VERSION "dbc-export 1 2026.26.6.5"

NS_ :

BS_:

BU_: ADSP APB APP APS APSB BB BMS CC CMP CMPD CP DAS DI DIF DIR DPB EPAS3P EPAS3S EPASTP EPASTS EPBL EPBR ESP EVSE FC GTW HCML HCMR HVP IBST ICR IDB LS OCS1P ODIN PARK PCS PCS2 PLG PM PMF PMR PNCD PTC RADC RCM RCM2 RCM3 RCU SCCM SCM SCS SDCR TAS TCU TCU2 TPMS TRCM UDS UI UIS UMC USM V2G VC VCBATT VCBATT0 VCBATT1 VCBATT2 VCCC VCFRONT VCFRONT1 VCFRONT2 VCLEFT VCRIGHT VCSEAT2L VCSEAT2R VCSEC VEH

BO_ 1113 APS_warningMatrix2: 8 APS
 SG_ APS_w129_ECU_Power_Issue : 0|1@1+ (1,0) [0|1] "" Vector__XXX
 SG_ APS_w130_ECU_Thermal_Issue : 1|1@1+ (1,0) [0|1] "" Vector__XXX
 SG_ APS_w131_trap_exception : 2|1@1+ (1,0) [0|1] "" Vector__XXX
 SG_ APS_w132_appVersionMismatch : 3|1@1+ (1,0) [0|1] "" Vector__XXX
 SG_ APS_w133_ETHSwitchError : 4|1@1+ (1,0) [0|1] "" Vector__XXX
 SG_ APS_w134_appMia : 5|1@1+ (1,0) [0|1] "" Vector__XXX
 SG_ APS_w135_appCritical : 6|1@1+ (1,0) [0|1] "" Vector__XXX
 SG_ APS_w136_gpsDisabled : 7|1@1+ (1,0) [0|1] "" Vector__XXX
 SG_ APS_w137_gpsFaultReset : 8|1@1+ (1,0) [0|1] "" Vector__XXX
 SG_ APS_w138_gpsComIssue : 9|1@1+ (1,0) [0|1] "" Vector__XXX
 SG_ APS_w139_udpBufferOverflow : 10|1@1+ (1,0) [0|1] "" Vector__XXX
 SG_ APS_w140_vcfrontMiaVehicleBus : 11|1@1+ (1,0) [0|1] "" Vector__XXX
 SG_ APS_w141_rcmMiaPartyBus : 12|1@1+ (1,0) [0|1] "" Vector__XXX
 SG_ APS_w142_diMiaPartyBus : 13|1@1+ (1,0) [0|1] "" Vector__XXX
 SG_ APS_w143_espMiaPartyBus : 14|1@1+ (1,0) [0|1] "" Vector__XXX
 SG_ APS_w144_vcleftMiaPartyBus : 15|1@1+ (1,0) [0|1] "" Vector__XXX
 SG_ APS_w145_vcrightMiaPartyBus : 16|1@1+ (1,0) [0|1] "" Vector__XXX
 SG_ APS_w146_epas3pMiaPartyBus : 17|1@1+ (1,0) [0|1] "" Vector__XXX
 SG_ APS_w147_vcleftMiaVehBus : 18|1@1+ (1,0) [0|1] "" Vector__XXX
 SG_ APS_w148_vcrightMiaVehBus : 19|1@1+ (1,0) [0|1] "" Vector__XXX
 SG_ APS_w149_epblMiaVehBus : 20|1@1+ (1,0) [0|1] "" Vector__XXX
 SG_ APS_w150_sccmMiaVehBus : 21|1@1+ (1,0) [0|1] "" Vector__XXX
 SG_ APS_w151_apRecovered : 22|1@1+ (1,0) [0|1] "" Vector__XXX
 SG_ APS_w152_gpsFusionStatus : 23|1@1+ (1,0) [0|1] "" Vector__XXX
 SG_ APS_w153_eacInhibit : 24|1@1+ (1,0) [0|1] "" Vector__XXX
 SG_ APS_w155_ethLwipError : 26|1@1+ (1,0) [0|1] "" Vector__XXX
 SG_ APS_w156_lwipAssert : 27|1@1+ (1,0) [0|1] "" Vector__XXX
 SG_ APS_w157_autopilotReboot : 28|1@1+ (1,0) [0|1] "" Vector__XXX
 SG_ APS_w158_apbMia : 29|1@1+ (1,0) [0|1] "" Vector__XXX
 SG_ APS_w159_apbCritical : 30|1@1+ (1,0) [0|1] "" Vector__XXX
 SG_ APS_w160_apbVersionMismatch : 31|1@1+ (1,0) [0|1] "" Vector__XXX
 SG_ APS_w161_gpsAntennaDisconnected : 32|1@1+ (1,0) [0|1] "" Vector__XXX
 SG_ APS_w162_TurboA_DisRegPgoodErr : 33|1@1+ (1,0) [0|1] "" Vector__XXX
 SG_ APS_w163_TurboA_DisRegNFault : 34|1@1+ (1,0) [0|1] "" Vector__XXX
 SG_ APS_w164_TurboA_12VFuseFault : 35|1@1+ (1,0) [0|1] "" Vector__XXX
 SG_ APS_w165_TurboA_Temp_NOS : 36|1@1+ (1,0) [0|1] "" Vector__XXX
 SG_ APS_w166_TurboA_SMSLockStepErr : 37|1@1+ (1,0) [0|1] "" Vector__XXX
 SG_ APS_w167_TurboA_TMU_Throttle : 38|1@1+ (1,0) [0|1] "" Vector__XXX
 SG_ APS_w168_TurboA_SMS_WDOG : 39|1@1+ (1,0) [0|1] "" Vector__XXX
 SG_ APS_w169_TurboA_SCS_LKUP : 40|1@1+ (1,0) [0|1] "" Vector__XXX
 SG_ APS_w170_TurboA_A72_watchdog : 41|1@1+ (1,0) [0|1] "" Vector__XXX
 SG_ APS_w171_TurboA_SMS_taskUtilErr : 42|1@1+ (1,0) [0|1] "" Vector__XXX
 SG_ APS_w172_apFeaturesUnavailable : 43|1@1+ (1,0) [0|1] "" Vector__XXX
 SG_ APS_w178_TurboB_DisRegPgoodErr : 49|1@1+ (1,0) [0|1] "" Vector__XXX
 SG_ APS_w179_TurboB_DisRegNFault : 50|1@1+ (1,0) [0|1] "" Vector__XXX
 SG_ APS_w180_TurboB_12VFuseFault : 51|1@1+ (1,0) [0|1] "" Vector__XXX
 SG_ APS_w181_TurboB_Temp_NOS : 52|1@1+ (1,0) [0|1] "" Vector__XXX
 SG_ APS_w182_TurboB_SMSLockStepErr : 53|1@1+ (1,0) [0|1] "" Vector__XXX
 SG_ APS_w183_TurboB_TMU_Throttle : 54|1@1+ (1,0) [0|1] "" Vector__XXX
 SG_ APS_w184_TurboB_SMS_WDOG : 55|1@1+ (1,0) [0|1] "" Vector__XXX
 SG_ APS_w185_TurboB_SCS_LKUP : 56|1@1+ (1,0) [0|1] "" Vector__XXX
 SG_ APS_w186_TurboB_A72_watchdog : 57|1@1+ (1,0) [0|1] "" Vector__XXX
 SG_ APS_w187_TurboB_SMS_taskUtilErr : 58|1@1+ (1,0) [0|1] "" Vector__XXX
 SG_ APS_w188_otherTurboUartMIA : 59|1@1+ (1,0) [0|1] "" Vector__XXX
 SG_ APS_w189_vcfrontMiaPartyBus : 60|1@1+ (1,0) [0|1] "" Vector__XXX
 SG_ APS_w190_iboosterMia : 61|1@1+ (1,0) [0|1] "" Vector__XXX
 SG_ APS_w191_timesyncError : 62|1@1+ (1,0) [0|1] "" Vector__XXX
 SG_ APS_w192_CANFault : 63|1@1+ (1,0) [0|1] "" Vector__XXX

BO_ 848 APS_warningMatrix3: 8 APS
 SG_ APS_w193_camWindshieldUnclean : 0|1@1+ (1,0) [0|1] "" Vector__XXX
 SG_ APS_w194_accDriverResumeRqrd : 1|1@1+ (1,0) [0|1] "" Vector__XXX
 SG_ APS_w195_scwUnavailable : 2|1@1+ (1,0) [0|1] "" Vector__XXX
 SG_ APS_w196_stopSignWarning : 3|1@1+ (1,0) [0|1] "" Vector__XXX
 SG_ APS_w197_redLightWarning : 4|1@1+ (1,0) [0|1] "" Vector__XXX
 SG_ APS_w198_tsrUnavailable : 5|1@1+ (1,0) [0|1] "" Vector__XXX
 SG_ APS_w199_apcAbort : 6|1@1+ (1,0) [0|1] "" Vector__XXX
 SG_ APS_w200_lcSlowdown : 7|1@1+ (1,0) [0|1] "" Vector__XXX
 SG_ APS_w201_lcAborting : 8|1@1+ (1,0) [0|1] "" Vector__XXX
 SG_ APS_w202_scwNoisyEnvironment : 9|1@1+ (1,0) [0|1] "" Vector__XXX
 SG_ APS_w203_apcActivation : 10|1@1+ (1,0) [0|1] "" Vector__XXX
 SG_ APS_w204_apcFinalFront : 11|1@1+ (1,0) [0|1] "" Vector__XXX
 SG_ APS_w205_apcFinalRear : 12|1@1+ (1,0) [0|1] "" Vector__XXX
 SG_ APS_w206_autosteerNotEnabled : 13|1@1+ (1,0) [0|1] "" Vector__XXX
 SG_ APS_w207_autosteerUnavailable : 14|1@1+ (1,0) [0|1] "" Vector__XXX
 SG_ APS_w208_rackDetected : 15|1@1+ (1,0) [0|1] "" Vector__XXX
 SG_ APS_w209_autoSummonRequest : 16|1@1+ (1,0) [0|1] "" Vector__XXX
 SG_ APS_w210_camObstrcted : 17|1@1+ (1,0) [0|1] "" Vector__XXX
 SG_ APS_w211_accNoSeatBelt : 18|1@1+ (1,0) [0|1] "" Vector__XXX
 SG_ APS_w212_lcUnavailableStrikeOut : 19|1@1+ (1,0) [0|1] "" Vector__XXX
 SG_ APS_w213_autosteerStruckOut : 20|1@1+ (1,0) [0|1] "" Vector__XXX
 SG_ APS_w214_driverNotIntracting : 21|1@1+ (1,0) [0|1] "" Vector__XXX
 SG_ APS_w215_contDriverNotIntracting : 22|1@1+ (1,0) [0|1] "" Vector__XXX
 SG_ APS_w216_driverOverriding : 23|1@1+ (1,0) [0|1] "" Vector__XXX
 SG_ APS_w217_lcUnavailableSpeeding : 24|1@1+ (1,0) [0|1] "" Vector__XXX
 SG_ APS_w218_lcSpeedExceededLimit : 25|1@1+ (1,0) [0|1] "" Vector__XXX
 SG_ APS_w219_lcTempUnavailableSpeed : 26|1@1+ (1,0) [0|1] "" Vector__XXX
 SG_ APS_w220_lcTempUnavailableRoad : 27|1@1+ (1,0) [0|1] "" Vector__XXX
 SG_ APS_w221_accRadarBlind : 28|1@1+ (1,0) [0|1] "" Vector__XXX
 SG_ APS_w222_accCameraBlind : 29|1@1+ (1,0) [0|1] "" Vector__XXX
 SG_ APS_w223_accObjectInPath : 30|1@1+ (1,0) [0|1] "" Vector__XXX
 SG_ APS_w224_accCameraCalibration : 31|1@1+ (1,0) [0|1] "" Vector__XXX
 SG_ APS_w225_lcDegradedVisSpeedLmt : 32|1@1+ (1,0) [0|1] "" Vector__XXX
 SG_ APS_w226_lcCamCalNeededSpeedLmt : 33|1@1+ (1,0) [0|1] "" Vector__XXX
 SG_ APS_w227_virtualWallBlocked : 34|1@1+ (1,0) [0|1] "" Vector__XXX
 SG_ APS_w228_DEPRECATED : 35|1@1+ (1,0) [0|1] "" Vector__XXX
 SG_ APS_w229_alcUltrasoundDamaged : 36|1@1+ (1,0) [0|1] "" Vector__XXX
 SG_ APS_w230_alcUltrasoundBlocked : 37|1@1+ (1,0) [0|1] "" Vector__XXX
 SG_ APS_w231_idfEvent : 38|1@1+ (1,0) [0|1] "" Vector__XXX
 SG_ APS_w232_laneChangeRequested : 39|1@1+ (1,0) [0|1] "" Vector__XXX
 SG_ APS_w235_a72LoopDetected : 42|1@1+ (1,0) [0|1] "" Vector__XXX
 SG_ APS_w236_canSharedMemError : 43|1@1+ (1,0) [0|1] "" Vector__XXX
 SG_ APS_w237_faultMgrEventDetected : 44|1@1+ (1,0) [0|1] "" Vector__XXX
 SG_ APS_w238_resetReason : 45|1@1+ (1,0) [0|1] "" Vector__XXX
 SG_ APS_w241_ddrInitFailures : 48|1@1+ (1,0) [0|1] "" Vector__XXX
 SG_ APS_w242_tripMBISTFailure : 49|1@1+ (1,0) [0|1] "" Vector__XXX
 SG_ APS_w243_tripHWErrorStatus : 50|1@1+ (1,0) [0|1] "" Vector__XXX
 SG_ APS_w244_gpuHWFaultStatus : 51|1@1+ (1,0) [0|1] "" Vector__XXX
 SG_ APS_w245_eloopRxFromUnexpectedSo : 52|1@1+ (1,0) [0|1] "" Vector__XXX
 SG_ APS_w246_ethloopSwitchPortLinkDo : 53|1@1+ (1,0) [0|1] "" Vector__XXX
 SG_ APS_w247_ethernetFrameError : 54|1@1+ (1,0) [0|1] "" Vector__XXX
 SG_ APS_w248_ethloopSwitchPoorSqi : 55|1@1+ (1,0) [0|1] "" Vector__XXX
 SG_ APS_w249_ufsFailures : 56|1@1+ (1,0) [0|1] "" Vector__XXX
 SG_ APS_w250_ethloopSwitchMemUsageTo : 57|1@1+ (1,0) [0|1] "" Vector__XXX
 SG_ APS_w251_ethloopSwitchMemUsageTo : 58|1@1+ (1,0) [0|1] "" Vector__XXX
 SG_ APS_w252_ethSwitchPortLinkDown : 59|1@1+ (1,0) [0|1] "" Vector__XXX
 SG_ APS_w253_powerStateTimeout : 60|1@1+ (1,0) [0|1] "" Vector__XXX
 SG_ APS_w254_sleepStateTimeout : 61|1@1+ (1,0) [0|1] "" Vector__XXX
 SG_ APS_w255_bootHealth : 62|1@1+ (1,0) [0|1] "" Vector__XXX

BO_ 784 APS_warningMatrix4: 8 APS
 SG_ APS_w257_assertFailure : 0|1@1+ (1,0) [0|1] "" Vector__XXX
 SG_ APS_w258_qspiFlashSectorChecksum : 1|1@1+ (1,0) [0|1] "" Vector__XXX
 SG_ APS_w259_qspiFailure : 2|1@1+ (1,0) [0|1] "" Vector__XXX
 SG_ APS_w260_pgoodFailure : 3|1@1+ (1,0) [0|1] "" Vector__XXX
 SG_ APS_w261_vrmFaultGrpA : 4|1@1+ (1,0) [0|1] "" Vector__XXX
 SG_ APS_w262_vrmFaultGrpB : 5|1@1+ (1,0) [0|1] "" Vector__XXX
 SG_ APS_w263_vrmFaultGrpC : 6|1@1+ (1,0) [0|1] "" Vector__XXX
 SG_ APS_w264_ddrPhy0Failures : 7|1@1+ (1,0) [0|1] "" Vector__XXX
 SG_ APS_w265_ddrPhy1Failures : 8|1@1+ (1,0) [0|1] "" Vector__XXX
 SG_ APS_w266_ddrPhy2Failures : 9|1@1+ (1,0) [0|1] "" Vector__XXX
 SG_ APS_w267_ddrPhy3Failures : 10|1@1+ (1,0) [0|1] "" Vector__XXX
 SG_ APS_w268_ddrControllerFailures : 11|1@1+ (1,0) [0|1] "" Vector__XXX
 SG_ APS_w269_ethSwitchRxPageCountToo : 12|1@1+ (1,0) [0|1] "" Vector__XXX
 SG_ APS_w270_ethSwitchRxPageCountToo : 13|1@1+ (1,0) [0|1] "" Vector__XXX
 SG_ APS_w271_ddrScheduler0EccErrors : 14|1@1+ (1,0) [0|1] "" Vector__XXX
 SG_ APS_w272_ddrScheduler1EccErrors : 15|1@1+ (1,0) [0|1] "" Vector__XXX
 SG_ APS_w273_ddrScheduler2EccErrors : 16|1@1+ (1,0) [0|1] "" Vector__XXX
 SG_ APS_w274_ddrScheduler3EccErrors : 17|1@1+ (1,0) [0|1] "" Vector__XXX
 SG_ APS_w275_ddrScheduler4EccErrors : 18|1@1+ (1,0) [0|1] "" Vector__XXX
 SG_ APS_w276_ddrScheduler5EccErrors : 19|1@1+ (1,0) [0|1] "" Vector__XXX
 SG_ APS_w277_ddrScheduler6EccErrors : 20|1@1+ (1,0) [0|1] "" Vector__XXX
 SG_ APS_w278_ddrScheduler7EccErrors : 21|1@1+ (1,0) [0|1] "" Vector__XXX
 SG_ APS_w279_ufsPartitionError : 22|1@1+ (1,0) [0|1] "" Vector__XXX
 SG_ APS_w280_pepsMia : 23|1@1+ (1,0) [0|1] "" Vector__XXX
 SG_ APS_w281_rsaMia : 24|1@1+ (1,0) [0|1] "" Vector__XXX
 SG_ APS_w282_smmuError : 25|1@1+ (1,0) [0|1] "" Vector__XXX
 SG_ APS_w283_psfaMia : 26|1@1+ (1,0) [0|1] "" Vector__XXX
 SG_ APS_w284_cam12VBuckBoostAPwrIssu : 27|1@1+ (1,0) [0|1] "" Vector__XXX
 SG_ APS_w285_cam12VBuckBoostBPwrIssu : 28|1@1+ (1,0) [0|1] "" Vector__XXX
 SG_ APS_w286_cam12VEFuseAPrimaryIssu : 29|1@1+ (1,0) [0|1] "" Vector__XXX
 SG_ APS_w287_cam12VEFuseASecondaryIs : 30|1@1+ (1,0) [0|1] "" Vector__XXX
 SG_ APS_w288_brakeboosterMia : 31|1@1+ (1,0) [0|1] "" Vector__XXX
 SG_ APS_w289_turboTemperatureWarning : 32|1@1+ (1,0) [0|1] "" Vector__XXX
 SG_ APS_w290_cam12VBuckBoostBPwrRing : 33|1@1+ (1,0) [0|1] "" Vector__XXX
 SG_ APS_w291_eplannerError : 34|1@1+ (1,0) [0|1] "" Vector__XXX
 SG_ APS_w292_CH_busOff : 35|1@1+ (1,0) [0|1] "" Vector__XXX
 SG_ APS_w293_PARTY_busOff : 36|1@1+ (1,0) [0|1] "" Vector__XXX
 SG_ APS_w294_VEH_busOff : 37|1@1+ (1,0) [0|1] "" Vector__XXX
 SG_ APS_w295_PT_busOff : 38|1@1+ (1,0) [0|1] "" Vector__XXX
 SG_ APS_w296_wdogMonTaskDeadlineMiss : 39|1@1+ (1,0) [0|1] "" Vector__XXX
 SG_ APS_w297_earlyWDogAlert : 40|1@1+ (1,0) [0|1] "" Vector__XXX
 SG_ APS_w298_cpuToApCanSharedMemErro : 41|1@1+ (1,0) [0|1] "" Vector__XXX
 SG_ APS_w299_apToCpuCanSharedMemErro : 42|1@1+ (1,0) [0|1] "" Vector__XXX
 SG_ APS_w300_sharedMemoryAccessError : 43|1@1+ (1,0) [0|1] "" Vector__XXX
 SG_ APS_w301_nocTimeoutDetected : 44|1@1+ (1,0) [0|1] "" Vector__XXX
 SG_ APS_w302_canAPShmFifoFull : 45|1@1+ (1,0) [0|1] "" Vector__XXX
 SG_ APS_w303_canAPShmFifoEmpty : 46|1@1+ (1,0) [0|1] "" Vector__XXX
 SG_ APS_w304_dataAbort : 47|1@1+ (1,0) [0|1] "" Vector__XXX
 SG_ APS_w305_gpsPgoodFailure : 48|1@1+ (1,0) [0|1] "" Vector__XXX
 SG_ APS_w306_ethPgoodFailure : 49|1@1+ (1,0) [0|1] "" Vector__XXX
 SG_ APS_w307_eccEventDetected : 50|1@1+ (1,0) [0|1] "" Vector__XXX
 SG_ APS_w308_pmicErrorDetected : 51|1@1+ (1,0) [0|1] "" Vector__XXX
 SG_ APS_w309_ethBridgeDown : 52|1@1+ (1,0) [0|1] "" Vector__XXX
 SG_ APS_w310_wakeBootMetrics : 53|1@1+ (1,0) [0|1] "" Vector__XXX
 SG_ APS_w311_apbdgDasMia : 54|1@1+ (1,0) [0|1] "" Vector__XXX
 SG_ APS_w312_apbdgApMia : 55|1@1+ (1,0) [0|1] "" Vector__XXX
 SG_ APS_w313_BDY_busOff : 56|1@1+ (1,0) [0|1] "" Vector__XXX
 SG_ APS_w315_epas3pMiaBdyBus : 58|1@1+ (1,0) [0|1] "" Vector__XXX
 SG_ APS_w316_apBootHealth : 59|1@1+ (1,0) [0|1] "" Vector__XXX
 SG_ APS_w317_uiMia : 60|1@1+ (1,0) [0|1] "" Vector__XXX
 SG_ APS_w318_ethernetNetworkBufferHi : 61|1@1+ (1,0) [0|1] "" Vector__XXX
 SG_ APS_w319_vehDasImposterDetected : 62|1@1+ (1,0) [0|1] "" Vector__XXX
 SG_ APS_w320_eplannerPreconditionsMe : 63|1@1+ (1,0) [0|1] "" Vector__XXX

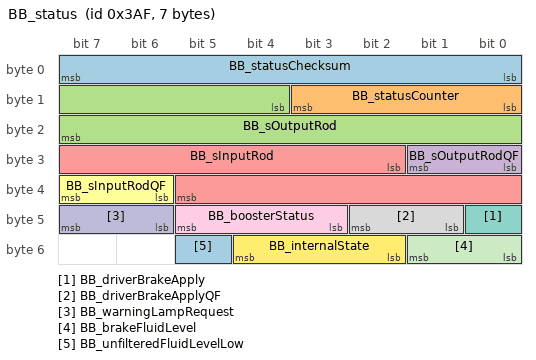
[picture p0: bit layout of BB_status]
BO_ 943 BB_status: 7 BB
 SG_ BB_statusChecksum : 0|8@1+ (1,0) [0|255] "" Vector__XXX
 SG_ BB_statusCounter : 8|4@1+ (1,0) [0|15] "" Vector__XXX
 SG_ BB_sOutputRod : 12|12@1+ (0.015625,-5) [-5|47] "mm" Vector__XXX
 SG_ BB_sOutputRodQF : 24|2@1+ (1,0) [0|3] "" Vector__XXX
 SG_ BB_sInputRod : 26|12@1+ (0.015625,-5) [-5|47] "mm" Vector__XXX
 SG_ BB_sInputRodQF : 38|2@1+ (1,0) [0|3] "" Vector__XXX
 SG_ BB_driverBrakeApply : 40|1@1+ (1,0) [0|1] "" Vector__XXX
 SG_ BB_driverBrakeApplyQF : 41|2@1+ (1,0) [0|3] "" Vector__XXX
 SG_ BB_boosterStatus : 43|3@1+ (1,0) [0|7] "" Vector__XXX
 SG_ BB_warningLampRequest : 46|2@1+ (1,0) [0|3] "" Vector__XXX
 SG_ BB_brakeFluidLevel : 48|2@1+ (1,0) [0|3] "" Vector__XXX
 SG_ BB_internalState : 50|3@1+ (1,0) [0|7] "" Vector__XXX
 SG_ BB_unfilteredFluidLevelLow : 53|1@1+ (1,0) [0|1] "" Vector__XXX

BO_ 1343 BMS_alertLog: 8 BMS
 SG_ BMS_alertID M : 0|9@1+ (1,0) [0|511] "" Vector__XXX
 SG_ BMS_alertSet : 15|1@1+ (1,0) [0|1] "" Vector__XXX
 SG_ BMS_a001_gatewayPackEnergy m1 : 16|2@1+ (1,0) [0|3] "" Vector__XXX
 SG_ BMS_a001_expectedPackEnergy m1 : 18|2@1+ (1,0) [0|3] "" Vector__XXX
 SG_ BMS_a002_gatewayPackPerformanceD m2 : 16|3@1+ (1,0) [0|7] "" Vector__XXX
 SG_ BMS_a002_expectedPackPerformance m2 : 19|3@1+ (1,0) [0|7] "" Vector__XXX
 SG_ BMS_a002_bmsPackMass m2 : 24|8@1+ (1,300) [300|555] "kg" Vector__XXX
 SG_ BMS_a003_calBlockData_0 m3 : 16|32@1+ (1,0) [0|4294967295] "" Vector__XXX
 SG_ BMS_a017_packCurrent m17 : 16|8@1+ (8,-1500) [-1500|540] "A" Vector__XXX
 SG_ BMS_a017_ovBrickVID m17 : 24|7@1+ (1,1) [1|128] "" Vector__XXX
 SG_ BMS_a017_ovBrickV m17 : 32|16@1+ (7.62939453125e-05,0) [0|4.99992370605] "V" Vector__XXX
 SG_ BMS_a018_packCurrent m18 : 16|8@1+ (8,-1496) [-1496|544] "A" Vector__XXX
 SG_ BMS_a018_uvBrickVID m18 : 24|7@1+ (1,1) [1|128] "" Vector__XXX
 SG_ BMS_a018_uvBrickV m18 : 32|16@1+ (7.62939453125e-05,0) [0|4.99992370605] "V" Vector__XXX
 SG_ BMS_a019_coolantInletT m19 : 16|8@1+ (0.4,-20) [-20|82] "C" Vector__XXX
 SG_ BMS_a019_activeCoolingTarget m19 : 24|8@1+ (0.4,-20) [-20|82] "C" Vector__XXX
 SG_ BMS_a019_maxBrickT m19 : 32|8@1+ (0.4,-20) [-20|82] "C" Vector__XXX
 SG_ BMS_a019_maxBrickTID m19 : 40|5@1+ (1,1) [1|32] "" Vector__XXX
 SG_ BMS_a021_chargeViolation m21 : 16|1@1+ (1,0) [0|1] "" Vector__XXX
 SG_ BMS_a021_currentLimit m21 : 24|8@1+ (8,-1496) [-1496|544] "A" Vector__XXX
 SG_ BMS_a021_packCurrent m21 : 32|8@1+ (8,-1496) [-1496|544] "A" Vector__XXX
 SG_ BMS_a022_chargeAccumulatorViolat m22 : 16|1@1+ (1,0) [0|1] "" Vector__XXX
 SG_ BMS_a022_chargeAccumulatorValue m22 : 17|23@1+ (10,0) [0|83886070] "A^2s" Vector__XXX
 SG_ BMS_a022_chargeAccumulatorLimit m22 : 40|23@1+ (10,0) [0|83886070] "A^2s" Vector__XXX
 SG_ BMS_a023_ovStackDeviceID m23 : 16|5@1+ (1,1) [1|32] "-" Vector__XXX
 SG_ BMS_a023_ovStackV m23 : 24|16@1+ (0.00128,0) [0|83.8848] "V" Vector__XXX
 SG_ BMS_a024_brickID m24 : 16|8@1+ (1,1) [1|256] "-" Vector__XXX
 SG_ BMS_a024_deltaV m24 : 24|16@1- (0.0001,0) [-3.2768|3.2767] "V" Vector__XXX
 SG_ BMS_a024_avgDvPrev m24 : 40|16@1- (0.0001,0) [-3.2768|3.2767] "V" Vector__XXX
 SG_ BMS_a024_packCurrent m24 : 56|8@1+ (8,-1500) [-1500|540] "A" Vector__XXX
 SG_ BMS_a027_swIsolationCount m27 : 16|8@1+ (1,0) [0|255] "" Vector__XXX
 SG_ BMS_a030_worstBrickID m30 : 16|8@1+ (1,1) [1|256] "" Vector__XXX
 SG_ BMS_a030_maxBrickImpedance m30 : 24|10@1+ (0.1,0) [0|102.3] "mOhm" Vector__XXX
 SG_ BMS_a030_maxNormalizedImpedanceD m30 : 34|7@1+ (0.04,0) [0|5.08] "Ratio" Vector__XXX
 SG_ BMS_a030_faultThreshold m30 : 41|7@1+ (0.04,0) [0|5.08] "Ratio" Vector__XXX
 SG_ BMS_a030_numBricks m30 : 48|8@1+ (1,0) [0|255] "" Vector__XXX
 SG_ BMS_a030_worstBrickSoc m30 : 56|8@1+ (0.5,0) [0|127.5] "PCT" Vector__XXX
 SG_ BMS_a035_isoR m35 : 16|9@1+ (10,0) [0|5110] "kOhm" Vector__XXX
 SG_ BMS_a035_mode m35 : 25|3@1+ (1,0) [0|7] "" Vector__XXX
 SG_ BMS_a035_activeSideVNoR m35 : 28|9@1+ (1,0) [0|511] "V" Vector__XXX
 SG_ BMS_a035_activeSideVWithR m35 : 37|9@1+ (1,0) [0|511] "V" Vector__XXX
 SG_ BMS_a035_passiveSideVNoR m35 : 46|9@1+ (1,0) [0|511] "V" Vector__XXX
 SG_ BMS_a035_passiveSideVWithR m35 : 55|9@1+ (1,0) [0|511] "V" Vector__XXX
 SG_ BMS_a039_dcLinkVoltage m39 : 16|10@1+ (1,0) [0|1023] "V" Vector__XXX
 SG_ BMS_a039_packVoltage m39 : 26|10@1+ (1,0) [0|1023] "V" Vector__XXX
 SG_ BMS_a039_packContactorState m39 : 36|4@1+ (1,0) [1|15] "" Vector__XXX
 SG_ BMS_a039_packCurrent m39 : 40|8@1+ (8,-1496) [-1496|544] "A" Vector__XXX
 SG_ BMS_a039_maxBrickV m39 : 48|8@1+ (0.01,2) [2|4.55] "V" Vector__XXX
 SG_ BMS_a039_state m39 : 56|4@1+ (1,0) [0|15] "" Vector__XXX
 SG_ BMS_a041_resetType m41 : 16|4@1+ (1,0) [0|15] "" Vector__XXX
 SG_ BMS_a050_MIA_numBadReadings m50 : 16|8@1+ (1,0) [0|255] "" Vector__XXX
 SG_ BMS_a050_MIA_numSnaReadings m50 : 24|8@1+ (1,0) [0|255] "" Vector__XXX
 SG_ BMS_a050_MIA_brickId m50 : 32|8@1+ (1,1) [1|256] "" Vector__XXX
 SG_ BMS_a051_hvp1V5Ref m51 : 16|12@1+ (0.001,0) [0|4.095] "V" Vector__XXX
 SG_ BMS_a051_hvp3V0Ref m51 : 28|12@1+ (0.001,0) [0|4.095] "V" Vector__XXX
 SG_ BMS_a051_bms3V0Ref m51 : 40|12@1+ (0.001,0) [0|4.095] "V" Vector__XXX
 SG_ BMS_a059_sumBrickVoltages m59 : 16|16@1+ (0.01,0) [0|655.35] "V" Vector__XXX
 SG_ BMS_a059_packVoltage m59 : 32|16@1+ (0.01,0) [0|655.35] "V" Vector__XXX
 SG_ BMS_a062_state m62 : 16|4@1+ (1,0) [0|15] "" Vector__XXX
 SG_ BMS_a062_minBrickVId m62 : 24|7@1+ (1,1) [1|128] "" Vector__XXX
 SG_ BMS_a062_minBrickVoltage m62 : 32|12@1+ (0.002,0) [0|8.19] "V" Vector__XXX
 SG_ BMS_a062_maxBrickVId m62 : 44|7@1+ (1,1) [1|128] "" Vector__XXX
 SG_ BMS_a062_maxBrickVoltage m62 : 51|12@1+ (0.002,0) [0|8.19] "V" Vector__XXX
 SG_ BMS_a063_cpFaultInV m63 : 16|12@1+ (0.001,0) [0|4.095] "V" Vector__XXX
 SG_ BMS_a064_minBrickSOCID m64 : 16|7@1+ (1,1) [1|128] "" Vector__XXX
 SG_ BMS_a064_minBrickSOC m64 : 24|8@1+ (0.5,0) [0|127.5] "PCT" Vector__XXX
 SG_ BMS_a064_maxBrickSOCID m64 : 32|7@1+ (1,1) [1|128] "" Vector__XXX
 SG_ BMS_a064_maxBrickSOC m64 : 40|8@1+ (0.5,0) [0|127.5] "PCT" Vector__XXX
 SG_ BMS_a064_avgBrickSOC m64 : 48|8@1+ (0.5,0) [0|127.5] "PCT" Vector__XXX
 SG_ BMS_a065_minBrickCacId m65 : 16|7@1+ (1,1) [1|128] "" Vector__XXX
 SG_ BMS_a065_minBrickCac m65 : 24|13@1+ (0.1,0) [0|819.1] "Ah" Vector__XXX
 SG_ BMS_a065_avgBrickCac m65 : 40|13@1+ (0.1,0) [0|819.1] "Ah" Vector__XXX
 SG_ BMS_a065_modCacImbalancePct m65 : 53|10@1+ (0.1,0) [0|102.3] "%" Vector__XXX
 SG_ BMS_a066_minBrickSocId m66 : 16|7@1+ (1,1) [1|128] "" Vector__XXX
 SG_ BMS_a066_minBrickSocByOcvMax m66 : 24|8@1+ (0.5,0) [0|127.5] "PCT" Vector__XXX
 SG_ BMS_a066_maxBrickSocId m66 : 32|7@1+ (1,1) [1|128] "" Vector__XXX
 SG_ BMS_a066_maxBrickSocByOcvMin m66 : 40|8@1+ (0.5,0) [0|127.5] "PCT" Vector__XXX
 SG_ BMS_a066_maxBrickSoc m66 : 48|8@1+ (0.5,0) [0|127.5] "PCT" Vector__XXX
 SG_ BMS_a066_avgBrickSoc m66 : 56|8@1+ (0.5,0) [0|127.5] "PCT" Vector__XXX
 SG_ BMS_a067_minBrickCacId m67 : 16|7@1+ (1,1) [1|128] "" Vector__XXX
 SG_ BMS_a067_minBrickCac m67 : 24|13@1+ (0.1,0) [0|819.1] "Ah" Vector__XXX
 SG_ BMS_a067_avgBrickCac m67 : 40|13@1+ (0.1,0) [0|819.1] "Ah" Vector__XXX
 SG_ BMS_a067_modCacImbalancePct m67 : 53|10@1+ (0.1,0) [0|102.3] "%" Vector__XXX
 SG_ BMS_a068_minBrickCacId m68 : 16|7@1+ (1,1) [1|128] "" Vector__XXX
 SG_ BMS_a068_minBrickCac m68 : 24|13@1+ (0.1,0) [0|819.1] "Ah" Vector__XXX
 SG_ BMS_a068_avgBrickCac m68 : 40|13@1+ (0.1,0) [0|819.1] "Ah" Vector__XXX
 SG_ BMS_a068_modCacImbalancePct m68 : 53|10@1+ (0.1,0) [0|102.3] "%" Vector__XXX
 SG_ BMS_a069_dischargePowerPackVolta m69 : 16|8@1- (0.025,-3.15) [-6.35|0.025] "kW" Vector__XXX
 SG_ BMS_a069_dischargePowerBrickVolt m69 : 24|8@1- (0.005,-0.63) [-1.27|0.005] "kW" Vector__XXX
 SG_ BMS_a069_SOC m69 : 32|8@1+ (0.05,0) [0|12.75] "PCT" Vector__XXX
 SG_ BMS_a069_minBrickT m69 : 40|8@1- (0.5,24) [-40|87.5] "DegC" Vector__XXX
 SG_ BMS_a069_minBrickVLimit m69 : 48|8@1+ (0.01,2) [2|4.55] "V" Vector__XXX
 SG_ BMS_a069_minBrickV m69 : 56|8@1+ (0.01,2) [2|4.55] "V" Vector__XXX
 SG_ BMS_a070_state m70 : 16|4@1+ (1,0) [0|15] "" Vector__XXX
 SG_ BMS_a070_minBrickVId m70 : 24|7@1+ (1,1) [1|128] "" Vector__XXX
 SG_ BMS_a070_minBrickVoltage m70 : 32|12@1+ (0.002,0) [0|8.19] "V" Vector__XXX
 SG_ BMS_a070_maxBrickVId m70 : 44|7@1+ (1,1) [1|128] "" Vector__XXX
 SG_ BMS_a070_maxBrickVoltage m70 : 51|12@1+ (0.002,0) [0|8.19] "V" Vector__XXX
 SG_ BMS_a071_stateRequest m71 : 16|4@1+ (1,0) [0|15] "" Vector__XXX
 SG_ BMS_a071_state m71 : 20|4@1+ (1,0) [0|15] "" Vector__XXX
 SG_ BMS_a071_transitionAlertId m71 : 24|10@1+ (1,0) [0|1023] "" Vector__XXX
 SG_ BMS_a074_maxBrickVTarget m74 : 16|8@1+ (0.01,2) [2|4.55] "V" Vector__XXX
 SG_ BMS_a074_maxBrickV m74 : 24|8@1+ (0.01,2) [2|4.55] "V" Vector__XXX
 SG_ BMS_a075_chargeType m75 : 16|1@1+ (1,0) [0|1] "" Vector__XXX
 SG_ BMS_a076_netAh m76 : 16|21@1- (0.01,0) [-10485.76|10485.75] "Ah" Vector__XXX
 SG_ BMS_a076_tetheringActive m76 : 37|1@1+ (1,0) [0|1] "" Vector__XXX
 SG_ BMS_a077_chargeErrType m77 : 16|1@1+ (1,0) [0|1] "" Vector__XXX
 SG_ BMS_a077_maxBrickVTarget m77 : 24|8@1+ (0.01,2) [2|4.55] "V" Vector__XXX
 SG_ BMS_a077_maxBrickV m77 : 32|8@1+ (0.01,2) [2|4.55] "V" Vector__XXX
 SG_ BMS_a077_packTargetCurrent m77 : 40|8@1+ (8,-1496) [-1496|544] "A" Vector__XXX
 SG_ BMS_a077_packCurrent m77 : 48|8@1+ (8,-1496) [-1496|544] "A" Vector__XXX
 SG_ BMS_a078_peakDchInChg m78 : 16|16@1- (0.1,0) [-3276.8|3276.7] "A" Vector__XXX
 SG_ BMS_a079_maxBrickVTarget m79 : 16|8@1+ (0.01,2) [2|4.55] "V" Vector__XXX
 SG_ BMS_a079_maxBrickV m79 : 24|8@1+ (0.01,2) [2|4.55] "V" Vector__XXX
 SG_ BMS_a081_stateRequest m81 : 16|4@1+ (1,0) [0|15] "" Vector__XXX
 SG_ BMS_a081_firstBlockingAlertId m81 : 20|9@1+ (1,0) [0|511] "" Vector__XXX
 SG_ BMS_a081_secondBlockingAlertId m81 : 29|9@1+ (1,0) [0|511] "" Vector__XXX
 SG_ BMS_a081_thirdBlockingAlertId m81 : 38|9@1+ (1,0) [0|511] "" Vector__XXX
 SG_ BMS_a081_fourthBlockingAlertId m81 : 47|9@1+ (1,0) [0|511] "" Vector__XXX
 SG_ BMS_a081_totalAlertCount m81 : 56|8@1+ (1,0) [0|255] "" Vector__XXX
 SG_ BMS_a082_stateRequest m82 : 16|4@1+ (1,0) [0|15] "" Vector__XXX
 SG_ BMS_a082_firstAlertId m82 : 20|9@1+ (1,0) [0|511] "" Vector__XXX
 SG_ BMS_a082_secondAlertId m82 : 29|9@1+ (1,0) [0|511] "" Vector__XXX
 SG_ BMS_a082_thirdAlertId m82 : 38|9@1+ (1,0) [0|511] "" Vector__XXX
 SG_ BMS_a082_fourthAlertId m82 : 47|9@1+ (1,0) [0|511] "" Vector__XXX
 SG_ BMS_a082_totalAlertCount m82 : 56|8@1+ (1,0) [0|255] "" Vector__XXX
 SG_ BMS_a083_packContactorRequest m83 : 16|3@1+ (1,0) [1|7] "" Vector__XXX
 SG_ BMS_a085_packContactorSetStatePr m85 : 16|4@1+ (1,0) [1|15] "" Vector__XXX
 SG_ BMS_a085_packContactorSetState m85 : 20|4@1+ (1,0) [1|15] "" Vector__XXX
 SG_ BMS_a085_packContactorSetRe_0001 m85 : 24|3@1+ (1,0) [1|7] "" Vector__XXX
 SG_ BMS_a085_packContactorSetRequest m85 : 27|3@1+ (1,0) [1|7] "" Vector__XXX
 SG_ BMS_a086_fcContactorSetStatePrev m86 : 16|4@1+ (1,0) [1|15] "" Vector__XXX
 SG_ BMS_a086_fcContactorSetState m86 : 20|4@1+ (1,0) [1|15] "" Vector__XXX
 SG_ BMS_a086_fcContactorSetRequestPr m86 : 24|3@1+ (1,0) [1|7] "" Vector__XXX
 SG_ BMS_a086_fcContactorSetRequest m86 : 27|3@1+ (1,0) [1|7] "" Vector__XXX
 SG_ BMS_a087_blockingAlert m87 : 16|9@1+ (1,0) [0|511] "" Vector__XXX
 SG_ BMS_a090_GTWmessageTout m90 : 16|4@1+ (1,0) [0|15] "" Vector__XXX
 SG_ BMS_a098_breakLocationA m98 : 16|5@1+ (1,0) [0|31] "" Vector__XXX
 SG_ BMS_a098_bmbCommStatusTypeA m98 : 21|2@1+ (1,0) [0|3] "" Vector__XXX
 SG_ BMS_a098_breakLocationB m98 : 24|5@1+ (1,0) [0|31] "" Vector__XXX
 SG_ BMS_a098_bmbCommStatusTypeB m98 : 29|2@1+ (1,0) [0|3] "" Vector__XXX
 SG_ BMS_a098_alertFromHvp m98 : 31|1@1+ (1,0) [0|1] "" Vector__XXX
 SG_ BMS_a099_breakLocationA m99 : 16|5@1+ (1,0) [0|31] "" Vector__XXX
 SG_ BMS_a099_bmbCommStatusTypeA m99 : 21|2@1+ (1,0) [0|3] "" Vector__XXX
 SG_ BMS_a099_breakLocationB m99 : 24|5@1+ (1,0) [0|31] "" Vector__XXX
 SG_ BMS_a099_bmbCommStatusTypeB m99 : 29|2@1+ (1,0) [0|3] "" Vector__XXX
 SG_ BMS_a099_bmbChainBreakType m99 : 32|3@1+ (1,0) [0|7] "" Vector__XXX
 SG_ BMS_a099_alertFromHvp m99 : 35|1@1+ (1,0) [0|1] "" Vector__XXX
 SG_ BMS_a100_testTrigger m100 : 16|1@1+ (1,0) [0|1] "" Vector__XXX
 SG_ BMS_a100_setFromNvm m100 : 17|1@1+ (1,0) [0|1] "" Vector__XXX
 SG_ BMS_a100_voltageDeviation m100 : 18|1@1+ (1,0) [0|1] "" Vector__XXX
 SG_ BMS_a100_voltageLoss m100 : 19|1@1+ (1,0) [0|1] "" Vector__XXX
 SG_ BMS_a105_tSenseFailedModule1 m105 : 16|1@1+ (1,0) [0|1] "" Vector__XXX
 SG_ BMS_a105_avgBrickTModule1 m105 : 17|8@1+ (0.5,0) [0|127.5] "C" Vector__XXX
 SG_ BMS_a105_tSenseFailedModule2 m105 : 25|1@1+ (1,0) [0|1] "" Vector__XXX
 SG_ BMS_a105_avgBrickTModule2 m105 : 26|8@1+ (0.5,0) [0|127.5] "C" Vector__XXX
 SG_ BMS_a105_tSenseFailedModule3 m105 : 34|1@1+ (1,0) [0|1] "" Vector__XXX
 SG_ BMS_a105_avgBrickTModule3 m105 : 35|8@1+ (0.5,0) [0|127.5] "C" Vector__XXX
 SG_ BMS_a105_tSenseFailedModule4 m105 : 43|1@1+ (1,0) [0|1] "" Vector__XXX
 SG_ BMS_a105_avgBrickTModule4 m105 : 44|8@1+ (0.5,0) [0|127.5] "C" Vector__XXX
 SG_ BMS_a105_inletTemp m105 : 52|8@1+ (0.5,0) [0|127.5] "C" Vector__XXX
 SG_ BMS_a106_minBrickT m106 : 16|8@1+ (0.5,0) [0|127.5] "C" Vector__XXX
 SG_ BMS_a106_maxBrickT m106 : 24|8@1+ (0.5,0) [0|127.5] "C" Vector__XXX
 SG_ BMS_a106_avgBrickT m106 : 32|8@1+ (0.5,0) [0|127.5] "C" Vector__XXX
 SG_ BMS_a106_inletTemp m106 : 40|8@1+ (0.5,0) [0|127.5] "C" Vector__XXX
 SG_ BMS_a107_MIA_numBadReadings m107 : 16|8@1+ (1,0) [0|255] "" Vector__XXX
 SG_ BMS_a107_MIA_numSnaReadings m107 : 24|8@1+ (1,0) [0|255] "" Vector__XXX
 SG_ BMS_a107_MIA_stackId m107 : 32|8@1+ (1,1) [1|256] "" Vector__XXX
 SG_ BMS_a109_muteMask m109 : 16|16@1+ (1,0) [0|65535] "" Vector__XXX
 SG_ BMS_a109_packInBleed m109 : 32|1@1+ (1,0) [0|1] "" Vector__XXX
 SG_ BMS_a117_brickID m117 : 16|7@1+ (1,1) [1|128] "" Vector__XXX
 SG_ BMS_a117_brickSoc2 m117 : 23|10@1+ (0.1,0) [0|102.2] "%" Vector__XXX
 SG_ BMS_a117_dSocAlertThreshold m117 : 33|5@1+ (0.125,-4) [-4|-0.125] "%" Vector__XXX
 SG_ BMS_a117_dSocAlpha m117 : 48|12@1+ (0.0030517578125,-12.4969482422) [-12.4969482422|-0.003051757825] "%" Vector__XXX
 SG_ BMS_a118_brickID m118 : 16|7@1+ (1,1) [1|128] "" Vector__XXX
 SG_ BMS_a118_brickSoc2 m118 : 23|10@1+ (0.1,0) [0|102.2] "%" Vector__XXX
 SG_ BMS_a118_dSocAlertThreshold m118 : 33|5@1+ (0.125,-4) [-4|-0.125] "%" Vector__XXX
 SG_ BMS_a118_dSocAlpha m118 : 48|12@1+ (0.0030517578125,-12.4969482422) [-12.4969482422|-0.003051757825] "%" Vector__XXX
 SG_ BMS_a122_thermistorID m122 : 16|5@1+ (1,1) [1|32] "" Vector__XXX
 SG_ BMS_a122_irrationalThermistorTem m122 : 24|8@1+ (0.5,-40) [-40|87.5] "DegC" Vector__XXX
 SG_ BMS_a122_averageRawThermistorTem m122 : 32|8@1+ (0.5,-40) [-40|87.5] "DegC" Vector__XXX
 SG_ BMS_a122_minRawThermistorTemp m122 : 40|8@1+ (0.5,-40) [-40|87.5] "DegC" Vector__XXX
 SG_ BMS_a122_maxRawThermistorTemp m122 : 48|8@1+ (0.5,-40) [-40|87.5] "DegC" Vector__XXX
 SG_ BMS_a122_numValidThermistors m122 : 56|5@1+ (1,0) [0|31] "" Vector__XXX
 SG_ BMS_a123_packPlus m123 : 32|8@1+ (4,0) [0|1020] "V" Vector__XXX
 SG_ BMS_a123_isoR m123 : 40|10@1+ (10,0) [0|10230] "kOhm" Vector__XXX
 SG_ BMS_a123_packMinus m123 : 56|8@1- (4,0) [-512|508] "V" Vector__XXX
 SG_ BMS_a129_brickID m129 : 16|8@1+ (1,1) [1|256] "-" Vector__XXX
 SG_ BMS_a129_deltaV m129 : 24|16@1- (0.0002,0) [-6.5536|6.5534] "V" Vector__XXX
 SG_ BMS_a129_retryCount m129 : 40|4@1+ (1,0) [0|15] "-" Vector__XXX
 SG_ BMS_a131_brickID m131 : 16|8@1+ (1,1) [1|256] "-" Vector__XXX
 SG_ BMS_a131_deltaV m131 : 24|16@1- (0.0002,0) [-6.5536|6.5534] "V" Vector__XXX
 SG_ BMS_a131_retryCount m131 : 40|4@1+ (1,0) [0|15] "-" Vector__XXX
 SG_ BMS_a132_multiVendorErrorMask m132 : 16|16@1+ (1,0) [0|65535] "" Vector__XXX
 SG_ BMS_a135_bmbDiagnosticsType m135 : 16|2@1+ (1,0) [0|3] "" Vector__XXX
 SG_ BMS_a135_bmbDeviceId m135 : 18|4@1+ (1,1) [1|16] "" Vector__XXX
 SG_ BMS_a135_readCVA m135 : 22|1@1+ (1,0) [0|1] "" Vector__XXX
 SG_ BMS_a135_readCVB m135 : 23|1@1+ (1,0) [0|1] "" Vector__XXX
 SG_ BMS_a135_readCVC m135 : 24|1@1+ (1,0) [0|1] "" Vector__XXX
 SG_ BMS_a135_readCVD m135 : 25|1@1+ (1,0) [0|1] "" Vector__XXX
 SG_ BMS_a135_readCVE m135 : 26|1@1+ (1,0) [0|1] "" Vector__XXX
 SG_ BMS_a135_readCVF m135 : 27|1@1+ (1,0) [0|1] "" Vector__XXX
 SG_ BMS_a135_readSNA m135 : 28|1@1+ (1,0) [0|1] "" Vector__XXX
 SG_ BMS_a135_readSNB m135 : 29|1@1+ (1,0) [0|1] "" Vector__XXX
 SG_ BMS_a135_readSNC m135 : 30|1@1+ (1,0) [0|1] "" Vector__XXX
 SG_ BMS_a135_readSND m135 : 31|1@1+ (1,0) [0|1] "" Vector__XXX
 SG_ BMS_a135_readSNE m135 : 32|1@1+ (1,0) [0|1] "" Vector__XXX
 SG_ BMS_a135_readSNF m135 : 33|1@1+ (1,0) [0|1] "" Vector__XXX
 SG_ BMS_a135_readAUXA m135 : 34|1@1+ (1,0) [0|1] "" Vector__XXX
 SG_ BMS_a135_readAUXB m135 : 35|1@1+ (1,0) [0|1] "" Vector__XXX
 SG_ BMS_a135_readSTAT m135 : 36|1@1+ (1,0) [0|1] "" Vector__XXX
 SG_ BMS_a136_maxBrickTID m136 : 16|5@1+ (1,1) [1|32] "" Vector__XXX
 SG_ BMS_a136_coolantInletT m136 : 24|8@1+ (0.4,-20) [-20|82] "C" Vector__XXX
 SG_ BMS_a136_activeCoolingTarget m136 : 32|8@1+ (0.4,-20) [-20|82] "C" Vector__XXX
 SG_ BMS_a136_maxBrickT m136 : 40|8@1+ (0.4,-20) [-20|82] "C" Vector__XXX
 SG_ BMS_a139_packVoltage m139 : 16|16@1- (0.01,0) [-327.68|327.67] "V" Vector__XXX
 SG_ BMS_a139_dcLinkVoltage m139 : 32|16@1+ (0.01,0) [0|655.35] "V" Vector__XXX
 SG_ BMS_a140_bmbDeviceMask m140 : 16|16@1+ (1,0) [0|65535] "" Vector__XXX
 SG_ BMS_a140_faultType m140 : 32|8@1+ (1,0) [0|255] "" Vector__XXX
 SG_ BMS_a142_isolationResistance m142 : 16|10@1+ (10,0) [0|10230] "kOhm" Vector__XXX
 SG_ BMS_a142_mode m142 : 32|3@1+ (1,0) [0|7] "" Vector__XXX
 SG_ BMS_a143_initialSoc m143 : 16|9@1+ (0.2,0) [0|102.2] "%" Vector__XXX
 SG_ BMS_a143_endingSoc m143 : 25|9@1+ (0.2,0) [0|102.2] "%" Vector__XXX
 SG_ BMS_a143_deltaAh m143 : 34|9@1+ (0.5,0) [0|255.5] "Ah" Vector__XXX
 SG_ BMS_a143_cacChangeBrickID m143 : 48|7@1+ (1,1) [1|128] "" Vector__XXX
 SG_ BMS_a143_cacUpdateError m143 : 56|8@1+ (0.1,0) [0|25.5] "Ah" Vector__XXX
 SG_ BMS_a144_HVP_major_version m144 : 16|16@1+ (1,0) [0|65535] "" Vector__XXX
 SG_ BMS_a144_HVP_minor_version m144 : 32|16@1+ (1,0) [0|65535] "" Vector__XXX
 SG_ BMS_a144_BMS_minor_version m144 : 48|16@1+ (1,0) [0|65535] "" Vector__XXX
 SG_ BMS_a145_maxSocChange m145 : 16|11@1- (0.1,0) [-102.4|102.3] "%" Vector__XXX
 SG_ BMS_a145_maxSocChangeBrickID m145 : 32|7@1+ (1,1) [1|128] "" Vector__XXX
 SG_ BMS_a145_numBricksChanged m145 : 40|7@1+ (1,0) [0|127] "" Vector__XXX
 SG_ BMS_a145_brickChangeHystRatio m145 : 48|10@1+ (0.001,0) [0|1.022] "Ratio" Vector__XXX
 SG_ BMS_a146_maxBrickV m146 : 16|8@1+ (0.01,2) [2|4.55] "V" Vector__XXX
 SG_ BMS_a146_state m146 : 24|4@1+ (1,0) [0|15] "" Vector__XXX
 SG_ BMS_a146_packCurrent m146 : 32|8@1+ (8,-1496) [-1496|544] "A" Vector__XXX
 SG_ BMS_a146_uvBrickVID m146 : 40|7@1+ (1,1) [1|128] "" Vector__XXX
 SG_ BMS_a146_uvBrickV m146 : 48|16@1+ (7.62939453125e-05,0) [0|4.99992370605] "V" Vector__XXX
 SG_ BMS_a151_isoPositiveR m151 : 32|10@1+ (10,0) [0|10230] "kOhm" Vector__XXX
 SG_ BMS_a151_isoNegativeR m151 : 42|10@1+ (10,0) [0|10230] "kOhm" Vector__XXX
 SG_ BMS_a152_isoR m152 : 16|9@1+ (10,0) [0|5110] "kOhm" Vector__XXX
 SG_ BMS_a152_mode m152 : 25|3@1+ (1,0) [0|7] "" Vector__XXX
 SG_ BMS_a152_activeSideVNoR m152 : 28|9@1+ (1,0) [0|511] "V" Vector__XXX
 SG_ BMS_a152_activeSideVWithR m152 : 37|9@1+ (1,0) [0|511] "V" Vector__XXX
 SG_ BMS_a152_passiveSideVNoR m152 : 46|9@1+ (1,0) [0|511] "V" Vector__XXX
 SG_ BMS_a152_passiveSideVWithR m152 : 55|9@1+ (1,0) [0|511] "V" Vector__XXX
 SG_ BMS_a154_packCurrent m154 : 16|8@1+ (4,0) [0|1020] "A" Vector__XXX
 SG_ BMS_a154_ovBrickVID m154 : 24|7@1+ (1,1) [1|128] "" Vector__XXX
 SG_ BMS_a154_ovBrickV m154 : 32|16@1+ (7.62939453125e-05,0) [0|4.99992370605] "V" Vector__XXX
 SG_ BMS_a156_VrefSample m156 : 16|16@1+ (0.0001,0) [0|6.5535] "V" Vector__XXX
 SG_ BMS_a156_bmbDeviceId m156 : 32|4@1+ (1,1) [1|16] "" Vector__XXX
 SG_ BMS_a156_VrefStatus m156 : 36|2@1+ (1,0) [0|3] "" Vector__XXX
 SG_ BMS_a158_shuntCurrentMia m158 : 16|1@1+ (1,0) [0|1] "" Vector__XXX
 SG_ BMS_a158_contactorStateMia m158 : 17|1@1+ (1,0) [0|1] "" Vector__XXX
 SG_ BMS_a158_hvpFaultsMia m158 : 18|1@1+ (1,0) [0|1] "" Vector__XXX
 SG_ BMS_a162_dischargePower_W m162 : 16|16@1- (1,0) [-32768|32767] "W" Vector__XXX
 SG_ BMS_a162_minSoc m162 : 32|16@1+ (1,0) [0|65535] "%" Vector__XXX
 SG_ BMS_a162_socThreshold m162 : 48|16@1+ (1,0) [0|65535] "%" Vector__XXX
 SG_ BMS_a164_regenPower m164 : 16|32@1+ (1,0) [0|4294967295] "W" Vector__XXX
 SG_ BMS_a165_packPositiveV m165 : 16|12@1- (0.25,0) [-512|511.75] "V" Vector__XXX
 SG_ BMS_a165_packNegativeV m165 : 28|12@1- (0.25,0) [-512|511.75] "V" Vector__XXX
 SG_ BMS_a165_dcLinkPositiveV m165 : 40|12@1- (0.25,0) [-512|511.75] "V" Vector__XXX
 SG_ BMS_a165_dcLinkNegativeV m165 : 52|12@1- (0.25,0) [-512|511.75] "V" Vector__XXX
 SG_ BMS_a166_packPositiveV m166 : 16|12@1- (0.25,0) [-512|511.75] "V" Vector__XXX
 SG_ BMS_a166_packNegativeV m166 : 28|12@1- (0.25,0) [-512|511.75] "V" Vector__XXX
 SG_ BMS_a166_dcLinkPositiveV m166 : 40|12@1- (0.25,0) [-512|511.75] "V" Vector__XXX
 SG_ BMS_a166_dcLinkNegativeV m166 : 52|12@1- (0.25,0) [-512|511.75] "V" Vector__XXX
 SG_ BMS_a167_fcContPositiveAuxOpen m167 : 16|1@1+ (1,0) [0|1] "" Vector__XXX
 SG_ BMS_a167_fcContNegativeAuxOpen m167 : 17|1@1+ (1,0) [0|1] "" Vector__XXX
 SG_ BMS_a167_dcLinkPositiveV m167 : 18|11@1- (0.5,0) [-512|511.5] "V" Vector__XXX
 SG_ BMS_a167_dcLinkNegativeV m167 : 29|11@1- (0.5,0) [-512|511.5] "V" Vector__XXX
 SG_ BMS_a167_fcLinkPositiveV m167 : 40|11@1- (0.5,0) [-512|511.5] "V" Vector__XXX
 SG_ BMS_a167_fcLinkNegativeV m167 : 51|11@1- (0.5,0) [-512|511.5] "V" Vector__XXX
 SG_ BMS_a168_fcContPositiveAuxOpen m168 : 16|1@1+ (1,0) [0|1] "" Vector__XXX
 SG_ BMS_a168_fcContNegativeAuxOpen m168 : 17|1@1+ (1,0) [0|1] "" Vector__XXX
 SG_ BMS_a168_dcLinkPositiveV m168 : 18|11@1- (0.5,0) [-512|511.5] "V" Vector__XXX
 SG_ BMS_a168_dcLinkNegativeV m168 : 29|11@1- (0.5,0) [-512|511.5] "V" Vector__XXX
 SG_ BMS_a168_fcLinkPositiveV m168 : 40|11@1- (0.5,0) [-512|511.5] "V" Vector__XXX
 SG_ BMS_a168_fcLinkNegativeV m168 : 51|11@1- (0.5,0) [-512|511.5] "V" Vector__XXX
 SG_ BMS_a169_DCAndFCContactorsWelded m169 : 16|1@1+ (1,0) [0|1] "" Vector__XXX
 SG_ BMS_a170_limpModeActive m170 : 16|1@1+ (1,0) [0|1] "" Vector__XXX
 SG_ BMS_a171_stackVoltage m171 : 16|16@1+ (0.00128,0) [0|83.8848] "V" Vector__XXX
 SG_ BMS_a171_sumBrickVoltage m171 : 32|16@1+ (0.00128,0) [0|83.8848] "V" Vector__XXX
 SG_ BMS_a171_stackId m171 : 48|8@1+ (1,1) [1|256] "" Vector__XXX
 SG_ BMS_a172_swIsolationCount m172 : 16|8@1+ (1,0) [0|255] "" Vector__XXX
 SG_ BMS_a177_energyAlertThreshold m177 : 16|10@1+ (0.1,0) [0|102.3] "KWh" Vector__XXX
 SG_ BMS_a177_energyBuffer m177 : 26|10@1+ (0.1,0) [0|102.3] "KWh" Vector__XXX
 SG_ BMS_a178_diPower m178 : 16|9@1- (4.3137254715,250.196075439) [-854.117645265|1350.19607067] "kW" Vector__XXX
 SG_ BMS_a178_energyError m178 : 25|8@1- (2,0) [-256|254] "kJ" Vector__XXX
 SG_ BMS_a178_powerError m178 : 33|9@1- (1,0) [-256|255] "kW" Vector__XXX
 SG_ BMS_a178_minPowerError m178 : 42|9@1- (1,0) [-256|255] "kW" Vector__XXX
 SG_ BMS_a178_maxPowerError m178 : 51|9@1- (1,0) [-256|255] "kW" Vector__XXX
 SG_ BMS_a178_diMiaCount m178 : 60|2@1+ (1,0) [0|3] "" Vector__XXX
 SG_ BMS_a178_diSnaCount m178 : 62|2@1+ (1,0) [0|3] "" Vector__XXX
 SG_ BMS_a188_currentTripThreshold m188 : 16|16@1+ (0.0025,0) [0|163.8375] "A" Vector__XXX
 SG_ BMS_a188_dcLinkDetectedCurrent m188 : 32|16@1+ (0.0025,0) [0|163.8375] "A" Vector__XXX
 SG_ BMS_a189_currentTripThreshold m189 : 16|16@1- (0.0025,-75) [-156.92|6.9175] "A" Vector__XXX
 SG_ BMS_a189_dcLinkDetectedCurrent m189 : 32|16@1- (0.0025,-75) [-156.92|6.9175] "A" Vector__XXX
 SG_ BMS_a190_voltageTripThreshold m190 : 16|16@1+ (0.025,0) [0|1638.375] "V" Vector__XXX
 SG_ BMS_a190_dcLinkDetectedVoltage m190 : 32|16@1+ (0.025,0) [0|1638.375] "V" Vector__XXX
 SG_ BMS_a191_voltageTripThreshold m191 : 16|16@1+ (0.025,0) [0|1638.375] "V" Vector__XXX
 SG_ BMS_a191_dcLinkDetectedVoltage m191 : 32|16@1+ (0.025,0) [0|1638.375] "V" Vector__XXX
 SG_ BMS_a192_detectedChargeCurrent m192 : 16|16@1+ (0.0025,0) [0|163.8375] "A" Vector__XXX
 SG_ BMS_a193_maxBrickVoltageLimit m193 : 16|12@1+ (0.001,1) [1|5.095] "V" Vector__XXX
 SG_ BMS_a193_detectedMaxBrickVoltage m193 : 28|12@1+ (0.001,1) [1|5.095] "V" Vector__XXX
 SG_ BMS_a201_maxBrickV m201 : 16|16@1+ (7.62939453125e-05,0) [0|4.99992370605] "V" Vector__XXX
 SG_ BMS_a201_maxBrickVIndex m201 : 32|7@1+ (1,1) [1|128] "" Vector__XXX
 SG_ BMS_a227_packCurrent m227 : 16|16@1- (0.1,0) [-3276.8|3276.7] "A" Vector__XXX
 SG_ BMS_a227_dcChargeCurrentRequest m227 : 32|16@1- (0.1,0) [-3276.8|3276.7] "A" Vector__XXX
 SG_ BMS_a256_minBrickT m256 : 16|8@1- (0.5,24) [-40|87.5] "C" Vector__XXX
 SG_ BMS_a256_maxBrickT m256 : 24|8@1- (0.5,24) [-40|87.5] "C" Vector__XXX
 SG_ BMS_a256_minBrickV m256 : 32|8@1+ (0.01,2) [2|4.55] "V" Vector__XXX
 SG_ BMS_a256_maxBrickV m256 : 40|8@1+ (0.01,2) [2|4.55] "V" Vector__XXX
 SG_ BMS_a256_packSoe m256 : 48|8@1+ (0.393700778484,0) [0|100.393698513] "%" Vector__XXX
 SG_ BMS_a256_SOC m256 : 56|8@1+ (0.05,0) [0|12.75] "%" Vector__XXX

BO_TX_BU_ 1113 : APS;
BO_TX_BU_ 848 : APS;
BO_TX_BU_ 784 : APS;
BO_TX_BU_ 943 : BB;
BO_TX_BU_ 1343 : BMS;
CM_ BO_ 1113 "Driver assistance computer (secondary) message: warning matrix2";
CM_ SG_ 1113 APS_w129_ECU_Power_Issue "Driver assistance computer (secondary): w129 ECU power issue";
CM_ SG_ 1113 APS_w130_ECU_Thermal_Issue "Driver assistance computer (secondary): w130 ECU thermal issue";
CM_ SG_ 1113 APS_w131_trap_exception "Driver assistance computer (secondary): w131 trap exception";
CM_ SG_ 1113 APS_w132_appVersionMismatch "Driver assistance computer (secondary): w132 app version mismatch";
CM_ SG_ 1113 APS_w133_ETHSwitchError "Driver assistance computer (secondary): w133 ETH switch error";
CM_ SG_ 1113 APS_w134_appMia "Driver assistance computer (secondary): w134 app mia";
CM_ SG_ 1113 APS_w135_appCritical "Driver assistance computer (secondary): w135 app critical";
CM_ SG_ 1113 APS_w136_gpsDisabled "Driver assistance computer (secondary): w136 gps disabled";
CM_ SG_ 1113 APS_w137_gpsFaultReset "Driver assistance computer (secondary): w137 gps fault reset";
CM_ SG_ 1113 APS_w138_gpsComIssue "Driver assistance computer (secondary): w138 gps com issue";
CM_ SG_ 1113 APS_w139_udpBufferOverflow "Driver assistance computer (secondary): w139 udp buffer overflow";
CM_ SG_ 1113 APS_w140_vcfrontMiaVehicleBus "Driver assistance computer (secondary): w140 vcfront mia vehicle bus";
CM_ SG_ 1113 APS_w141_rcmMiaPartyBus "Driver assistance computer (secondary): w141 rcm mia party bus";
CM_ SG_ 1113 APS_w142_diMiaPartyBus "Driver assistance computer (secondary): w142 di mia party bus";
CM_ SG_ 1113 APS_w143_espMiaPartyBus "Driver assistance computer (secondary): w143 esp mia party bus";
CM_ SG_ 1113 APS_w144_vcleftMiaPartyBus "Driver assistance computer (secondary): w144 vcleft mia party bus";
CM_ SG_ 1113 APS_w145_vcrightMiaPartyBus "Driver assistance computer (secondary): w145 vcright mia party bus";
CM_ SG_ 1113 APS_w146_epas3pMiaPartyBus "Driver assistance computer (secondary): w146 epas3p mia party bus";
CM_ SG_ 1113 APS_w147_vcleftMiaVehBus "Driver assistance computer (secondary): w147 vcleft mia veh bus";
CM_ SG_ 1113 APS_w148_vcrightMiaVehBus "Driver assistance computer (secondary): w148 vcright mia veh bus";
CM_ SG_ 1113 APS_w149_epblMiaVehBus "Driver assistance computer (secondary): w149 epbl mia veh bus";
CM_ SG_ 1113 APS_w150_sccmMiaVehBus "Driver assistance computer (secondary): w150 sccm mia veh bus";
CM_ SG_ 1113 APS_w151_apRecovered "Driver assistance computer (secondary): w151 ap recovered";
CM_ SG_ 1113 APS_w152_gpsFusionStatus "Driver assistance computer (secondary): w152 gps fusion status";
CM_ SG_ 1113 APS_w153_eacInhibit "Driver assistance computer (secondary): w153 eac inhibit";
CM_ SG_ 1113 APS_w155_ethLwipError "Driver assistance computer (secondary): w155 eth lwip error";
CM_ SG_ 1113 APS_w156_lwipAssert "Driver assistance computer (secondary): w156 lwip assert";
CM_ SG_ 1113 APS_w157_autopilotReboot "Driver assistance computer (secondary): w157 autopilot reboot";
CM_ SG_ 1113 APS_w158_apbMia "Driver assistance computer (secondary): w158 apb mia";
CM_ SG_ 1113 APS_w159_apbCritical "Driver assistance computer (secondary): w159 apb critical";
CM_ SG_ 1113 APS_w160_apbVersionMismatch "Driver assistance computer (secondary): w160 apb version mismatch";
CM_ SG_ 1113 APS_w161_gpsAntennaDisconnected "Driver assistance computer (secondary): w161 gps antenna disconnected";
CM_ SG_ 1113 APS_w162_TurboA_DisRegPgoodErr "Driver assistance computer (secondary): w162 turbo a dis reg pgood err";
CM_ SG_ 1113 APS_w163_TurboA_DisRegNFault "Driver assistance computer (secondary): w163 turbo a dis reg n fault";
CM_ SG_ 1113 APS_w164_TurboA_12VFuseFault "Driver assistance computer (secondary): w164 turbo a 12 v fuse fault";
CM_ SG_ 1113 APS_w165_TurboA_Temp_NOS "Driver assistance computer (secondary): w165 turbo a temp NOS";
CM_ SG_ 1113 APS_w166_TurboA_SMSLockStepErr "Driver assistance computer (secondary): w166 turbo a SMS lock step err";
CM_ SG_ 1113 APS_w167_TurboA_TMU_Throttle "Driver assistance computer (secondary): w167 turbo a TMU throttle";
CM_ SG_ 1113 APS_w168_TurboA_SMS_WDOG "Driver assistance computer (secondary): w168 turbo a SMS WDOG";
CM_ SG_ 1113 APS_w169_TurboA_SCS_LKUP "Driver assistance computer (secondary): w169 turbo a SCS LKUP";
CM_ SG_ 1113 APS_w170_TurboA_A72_watchdog "Driver assistance computer (secondary): w170 turbo a A72 watchdog";
CM_ SG_ 1113 APS_w171_TurboA_SMS_taskUtilErr "Driver assistance computer (secondary): w171 turbo a SMS task util err";
CM_ SG_ 1113 APS_w172_apFeaturesUnavailable "Driver assistance computer (secondary): w172 ap features unavailable";
CM_ SG_ 1113 APS_w178_TurboB_DisRegPgoodErr "Driver assistance computer (secondary): w178 turbo b dis reg pgood err";
CM_ SG_ 1113 APS_w179_TurboB_DisRegNFault "Driver assistance computer (secondary): w179 turbo b dis reg n fault";
CM_ SG_ 1113 APS_w180_TurboB_12VFuseFault "Driver assistance computer (secondary): w180 turbo b 12 v fuse fault";
CM_ SG_ 1113 APS_w181_TurboB_Temp_NOS "Driver assistance computer (secondary): w181 turbo b temp NOS";
CM_ SG_ 1113 APS_w182_TurboB_SMSLockStepErr "Driver assistance computer (secondary): w182 turbo b SMS lock step err";
CM_ SG_ 1113 APS_w183_TurboB_TMU_Throttle "Driver assistance computer (secondary): w183 turbo b TMU throttle";
CM_ SG_ 1113 APS_w184_TurboB_SMS_WDOG "Driver assistance computer (secondary): w184 turbo b SMS WDOG";
CM_ SG_ 1113 APS_w185_TurboB_SCS_LKUP "Driver assistance computer (secondary): w185 turbo b SCS LKUP";
CM_ SG_ 1113 APS_w186_TurboB_A72_watchdog "Driver assistance computer (secondary): w186 turbo b A72 watchdog";
CM_ SG_ 1113 APS_w187_TurboB_SMS_taskUtilErr "Driver assistance computer (secondary): w187 turbo b SMS task util err";
CM_ SG_ 1113 APS_w188_otherTurboUartMIA "Driver assistance computer (secondary): w188 other turbo uart MIA";
CM_ SG_ 1113 APS_w189_vcfrontMiaPartyBus "Driver assistance computer (secondary): w189 vcfront mia party bus";
CM_ SG_ 1113 APS_w190_iboosterMia "Driver assistance computer (secondary): w190 ibooster mia";
CM_ SG_ 1113 APS_w191_timesyncError "Driver assistance computer (secondary): w191 timesync error";
CM_ SG_ 1113 APS_w192_CANFault "Driver assistance computer (secondary): w192 CAN fault";
CM_ BO_ 848 "Driver assistance computer (secondary) message: warning matrix3";
CM_ SG_ 848 APS_w193_camWindshieldUnclean "Driver assistance computer (secondary): w193 cam windshield unclean";
CM_ SG_ 848 APS_w194_accDriverResumeRqrd "Driver assistance computer (secondary): w194 acc driver resume rqrd";
CM_ SG_ 848 APS_w195_scwUnavailable "Driver assistance computer (secondary): w195 scw unavailable";
CM_ SG_ 848 APS_w196_stopSignWarning "Driver assistance computer (secondary): w196 stop sign warning";
CM_ SG_ 848 APS_w197_redLightWarning "Driver assistance computer (secondary): w197 red light warning";
CM_ SG_ 848 APS_w198_tsrUnavailable "Driver assistance computer (secondary): w198 tsr unavailable";
CM_ SG_ 848 APS_w199_apcAbort "Driver assistance computer (secondary): w199 apc abort";
CM_ SG_ 848 APS_w200_lcSlowdown "Driver assistance computer (secondary): w200 lc slowdown";
CM_ SG_ 848 APS_w201_lcAborting "Driver assistance computer (secondary): w201 lc aborting";
CM_ SG_ 848 APS_w202_scwNoisyEnvironment "Driver assistance computer (secondary): w202 scw noisy environment";
CM_ SG_ 848 APS_w203_apcActivation "Driver assistance computer (secondary): w203 apc activation";
CM_ SG_ 848 APS_w204_apcFinalFront "Driver assistance computer (secondary): w204 apc final front";
CM_ SG_ 848 APS_w205_apcFinalRear "Driver assistance computer (secondary): w205 apc final rear";
CM_ SG_ 848 APS_w206_autosteerNotEnabled "Driver assistance computer (secondary): w206 autosteer not enabled";
CM_ SG_ 848 APS_w207_autosteerUnavailable "Driver assistance computer (secondary): w207 autosteer unavailable";
CM_ SG_ 848 APS_w208_rackDetected "Driver assistance computer (secondary): w208 rack detected";
CM_ SG_ 848 APS_w209_autoSummonRequest "Driver assistance computer (secondary): w209 auto summon request";
CM_ SG_ 848 APS_w210_camObstrcted "Driver assistance computer (secondary): w210 cam obstrcted";
CM_ SG_ 848 APS_w211_accNoSeatBelt "Driver assistance computer (secondary): w211 acc no seat belt";
CM_ SG_ 848 APS_w212_lcUnavailableStrikeOut "Driver assistance computer (secondary): w212 lc unavailable strike out";
CM_ SG_ 848 APS_w213_autosteerStruckOut "Driver assistance computer (secondary): w213 autosteer struck out";
CM_ SG_ 848 APS_w214_driverNotIntracting "Driver assistance computer (secondary): w214 driver not intracting";
CM_ SG_ 848 APS_w215_contDriverNotIntracting "Driver assistance computer (secondary): w215 cont driver not intracting";
CM_ SG_ 848 APS_w216_driverOverriding "Driver assistance computer (secondary): w216 driver overriding";
CM_ SG_ 848 APS_w217_lcUnavailableSpeeding "Driver assistance computer (secondary): w217 lc unavailable speeding";
CM_ SG_ 848 APS_w218_lcSpeedExceededLimit "Driver assistance computer (secondary): w218 lc speed exceeded limit";
CM_ SG_ 848 APS_w219_lcTempUnavailableSpeed "Driver assistance computer (secondary): w219 lc temp unavailable speed";
CM_ SG_ 848 APS_w220_lcTempUnavailableRoad "Driver assistance computer (secondary): w220 lc temp unavailable road";
CM_ SG_ 848 APS_w221_accRadarBlind "Driver assistance computer (secondary): w221 acc radar blind";
CM_ SG_ 848 APS_w222_accCameraBlind "Driver assistance computer (secondary): w222 acc camera blind";
CM_ SG_ 848 APS_w223_accObjectInPath "Driver assistance computer (secondary): w223 acc object in path";
CM_ SG_ 848 APS_w224_accCameraCalibration "Driver assistance computer (secondary): w224 acc camera calibration";
CM_ SG_ 848 APS_w225_lcDegradedVisSpeedLmt "Driver assistance computer (secondary): w225 lc degraded vis speed lmt";
CM_ SG_ 848 APS_w226_lcCamCalNeededSpeedLmt "Driver assistance computer (secondary): w226 lc cam cal needed speed lmt";
CM_ SG_ 848 APS_w227_virtualWallBlocked "Driver assistance computer (secondary): w227 virtual wall blocked";
CM_ SG_ 848 APS_w228_DEPRECATED "Driver assistance computer (secondary): w228 DEPRECATED";
CM_ SG_ 848 APS_w229_alcUltrasoundDamaged "Driver assistance computer (secondary): w229 alc ultrasound damaged";
CM_ SG_ 848 APS_w230_alcUltrasoundBlocked "Driver assistance computer (secondary): w230 alc ultrasound blocked";
CM_ SG_ 848 APS_w231_idfEvent "Driver assistance computer (secondary): w231 idf event";
CM_ SG_ 848 APS_w232_laneChangeRequested "Driver assistance computer (secondary): w232 lane change requested";
CM_ SG_ 848 APS_w235_a72LoopDetected "Driver assistance computer (secondary): w235 a72 loop detected";
CM_ SG_ 848 APS_w236_canSharedMemError "Driver assistance computer (secondary): w236 can shared mem error";
CM_ SG_ 848 APS_w237_faultMgrEventDetected "Driver assistance computer (secondary): w237 fault mgr event detected";
CM_ SG_ 848 APS_w238_resetReason "Driver assistance computer (secondary): w238 reset reason";
CM_ SG_ 848 APS_w241_ddrInitFailures "Driver assistance computer (secondary): w241 ddr init failures";
CM_ SG_ 848 APS_w242_tripMBISTFailure "Driver assistance computer (secondary): w242 trip MBIST failure";
CM_ SG_ 848 APS_w243_tripHWErrorStatus "Driver assistance computer (secondary): w243 trip HW error status";
CM_ SG_ 848 APS_w244_gpuHWFaultStatus "Driver assistance computer (secondary): w244 gpu HW fault status";
CM_ SG_ 848 APS_w245_eloopRxFromUnexpectedSo "Driver assistance computer (secondary): w245 eloop rx from unexpected source MAC";
CM_ SG_ 848 APS_w246_ethloopSwitchPortLinkDo "Driver assistance computer (secondary): w246 ethloop switch port link down";
CM_ SG_ 848 APS_w247_ethernetFrameError "Driver assistance computer (secondary): w247 ethernet frame error";
CM_ SG_ 848 APS_w248_ethloopSwitchPoorSqi "Driver assistance computer (secondary): w248 ethloop switch poor sqi";
CM_ SG_ 848 APS_w249_ufsFailures "Driver assistance computer (secondary): w249 ufs failures";
CM_ SG_ 848 APS_w250_ethloopSwitchMemUsageTo "Driver assistance computer (secondary): w250 ethloop switch mem usage too high port2";
CM_ SG_ 848 APS_w251_ethloopSwitchMemUsageTo "Driver assistance computer (secondary): w251 ethloop switch mem usage too high port3";
CM_ SG_ 848 APS_w252_ethSwitchPortLinkDown "Driver assistance computer (secondary): w252 eth switch port link down";
CM_ SG_ 848 APS_w253_powerStateTimeout "Driver assistance computer (secondary): w253 power state timeout";
CM_ SG_ 848 APS_w254_sleepStateTimeout "Driver assistance computer (secondary): w254 sleep state timeout";
CM_ SG_ 848 APS_w255_bootHealth "Driver assistance computer (secondary): w255 boot health";
CM_ BO_ 784 "Driver assistance computer (secondary) message: warning matrix4";
CM_ SG_ 784 APS_w257_assertFailure "Driver assistance computer (secondary): w257 assert failure";
CM_ SG_ 784 APS_w258_qspiFlashSectorChecksum "Driver assistance computer (secondary): w258 qspi flash sector checksum mismatch";
CM_ SG_ 784 APS_w259_qspiFailure "Driver assistance computer (secondary): w259 qspi failure";
CM_ SG_ 784 APS_w260_pgoodFailure "Driver assistance computer (secondary): w260 pgood failure";
CM_ SG_ 784 APS_w261_vrmFaultGrpA "Driver assistance computer (secondary): w261 vrm fault grp a";
CM_ SG_ 784 APS_w262_vrmFaultGrpB "Driver assistance computer (secondary): w262 vrm fault grp b";
CM_ SG_ 784 APS_w263_vrmFaultGrpC "Driver assistance computer (secondary): w263 vrm fault grp c";
CM_ SG_ 784 APS_w264_ddrPhy0Failures "Driver assistance computer (secondary): w264 ddr phy0 failures";
CM_ SG_ 784 APS_w265_ddrPhy1Failures "Driver assistance computer (secondary): w265 ddr phy1 failures";
CM_ SG_ 784 APS_w266_ddrPhy2Failures "Driver assistance computer (secondary): w266 ddr phy2 failures";
CM_ SG_ 784 APS_w267_ddrPhy3Failures "Driver assistance computer (secondary): w267 ddr phy3 failures";
CM_ SG_ 784 APS_w268_ddrControllerFailures "Driver assistance computer (secondary): w268 ddr controller failures";
CM_ SG_ 784 APS_w269_ethSwitchRxPageCountToo "Driver assistance computer (secondary): w269 eth switch rx page count too high port0 3";
CM_ SG_ 784 APS_w270_ethSwitchRxPageCountToo "Driver assistance computer (secondary): w270 eth switch rx page count too high port4 7";
CM_ SG_ 784 APS_w271_ddrScheduler0EccErrors "Driver assistance computer (secondary): w271 ddr scheduler0 ecc errors";
CM_ SG_ 784 APS_w272_ddrScheduler1EccErrors "Driver assistance computer (secondary): w272 ddr scheduler1 ecc errors";
CM_ SG_ 784 APS_w273_ddrScheduler2EccErrors "Driver assistance computer (secondary): w273 ddr scheduler2 ecc errors";
CM_ SG_ 784 APS_w274_ddrScheduler3EccErrors "Driver assistance computer (secondary): w274 ddr scheduler3 ecc errors";
CM_ SG_ 784 APS_w275_ddrScheduler4EccErrors "Driver assistance computer (secondary): w275 ddr scheduler4 ecc errors";
CM_ SG_ 784 APS_w276_ddrScheduler5EccErrors "Driver assistance computer (secondary): w276 ddr scheduler5 ecc errors";
CM_ SG_ 784 APS_w277_ddrScheduler6EccErrors "Driver assistance computer (secondary): w277 ddr scheduler6 ecc errors";
CM_ SG_ 784 APS_w278_ddrScheduler7EccErrors "Driver assistance computer (secondary): w278 ddr scheduler7 ecc errors";
CM_ SG_ 784 APS_w279_ufsPartitionError "Driver assistance computer (secondary): w279 ufs partition error";
CM_ SG_ 784 APS_w280_pepsMia "Driver assistance computer (secondary): w280 peps mia";
CM_ SG_ 784 APS_w281_rsaMia "Driver assistance computer (secondary): w281 rsa mia";
CM_ SG_ 784 APS_w282_smmuError "Driver assistance computer (secondary): w282 smmu error";
CM_ SG_ 784 APS_w283_psfaMia "Driver assistance computer (secondary): w283 psfa mia";
CM_ SG_ 784 APS_w284_cam12VBuckBoostAPwrIssu "Driver assistance computer (secondary): w284 cam12 v buck boost a pwr issue";
CM_ SG_ 784 APS_w285_cam12VBuckBoostBPwrIssu "Driver assistance computer (secondary): w285 cam12 v buck boost b pwr issue";
CM_ SG_ 784 APS_w286_cam12VEFuseAPrimaryIssu "Driver assistance computer (secondary): w286 cam12 VE fuse a primary issue";
CM_ SG_ 784 APS_w287_cam12VEFuseASecondaryIs "Driver assistance computer (secondary): w287 cam12 VE fuse a secondary issue";
CM_ SG_ 784 APS_w288_brakeboosterMia "Driver assistance computer (secondary): w288 brakebooster mia";
CM_ SG_ 784 APS_w289_turboTemperatureWarning "Driver assistance computer (secondary): w289 turbo temperature warning";
CM_ SG_ 784 APS_w290_cam12VBuckBoostBPwrRing "Driver assistance computer (secondary): w290 cam12 v buck boost b pwr ringing";
CM_ SG_ 784 APS_w291_eplannerError "Driver assistance computer (secondary): w291 eplanner error";
CM_ SG_ 784 APS_w292_CH_busOff "Driver assistance computer (secondary): w292 CH bus off";
CM_ SG_ 784 APS_w293_PARTY_busOff "Driver assistance computer (secondary): w293 PARTY bus off";
CM_ SG_ 784 APS_w294_VEH_busOff "Driver assistance computer (secondary): w294 VEH bus off";
CM_ SG_ 784 APS_w295_PT_busOff "Driver assistance computer (secondary): w295 PT bus off";
CM_ SG_ 784 APS_w296_wdogMonTaskDeadlineMiss "Driver assistance computer (secondary): w296 wdog mon task deadline miss";
CM_ SG_ 784 APS_w297_earlyWDogAlert "Driver assistance computer (secondary): w297 early w dog alert";
CM_ SG_ 784 APS_w298_cpuToApCanSharedMemErro "Driver assistance computer (secondary): w298 cpu to ap can shared mem error";
CM_ SG_ 784 APS_w299_apToCpuCanSharedMemErro "Driver assistance computer (secondary): w299 ap to cpu can shared mem error";
CM_ SG_ 784 APS_w300_sharedMemoryAccessError "Driver assistance computer (secondary): w300 shared memory access error";
CM_ SG_ 784 APS_w301_nocTimeoutDetected "Driver assistance computer (secondary): w301 noc timeout detected";
CM_ SG_ 784 APS_w302_canAPShmFifoFull "Driver assistance computer (secondary): w302 can AP shm fifo full";
CM_ SG_ 784 APS_w303_canAPShmFifoEmpty "Driver assistance computer (secondary): w303 can AP shm fifo empty";
CM_ SG_ 784 APS_w304_dataAbort "Driver assistance computer (secondary): w304 data abort";
CM_ SG_ 784 APS_w305_gpsPgoodFailure "Driver assistance computer (secondary): w305 gps pgood failure";
CM_ SG_ 784 APS_w306_ethPgoodFailure "Driver assistance computer (secondary): w306 eth pgood failure";
CM_ SG_ 784 APS_w307_eccEventDetected "Driver assistance computer (secondary): w307 ecc event detected";
CM_ SG_ 784 APS_w308_pmicErrorDetected "Driver assistance computer (secondary): w308 pmic error detected";
CM_ SG_ 784 APS_w309_ethBridgeDown "Driver assistance computer (secondary): w309 eth bridge down";
CM_ SG_ 784 APS_w310_wakeBootMetrics "Driver assistance computer (secondary): w310 wake boot metrics";
CM_ SG_ 784 APS_w311_apbdgDasMia "Driver assistance computer (secondary): w311 apbdg das mia";
CM_ SG_ 784 APS_w312_apbdgApMia "Driver assistance computer (secondary): w312 apbdg ap mia";
CM_ SG_ 784 APS_w313_BDY_busOff "Driver assistance computer (secondary): w313 BDY bus off";
CM_ SG_ 784 APS_w315_epas3pMiaBdyBus "Driver assistance computer (secondary): w315 epas3p mia bdy bus";
CM_ SG_ 784 APS_w316_apBootHealth "Driver assistance computer (secondary): w316 ap boot health";
CM_ SG_ 784 APS_w317_uiMia "Driver assistance computer (secondary): w317 ui mia";
CM_ SG_ 784 APS_w318_ethernetNetworkBufferHi "Driver assistance computer (secondary): w318 ethernet network buffer high watermark";
CM_ SG_ 784 APS_w319_vehDasImposterDetected "Driver assistance computer (secondary): w319 veh das imposter detected";
CM_ SG_ 784 APS_w320_eplannerPreconditionsMe "Driver assistance computer (secondary): w320 eplanner preconditions met";
CM_ BO_ 943 "BB ECU message: status";
CM_ SG_ 943 BB_statusChecksum "BB ECU: status checksum";
CM_ SG_ 943 BB_statusCounter "BB ECU: status counter";
CM_ SG_ 943 BB_sOutputRod "Reports the measured brake booster (BB) plunger piston position";
CM_ SG_ 943 BB_sOutputRodQF "Reports the BB_sOutputRod signal qualifier";
CM_ SG_ 943 BB_sInputRod "Reports the measured brake booster (BB) input rod stroke.";
CM_ SG_ 943 BB_sInputRodQF "Reports the BB_sInputRod signal qualifier.";
CM_ SG_ 943 BB_driverBrakeApply "Indicates whether the driver operates the brake pedal. Only active when the driver brakes, not when an external brake command implemented on brake booster (BB).";
CM_ SG_ 943 BB_driverBrakeApplyQF "Qualifier for BB_driverBrakeApply";
CM_ SG_ 943 BB_boosterStatus "Indication of the brake booster (BB) functional state";
CM_ SG_ 943 BB_warningLampRequest "Request from brake booster (BB) to enable the red brake lamp";
CM_ SG_ 943 BB_brakeFluidLevel "Indication of the brake fluid reservoir fluid level sensor status measured by the brake booster (BB).";
CM_ SG_ 943 BB_internalState "Indication of the brake booster (BB) internal state";
CM_ SG_ 943 BB_unfilteredFluidLevelLow "Indicates whether the unfiltered brake fluid level is detected as low.";
CM_ BO_ 1343 "High-voltage battery management system message: alert log";
CM_ SG_ 1343 BMS_alertID "High-voltage battery management system: alert ID; raw 127 = signal not available (SNA)";
CM_ SG_ 1343 BMS_alertSet "High-voltage battery management system: alert set";
CM_ SG_ 1343 BMS_a001_gatewayPackEnergy "High-voltage battery management system: a001 gateway pack energy";
CM_ SG_ 1343 BMS_a001_expectedPackEnergy "High-voltage battery management system: a001 expected pack energy";
CM_ SG_ 1343 BMS_a002_gatewayPackPerformanceD "High-voltage battery management system: a002 gateway pack performance deviation";
CM_ SG_ 1343 BMS_a002_expectedPackPerformance "High-voltage battery management system: a002 expected pack performance deviation";
CM_ SG_ 1343 BMS_a002_bmsPackMass "High-voltage battery management system: a002 bms pack mass";
CM_ SG_ 1343 BMS_a003_calBlockData_0 "High-voltage battery management system: a003 cal block data 0";
CM_ SG_ 1343 BMS_a017_packCurrent "High-voltage battery management system: a017 pack current";
CM_ SG_ 1343 BMS_a017_ovBrickVID "High-voltage battery management system: a017 ov brick VID";
CM_ SG_ 1343 BMS_a017_ovBrickV "High-voltage battery management system: a017 ov brick v";
CM_ SG_ 1343 BMS_a018_packCurrent "High-voltage battery management system: a018 pack current";
CM_ SG_ 1343 BMS_a018_uvBrickVID "High-voltage battery management system: a018 uv brick VID";
CM_ SG_ 1343 BMS_a018_uvBrickV "High-voltage battery management system: a018 uv brick v";
CM_ SG_ 1343 BMS_a019_coolantInletT "High-voltage battery management system: a019 coolant inlet t";
CM_ SG_ 1343 BMS_a019_activeCoolingTarget "High-voltage battery management system: a019 active cooling target";
CM_ SG_ 1343 BMS_a019_maxBrickT "High-voltage battery management system: a019 max brick t";
CM_ SG_ 1343 BMS_a019_maxBrickTID "High-voltage battery management system: a019 max brick TID";
CM_ SG_ 1343 BMS_a021_chargeViolation "High-voltage battery management system: a021 charge violation";
CM_ SG_ 1343 BMS_a021_currentLimit "High-voltage battery management system: a021 current limit";
CM_ SG_ 1343 BMS_a021_packCurrent "High-voltage battery management system: a021 pack current";
CM_ SG_ 1343 BMS_a022_chargeAccumulatorViolat "High-voltage battery management system: a022 charge accumulator violation";
CM_ SG_ 1343 BMS_a022_chargeAccumulatorValue "High-voltage battery management system: a022 charge accumulator value";
CM_ SG_ 1343 BMS_a022_chargeAccumulatorLimit "High-voltage battery management system: a022 charge accumulator limit";
CM_ SG_ 1343 BMS_a023_ovStackDeviceID "High-voltage battery management system: a023 ov stack device ID";
CM_ SG_ 1343 BMS_a023_ovStackV "High-voltage battery management system: a023 ov stack v";
CM_ SG_ 1343 BMS_a024_brickID "High-voltage battery management system: a024 brick ID";
CM_ SG_ 1343 BMS_a024_deltaV "High-voltage battery management system: a024 delta v";
CM_ SG_ 1343 BMS_a024_avgDvPrev "High-voltage battery management system: a024 avg dv prev";
CM_ SG_ 1343 BMS_a024_packCurrent "High-voltage battery management system: a024 pack current";
CM_ SG_ 1343 BMS_a027_swIsolationCount "High-voltage battery management system: a027 sw isolation count";
CM_ SG_ 1343 BMS_a030_worstBrickID "High-voltage battery management system: a030 worst brick ID";
CM_ SG_ 1343 BMS_a030_maxBrickImpedance "High-voltage battery management system: a030 max brick impedance";
CM_ SG_ 1343 BMS_a030_maxNormalizedImpedanceD "High-voltage battery management system: a030 max normalized impedance dev";
CM_ SG_ 1343 BMS_a030_faultThreshold "High-voltage battery management system: a030 fault threshold";
CM_ SG_ 1343 BMS_a030_numBricks "High-voltage battery management system: a030 num bricks";
CM_ SG_ 1343 BMS_a030_worstBrickSoc "High-voltage battery management system: a030 worst brick soc";
CM_ SG_ 1343 BMS_a035_isoR "High-voltage battery management system: a035 iso r";
CM_ SG_ 1343 BMS_a035_mode "High-voltage battery management system: a035 mode";
CM_ SG_ 1343 BMS_a035_activeSideVNoR "High-voltage battery management system: a035 active side v no r";
CM_ SG_ 1343 BMS_a035_activeSideVWithR "High-voltage battery management system: a035 active side v with r";
CM_ SG_ 1343 BMS_a035_passiveSideVNoR "High-voltage battery management system: a035 passive side v no r";
CM_ SG_ 1343 BMS_a035_passiveSideVWithR "High-voltage battery management system: a035 passive side v with r";
CM_ SG_ 1343 BMS_a039_dcLinkVoltage "High-voltage battery management system: a039 dc link voltage";
CM_ SG_ 1343 BMS_a039_packVoltage "High-voltage battery management system: a039 pack voltage";
CM_ SG_ 1343 BMS_a039_packContactorState "High-voltage battery management system: a039 pack contactor state; raw 0 = signal not available (SNA)";
CM_ SG_ 1343 BMS_a039_packCurrent "High-voltage battery management system: a039 pack current";
CM_ SG_ 1343 BMS_a039_maxBrickV "High-voltage battery management system: a039 max brick v";
CM_ SG_ 1343 BMS_a039_state "High-voltage battery management system: a039 state; raw 9 = signal not available (SNA)";
CM_ SG_ 1343 BMS_a041_resetType "High-voltage battery management system: a041 reset type";
CM_ SG_ 1343 BMS_a050_MIA_numBadReadings "High-voltage battery management system: a050 MIA num bad readings";
CM_ SG_ 1343 BMS_a050_MIA_numSnaReadings "High-voltage battery management system: a050 MIA num sna readings";
CM_ SG_ 1343 BMS_a050_MIA_brickId "High-voltage battery management system: a050 MIA brick id";
CM_ SG_ 1343 BMS_a051_hvp1V5Ref "High-voltage battery management system: a051 hvp1 V5 ref";
CM_ SG_ 1343 BMS_a051_hvp3V0Ref "High-voltage battery management system: a051 hvp3 V0 ref";
CM_ SG_ 1343 BMS_a051_bms3V0Ref "High-voltage battery management system: a051 bms3 V0 ref";
CM_ SG_ 1343 BMS_a059_sumBrickVoltages "High-voltage battery management system: a059 sum brick voltages";
CM_ SG_ 1343 BMS_a059_packVoltage "High-voltage battery management system: a059 pack voltage";
CM_ SG_ 1343 BMS_a062_state "High-voltage battery management system: a062 state; raw 9 = signal not available (SNA)";
CM_ SG_ 1343 BMS_a062_minBrickVId "High-voltage battery management system: a062 min brick v id";
CM_ SG_ 1343 BMS_a062_minBrickVoltage "High-voltage battery management system: a062 min brick voltage";
CM_ SG_ 1343 BMS_a062_maxBrickVId "High-voltage battery management system: a062 max brick v id";
CM_ SG_ 1343 BMS_a062_maxBrickVoltage "High-voltage battery management system: a062 max brick voltage";
CM_ SG_ 1343 BMS_a063_cpFaultInV "High-voltage battery management system: a063 cp fault in v";
CM_ SG_ 1343 BMS_a064_minBrickSOCID "High-voltage battery management system: a064 min brick SOCID";
CM_ SG_ 1343 BMS_a064_minBrickSOC "High-voltage battery management system: a064 min brick SOC";
CM_ SG_ 1343 BMS_a064_maxBrickSOCID "High-voltage battery management system: a064 max brick SOCID";
CM_ SG_ 1343 BMS_a064_maxBrickSOC "High-voltage battery management system: a064 max brick SOC";
CM_ SG_ 1343 BMS_a064_avgBrickSOC "High-voltage battery management system: a064 avg brick SOC";
CM_ SG_ 1343 BMS_a065_minBrickCacId "High-voltage battery management system: a065 min brick cac id";
CM_ SG_ 1343 BMS_a065_minBrickCac "High-voltage battery management system: a065 min brick cac";
CM_ SG_ 1343 BMS_a065_avgBrickCac "High-voltage battery management system: a065 avg brick cac";
CM_ SG_ 1343 BMS_a065_modCacImbalancePct "High-voltage battery management system: a065 mod cac imbalance pct";
CM_ SG_ 1343 BMS_a066_minBrickSocId "High-voltage battery management system: a066 min brick soc id";
CM_ SG_ 1343 BMS_a066_minBrickSocByOcvMax "High-voltage battery management system: a066 min brick soc by ocv max";
CM_ SG_ 1343 BMS_a066_maxBrickSocId "High-voltage battery management system: a066 max brick soc id";
CM_ SG_ 1343 BMS_a066_maxBrickSocByOcvMin "High-voltage battery management system: a066 max brick soc by ocv min";
CM_ SG_ 1343 BMS_a066_maxBrickSoc "High-voltage battery management system: a066 max brick soc";
CM_ SG_ 1343 BMS_a066_avgBrickSoc "High-voltage battery management system: a066 avg brick soc";
CM_ SG_ 1343 BMS_a067_minBrickCacId "High-voltage battery management system: a067 min brick cac id";
CM_ SG_ 1343 BMS_a067_minBrickCac "High-voltage battery management system: a067 min brick cac";
CM_ SG_ 1343 BMS_a067_avgBrickCac "High-voltage battery management system: a067 avg brick cac";
CM_ SG_ 1343 BMS_a067_modCacImbalancePct "High-voltage battery management system: a067 mod cac imbalance pct";
CM_ SG_ 1343 BMS_a068_minBrickCacId "High-voltage battery management system: a068 min brick cac id";
CM_ SG_ 1343 BMS_a068_minBrickCac "High-voltage battery management system: a068 min brick cac";
CM_ SG_ 1343 BMS_a068_avgBrickCac "High-voltage battery management system: a068 avg brick cac";
CM_ SG_ 1343 BMS_a068_modCacImbalancePct "High-voltage battery management system: a068 mod cac imbalance pct";
CM_ SG_ 1343 BMS_a069_dischargePowerPackVolta "High-voltage battery management system: a069 discharge power pack voltage floor";
CM_ SG_ 1343 BMS_a069_dischargePowerBrickVolt "High-voltage battery management system: a069 discharge power brick voltage floor";
CM_ SG_ 1343 BMS_a069_SOC "High-voltage battery management system: a069 SOC";
CM_ SG_ 1343 BMS_a069_minBrickT "High-voltage battery management system: a069 min brick t";
CM_ SG_ 1343 BMS_a069_minBrickVLimit "High-voltage battery management system: a069 min brick v limit";
CM_ SG_ 1343 BMS_a069_minBrickV "High-voltage battery management system: a069 min brick v";
CM_ SG_ 1343 BMS_a070_state "High-voltage battery management system: a070 state; raw 9 = signal not available (SNA)";
CM_ SG_ 1343 BMS_a070_minBrickVId "High-voltage battery management system: a070 min brick v id";
CM_ SG_ 1343 BMS_a070_minBrickVoltage "High-voltage battery management system: a070 min brick voltage";
CM_ SG_ 1343 BMS_a070_maxBrickVId "High-voltage battery management system: a070 max brick v id";
CM_ SG_ 1343 BMS_a070_maxBrickVoltage "High-voltage battery management system: a070 max brick voltage";
CM_ SG_ 1343 BMS_a071_stateRequest "High-voltage battery management system: a071 state request; raw 9 = signal not available (SNA)";
CM_ SG_ 1343 BMS_a071_state "High-voltage battery management system: a071 state; raw 9 = signal not available (SNA)";
CM_ SG_ 1343 BMS_a071_transitionAlertId "High-voltage battery management system: a071 transition alert id";
CM_ SG_ 1343 BMS_a074_maxBrickVTarget "High-voltage battery management system: a074 max brick v target";
CM_ SG_ 1343 BMS_a074_maxBrickV "High-voltage battery management system: a074 max brick v";
CM_ SG_ 1343 BMS_a075_chargeType "High-voltage battery management system: a075 charge type";
CM_ SG_ 1343 BMS_a076_netAh "High-voltage battery management system: a076 net ah";
CM_ SG_ 1343 BMS_a076_tetheringActive "High-voltage battery management system: a076 tethering active";
CM_ SG_ 1343 BMS_a077_chargeErrType "High-voltage battery management system: a077 charge err type";
CM_ SG_ 1343 BMS_a077_maxBrickVTarget "High-voltage battery management system: a077 max brick v target";
CM_ SG_ 1343 BMS_a077_maxBrickV "High-voltage battery management system: a077 max brick v";
CM_ SG_ 1343 BMS_a077_packTargetCurrent "High-voltage battery management system: a077 pack target current";
CM_ SG_ 1343 BMS_a077_packCurrent "High-voltage battery management system: a077 pack current";
CM_ SG_ 1343 BMS_a078_peakDchInChg "High-voltage battery management system: a078 peak dch in chg; raw 32768 = signal not available (SNA)";
CM_ SG_ 1343 BMS_a079_maxBrickVTarget "High-voltage battery management system: a079 max brick v target";
CM_ SG_ 1343 BMS_a079_maxBrickV "High-voltage battery management system: a079 max brick v";
CM_ SG_ 1343 BMS_a081_stateRequest "High-voltage battery management system: a081 state request; raw 9 = signal not available (SNA)";
CM_ SG_ 1343 BMS_a081_firstBlockingAlertId "High-voltage battery management system: a081 first blocking alert id; raw 127 = signal not available (SNA)";
CM_ SG_ 1343 BMS_a081_secondBlockingAlertId "High-voltage battery management system: a081 second blocking alert id; raw 127 = signal not available (SNA)";
CM_ SG_ 1343 BMS_a081_thirdBlockingAlertId "High-voltage battery management system: a081 third blocking alert id; raw 127 = signal not available (SNA)";
CM_ SG_ 1343 BMS_a081_fourthBlockingAlertId "High-voltage battery management system: a081 fourth blocking alert id; raw 127 = signal not available (SNA)";
CM_ SG_ 1343 BMS_a081_totalAlertCount "High-voltage battery management system: a081 total alert count";
CM_ SG_ 1343 BMS_a082_stateRequest "High-voltage battery management system: a082 state request; raw 9 = signal not available (SNA)";
CM_ SG_ 1343 BMS_a082_firstAlertId "High-voltage battery management system: a082 first alert id; raw 127 = signal not available (SNA)";
CM_ SG_ 1343 BMS_a082_secondAlertId "High-voltage battery management system: a082 second alert id; raw 127 = signal not available (SNA)";
CM_ SG_ 1343 BMS_a082_thirdAlertId "High-voltage battery management system: a082 third alert id; raw 127 = signal not available (SNA)";
CM_ SG_ 1343 BMS_a082_fourthAlertId "High-voltage battery management system: a082 fourth alert id; raw 127 = signal not available (SNA)";
CM_ SG_ 1343 BMS_a082_totalAlertCount "High-voltage battery management system: a082 total alert count";
CM_ SG_ 1343 BMS_a083_packContactorRequest "High-voltage battery management system: a083 pack contactor request; raw 0 = signal not available (SNA)";
CM_ SG_ 1343 BMS_a085_packContactorSetStatePr "High-voltage battery management system: a085 pack contactor set state prev; raw 0 = signal not available (SNA)";
CM_ SG_ 1343 BMS_a085_packContactorSetState "High-voltage battery management system: a085 pack contactor set state; raw 0 = signal not available (SNA)";
CM_ SG_ 1343 BMS_a085_packContactorSetRe_0001 "High-voltage battery management system: a085 pack contactor set request prev; raw 0 = signal not available (SNA)";
CM_ SG_ 1343 BMS_a085_packContactorSetRequest "High-voltage battery management system: a085 pack contactor set request; raw 0 = signal not available (SNA)";
CM_ SG_ 1343 BMS_a086_fcContactorSetStatePrev "High-voltage battery management system: a086 fc contactor set state prev; raw 0 = signal not available (SNA)";
CM_ SG_ 1343 BMS_a086_fcContactorSetState "High-voltage battery management system: a086 fc contactor set state; raw 0 = signal not available (SNA)";
CM_ SG_ 1343 BMS_a086_fcContactorSetRequestPr "High-voltage battery management system: a086 fc contactor set request prev; raw 0 = signal not available (SNA)";
CM_ SG_ 1343 BMS_a086_fcContactorSetRequest "High-voltage battery management system: a086 fc contactor set request; raw 0 = signal not available (SNA)";
CM_ SG_ 1343 BMS_a087_blockingAlert "High-voltage battery management system: a087 blocking alert; raw 127 = signal not available (SNA)";
CM_ SG_ 1343 BMS_a090_GTWmessageTout "High-voltage battery management system: a090 GT wmessage tout";
CM_ SG_ 1343 BMS_a098_breakLocationA "High-voltage battery management system: a098 break location a";
CM_ SG_ 1343 BMS_a098_bmbCommStatusTypeA "High-voltage battery management system: a098 bmb comm status type a";
CM_ SG_ 1343 BMS_a098_breakLocationB "High-voltage battery management system: a098 break location b";
CM_ SG_ 1343 BMS_a098_bmbCommStatusTypeB "High-voltage battery management system: a098 bmb comm status type b";
CM_ SG_ 1343 BMS_a098_alertFromHvp "High-voltage battery management system: a098 alert from hvp";
CM_ SG_ 1343 BMS_a099_breakLocationA "High-voltage battery management system: a099 break location a";
CM_ SG_ 1343 BMS_a099_bmbCommStatusTypeA "High-voltage battery management system: a099 bmb comm status type a";
CM_ SG_ 1343 BMS_a099_breakLocationB "High-voltage battery management system: a099 break location b";
CM_ SG_ 1343 BMS_a099_bmbCommStatusTypeB "High-voltage battery management system: a099 bmb comm status type b";
CM_ SG_ 1343 BMS_a099_bmbChainBreakType "High-voltage battery management system: a099 bmb chain break type";
CM_ SG_ 1343 BMS_a099_alertFromHvp "High-voltage battery management system: a099 alert from hvp";
CM_ SG_ 1343 BMS_a100_testTrigger "High-voltage battery management system: a100 test trigger";
CM_ SG_ 1343 BMS_a100_setFromNvm "High-voltage battery management system: a100 set from nvm";
CM_ SG_ 1343 BMS_a100_voltageDeviation "High-voltage battery management system: a100 voltage deviation";
CM_ SG_ 1343 BMS_a100_voltageLoss "High-voltage battery management system: a100 voltage loss";
CM_ SG_ 1343 BMS_a105_tSenseFailedModule1 "High-voltage battery management system: a105 t sense failed module1";
CM_ SG_ 1343 BMS_a105_avgBrickTModule1 "High-voltage battery management system: a105 avg brick t module1";
CM_ SG_ 1343 BMS_a105_tSenseFailedModule2 "High-voltage battery management system: a105 t sense failed module2";
CM_ SG_ 1343 BMS_a105_avgBrickTModule2 "High-voltage battery management system: a105 avg brick t module2";
CM_ SG_ 1343 BMS_a105_tSenseFailedModule3 "High-voltage battery management system: a105 t sense failed module3";
CM_ SG_ 1343 BMS_a105_avgBrickTModule3 "High-voltage battery management system: a105 avg brick t module3";
CM_ SG_ 1343 BMS_a105_tSenseFailedModule4 "High-voltage battery management system: a105 t sense failed module4";
CM_ SG_ 1343 BMS_a105_avgBrickTModule4 "High-voltage battery management system: a105 avg brick t module4";
CM_ SG_ 1343 BMS_a105_inletTemp "High-voltage battery management system: a105 inlet temp";
CM_ SG_ 1343 BMS_a106_minBrickT "High-voltage battery management system: a106 min brick t";
CM_ SG_ 1343 BMS_a106_maxBrickT "High-voltage battery management system: a106 max brick t";
CM_ SG_ 1343 BMS_a106_avgBrickT "High-voltage battery management system: a106 avg brick t";
CM_ SG_ 1343 BMS_a106_inletTemp "High-voltage battery management system: a106 inlet temp";
CM_ SG_ 1343 BMS_a107_MIA_numBadReadings "High-voltage battery management system: a107 MIA num bad readings";
CM_ SG_ 1343 BMS_a107_MIA_numSnaReadings "High-voltage battery management system: a107 MIA num sna readings";
CM_ SG_ 1343 BMS_a107_MIA_stackId "High-voltage battery management system: a107 MIA stack id";
CM_ SG_ 1343 BMS_a109_muteMask "High-voltage battery management system: a109 mute mask";
CM_ SG_ 1343 BMS_a109_packInBleed "High-voltage battery management system: a109 pack in bleed";
CM_ SG_ 1343 BMS_a117_brickID "High-voltage battery management system: a117 brick ID";
CM_ SG_ 1343 BMS_a117_brickSoc2 "High-voltage battery management system: a117 brick soc2; raw 1023 = signal not available (SNA)";
CM_ SG_ 1343 BMS_a117_dSocAlertThreshold "High-voltage battery management system: a117 d soc alert threshold";
CM_ SG_ 1343 BMS_a117_dSocAlpha "High-voltage battery management system: a117 d soc alpha; raw 4095 = signal not available (SNA)";
CM_ SG_ 1343 BMS_a118_brickID "High-voltage battery management system: a118 brick ID";
CM_ SG_ 1343 BMS_a118_brickSoc2 "High-voltage battery management system: a118 brick soc2; raw 1023 = signal not available (SNA)";
CM_ SG_ 1343 BMS_a118_dSocAlertThreshold "High-voltage battery management system: a118 d soc alert threshold";
CM_ SG_ 1343 BMS_a118_dSocAlpha "High-voltage battery management system: a118 d soc alpha; raw 4095 = signal not available (SNA)";
CM_ SG_ 1343 BMS_a122_thermistorID "High-voltage battery management system: a122 thermistor ID";
CM_ SG_ 1343 BMS_a122_irrationalThermistorTem "High-voltage battery management system: a122 irrational thermistor temp";
CM_ SG_ 1343 BMS_a122_averageRawThermistorTem "High-voltage battery management system: a122 average raw thermistor temp";
CM_ SG_ 1343 BMS_a122_minRawThermistorTemp "High-voltage battery management system: a122 min raw thermistor temp";
CM_ SG_ 1343 BMS_a122_maxRawThermistorTemp "High-voltage battery management system: a122 max raw thermistor temp";
CM_ SG_ 1343 BMS_a122_numValidThermistors "High-voltage battery management system: a122 num valid thermistors";
CM_ SG_ 1343 BMS_a123_packPlus "High-voltage battery management system: a123 pack plus";
CM_ SG_ 1343 BMS_a123_isoR "High-voltage battery management system: a123 iso r";
CM_ SG_ 1343 BMS_a123_packMinus "High-voltage battery management system: a123 pack minus";
CM_ SG_ 1343 BMS_a129_brickID "High-voltage battery management system: a129 brick ID";
CM_ SG_ 1343 BMS_a129_deltaV "High-voltage battery management system: a129 delta v";
CM_ SG_ 1343 BMS_a129_retryCount "High-voltage battery management system: a129 retry count";
CM_ SG_ 1343 BMS_a131_brickID "High-voltage battery management system: a131 brick ID";
CM_ SG_ 1343 BMS_a131_deltaV "High-voltage battery management system: a131 delta v";
CM_ SG_ 1343 BMS_a131_retryCount "High-voltage battery management system: a131 retry count";
CM_ SG_ 1343 BMS_a132_multiVendorErrorMask "High-voltage battery management system: a132 multi vendor error mask";
CM_ SG_ 1343 BMS_a135_bmbDiagnosticsType "High-voltage battery management system: a135 bmb diagnostics type";
CM_ SG_ 1343 BMS_a135_bmbDeviceId "High-voltage battery management system: a135 bmb device id";
CM_ SG_ 1343 BMS_a135_readCVA "High-voltage battery management system: a135 read CVA";
CM_ SG_ 1343 BMS_a135_readCVB "High-voltage battery management system: a135 read CVB";
CM_ SG_ 1343 BMS_a135_readCVC "High-voltage battery management system: a135 read CVC";
CM_ SG_ 1343 BMS_a135_readCVD "High-voltage battery management system: a135 read CVD";
CM_ SG_ 1343 BMS_a135_readCVE "High-voltage battery management system: a135 read CVE";
CM_ SG_ 1343 BMS_a135_readCVF "High-voltage battery management system: a135 read CVF";
CM_ SG_ 1343 BMS_a135_readSNA "High-voltage battery management system: a135 read SNA";
CM_ SG_ 1343 BMS_a135_readSNB "High-voltage battery management system: a135 read SNB";
CM_ SG_ 1343 BMS_a135_readSNC "High-voltage battery management system: a135 read SNC";
CM_ SG_ 1343 BMS_a135_readSND "High-voltage battery management system: a135 read SND";
CM_ SG_ 1343 BMS_a135_readSNE "High-voltage battery management system: a135 read SNE";
CM_ SG_ 1343 BMS_a135_readSNF "High-voltage battery management system: a135 read SNF";
CM_ SG_ 1343 BMS_a135_readAUXA "High-voltage battery management system: a135 read AUXA";
CM_ SG_ 1343 BMS_a135_readAUXB "High-voltage battery management system: a135 read AUXB";
CM_ SG_ 1343 BMS_a135_readSTAT "High-voltage battery management system: a135 read STAT";
CM_ SG_ 1343 BMS_a136_maxBrickTID "High-voltage battery management system: a136 max brick TID";
CM_ SG_ 1343 BMS_a136_coolantInletT "High-voltage battery management system: a136 coolant inlet t";
CM_ SG_ 1343 BMS_a136_activeCoolingTarget "High-voltage battery management system: a136 active cooling target";
CM_ SG_ 1343 BMS_a136_maxBrickT "High-voltage battery management system: a136 max brick t";
CM_ SG_ 1343 BMS_a139_packVoltage "High-voltage battery management system: a139 pack voltage";
CM_ SG_ 1343 BMS_a139_dcLinkVoltage "High-voltage battery management system: a139 dc link voltage";
CM_ SG_ 1343 BMS_a140_bmbDeviceMask "High-voltage battery management system: a140 bmb device mask";
CM_ SG_ 1343 BMS_a140_faultType "High-voltage battery management system: a140 fault type";
CM_ SG_ 1343 BMS_a142_isolationResistance "High-voltage battery management system: a142 isolation resistance";
CM_ SG_ 1343 BMS_a142_mode "High-voltage battery management system: a142 mode";
CM_ SG_ 1343 BMS_a143_initialSoc "High-voltage battery management system: a143 initial soc";
CM_ SG_ 1343 BMS_a143_endingSoc "High-voltage battery management system: a143 ending soc";
CM_ SG_ 1343 BMS_a143_deltaAh "High-voltage battery management system: a143 delta ah";
CM_ SG_ 1343 BMS_a143_cacChangeBrickID "High-voltage battery management system: a143 cac change brick ID";
CM_ SG_ 1343 BMS_a143_cacUpdateError "High-voltage battery management system: a143 cac update error";
CM_ SG_ 1343 BMS_a144_HVP_major_version "High-voltage battery management system: a144 HVP major version";
CM_ SG_ 1343 BMS_a144_HVP_minor_version "High-voltage battery management system: a144 HVP minor version";
CM_ SG_ 1343 BMS_a144_BMS_minor_version "High-voltage battery management system: a144 BMS minor version";
CM_ SG_ 1343 BMS_a145_maxSocChange "High-voltage battery management system: a145 max soc change";
CM_ SG_ 1343 BMS_a145_maxSocChangeBrickID "High-voltage battery management system: a145 max soc change brick ID";
CM_ SG_ 1343 BMS_a145_numBricksChanged "High-voltage battery management system: a145 num bricks changed";
CM_ SG_ 1343 BMS_a145_brickChangeHystRatio "High-voltage battery management system: a145 brick change hyst ratio; raw 1023 = signal not available (SNA)";
CM_ SG_ 1343 BMS_a146_maxBrickV "High-voltage battery management system: a146 max brick v";
CM_ SG_ 1343 BMS_a146_state "High-voltage battery management system: a146 state; raw 9 = signal not available (SNA)";
CM_ SG_ 1343 BMS_a146_packCurrent "High-voltage battery management system: a146 pack current";
CM_ SG_ 1343 BMS_a146_uvBrickVID "High-voltage battery management system: a146 uv brick VID";
CM_ SG_ 1343 BMS_a146_uvBrickV "High-voltage battery management system: a146 uv brick v";
CM_ SG_ 1343 BMS_a151_isoPositiveR "High-voltage battery management system: a151 iso positive r";
CM_ SG_ 1343 BMS_a151_isoNegativeR "High-voltage battery management system: a151 iso negative r";
CM_ SG_ 1343 BMS_a152_isoR "High-voltage battery management system: a152 iso r";
CM_ SG_ 1343 BMS_a152_mode "High-voltage battery management system: a152 mode";
CM_ SG_ 1343 BMS_a152_activeSideVNoR "High-voltage battery management system: a152 active side v no r";
CM_ SG_ 1343 BMS_a152_activeSideVWithR "High-voltage battery management system: a152 active side v with r";
CM_ SG_ 1343 BMS_a152_passiveSideVNoR "High-voltage battery management system: a152 passive side v no r";
CM_ SG_ 1343 BMS_a152_passiveSideVWithR "High-voltage battery management system: a152 passive side v with r";
CM_ SG_ 1343 BMS_a154_packCurrent "High-voltage battery management system: a154 pack current";
CM_ SG_ 1343 BMS_a154_ovBrickVID "High-voltage battery management system: a154 ov brick VID";
CM_ SG_ 1343 BMS_a154_ovBrickV "High-voltage battery management system: a154 ov brick v";
CM_ SG_ 1343 BMS_a156_VrefSample "High-voltage battery management system: a156 vref sample";
CM_ SG_ 1343 BMS_a156_bmbDeviceId "High-voltage battery management system: a156 bmb device id";
CM_ SG_ 1343 BMS_a156_VrefStatus "High-voltage battery management system: a156 vref status";
CM_ SG_ 1343 BMS_a158_shuntCurrentMia "High-voltage battery management system: a158 shunt current mia";
CM_ SG_ 1343 BMS_a158_contactorStateMia "High-voltage battery management system: a158 contactor state mia";
CM_ SG_ 1343 BMS_a158_hvpFaultsMia "High-voltage battery management system: a158 hvp faults mia";
CM_ SG_ 1343 BMS_a162_dischargePower_W "High-voltage battery management system: a162 discharge power w";
CM_ SG_ 1343 BMS_a162_minSoc "High-voltage battery management system: a162 min soc";
CM_ SG_ 1343 BMS_a162_socThreshold "High-voltage battery management system: a162 soc threshold";
CM_ SG_ 1343 BMS_a164_regenPower "High-voltage battery management system: a164 regen power";
CM_ SG_ 1343 BMS_a165_packPositiveV "High-voltage battery management system: a165 pack positive v";
CM_ SG_ 1343 BMS_a165_packNegativeV "High-voltage battery management system: a165 pack negative v";
CM_ SG_ 1343 BMS_a165_dcLinkPositiveV "High-voltage battery management system: a165 dc link positive v";
CM_ SG_ 1343 BMS_a165_dcLinkNegativeV "High-voltage battery management system: a165 dc link negative v";
CM_ SG_ 1343 BMS_a166_packPositiveV "High-voltage battery management system: a166 pack positive v";
CM_ SG_ 1343 BMS_a166_packNegativeV "High-voltage battery management system: a166 pack negative v";
CM_ SG_ 1343 BMS_a166_dcLinkPositiveV "High-voltage battery management system: a166 dc link positive v";
CM_ SG_ 1343 BMS_a166_dcLinkNegativeV "High-voltage battery management system: a166 dc link negative v";
CM_ SG_ 1343 BMS_a167_fcContPositiveAuxOpen "High-voltage battery management system: a167 fc cont positive aux open";
CM_ SG_ 1343 BMS_a167_fcContNegativeAuxOpen "High-voltage battery management system: a167 fc cont negative aux open";
CM_ SG_ 1343 BMS_a167_dcLinkPositiveV "High-voltage battery management system: a167 dc link positive v";
CM_ SG_ 1343 BMS_a167_dcLinkNegativeV "High-voltage battery management system: a167 dc link negative v";
CM_ SG_ 1343 BMS_a167_fcLinkPositiveV "High-voltage battery management system: a167 fc link positive v";
CM_ SG_ 1343 BMS_a167_fcLinkNegativeV "High-voltage battery management system: a167 fc link negative v";
CM_ SG_ 1343 BMS_a168_fcContPositiveAuxOpen "High-voltage battery management system: a168 fc cont positive aux open";
CM_ SG_ 1343 BMS_a168_fcContNegativeAuxOpen "High-voltage battery management system: a168 fc cont negative aux open";
CM_ SG_ 1343 BMS_a168_dcLinkPositiveV "High-voltage battery management system: a168 dc link positive v";
CM_ SG_ 1343 BMS_a168_dcLinkNegativeV "High-voltage battery management system: a168 dc link negative v";
CM_ SG_ 1343 BMS_a168_fcLinkPositiveV "High-voltage battery management system: a168 fc link positive v";
CM_ SG_ 1343 BMS_a168_fcLinkNegativeV "High-voltage battery management system: a168 fc link negative v";
CM_ SG_ 1343 BMS_a169_DCAndFCContactorsWelded "High-voltage battery management system: a169 DC and FC contactors welded";
CM_ SG_ 1343 BMS_a170_limpModeActive "High-voltage battery management system: a170 limp mode active";
CM_ SG_ 1343 BMS_a171_stackVoltage "High-voltage battery management system: a171 stack voltage";
CM_ SG_ 1343 BMS_a171_sumBrickVoltage "High-voltage battery management system: a171 sum brick voltage";
CM_ SG_ 1343 BMS_a171_stackId "High-voltage battery management system: a171 stack id";
CM_ SG_ 1343 BMS_a172_swIsolationCount "High-voltage battery management system: a172 sw isolation count";
CM_ SG_ 1343 BMS_a177_energyAlertThreshold "High-voltage battery management system: a177 energy alert threshold";
CM_ SG_ 1343 BMS_a177_energyBuffer "High-voltage battery management system: a177 energy buffer";
CM_ SG_ 1343 BMS_a178_diPower "High-voltage battery management system: a178 di power";
CM_ SG_ 1343 BMS_a178_energyError "High-voltage battery management system: a178 energy error";
CM_ SG_ 1343 BMS_a178_powerError "High-voltage battery management system: a178 power error";
CM_ SG_ 1343 BMS_a178_minPowerError "High-voltage battery management system: a178 min power error";
CM_ SG_ 1343 BMS_a178_maxPowerError "High-voltage battery management system: a178 max power error";
CM_ SG_ 1343 BMS_a178_diMiaCount "High-voltage battery management system: a178 di mia count";
CM_ SG_ 1343 BMS_a178_diSnaCount "High-voltage battery management system: a178 di sna count";
CM_ SG_ 1343 BMS_a188_currentTripThreshold "High-voltage battery management system: a188 current trip threshold";
CM_ SG_ 1343 BMS_a188_dcLinkDetectedCurrent "High-voltage battery management system: a188 dc link detected current";
CM_ SG_ 1343 BMS_a189_currentTripThreshold "High-voltage battery management system: a189 current trip threshold";
CM_ SG_ 1343 BMS_a189_dcLinkDetectedCurrent "High-voltage battery management system: a189 dc link detected current";
CM_ SG_ 1343 BMS_a190_voltageTripThreshold "High-voltage battery management system: a190 voltage trip threshold";
CM_ SG_ 1343 BMS_a190_dcLinkDetectedVoltage "High-voltage battery management system: a190 dc link detected voltage";
CM_ SG_ 1343 BMS_a191_voltageTripThreshold "High-voltage battery management system: a191 voltage trip threshold";
CM_ SG_ 1343 BMS_a191_dcLinkDetectedVoltage "High-voltage battery management system: a191 dc link detected voltage";
CM_ SG_ 1343 BMS_a192_detectedChargeCurrent "High-voltage battery management system: a192 detected charge current";
CM_ SG_ 1343 BMS_a193_maxBrickVoltageLimit "High-voltage battery management system: a193 max brick voltage limit";
CM_ SG_ 1343 BMS_a193_detectedMaxBrickVoltage "High-voltage battery management system: a193 detected max brick voltage";
CM_ SG_ 1343 BMS_a201_maxBrickV "High-voltage battery management system: a201 max brick v";
CM_ SG_ 1343 BMS_a201_maxBrickVIndex "High-voltage battery management system: a201 max brick v index";
CM_ SG_ 1343 BMS_a227_packCurrent "High-voltage battery management system: a227 pack current; raw 32768 = signal not available (SNA)";
CM_ SG_ 1343 BMS_a227_dcChargeCurrentRequest "High-voltage battery management system: a227 dc charge current request; raw 32768 = signal not available (SNA)";
CM_ SG_ 1343 BMS_a256_minBrickT "High-voltage battery management system: a256 min brick t";
CM_ SG_ 1343 BMS_a256_maxBrickT "High-voltage battery management system: a256 max brick t";
CM_ SG_ 1343 BMS_a256_minBrickV "High-voltage battery management system: a256 min brick v";
CM_ SG_ 1343 BMS_a256_maxBrickV "High-voltage battery management system: a256 max brick v";
CM_ SG_ 1343 BMS_a256_packSoe "High-voltage battery management system: a256 pack soe";
CM_ SG_ 1343 BMS_a256_SOC "High-voltage battery management system: a256 SOC";
BA_DEF_ BO_ "GenMsgCycleTime" INT 0 3600000;
BA_DEF_ BO_ "GenMsgSendType" ENUM "Cyclic","NotUsed","NotUsed","NotUsed","NotUsed","NotUsed","NotUsed","IfActive","NoMsgSendType","NotUsed";
BA_DEF_ BO_ "VFrameFormat" ENUM "StandardCAN","ExtendedCAN","reserved","J1939PG","reserved","reserved","reserved","reserved","reserved","reserved","reserved","reserved","reserved","reserved","StandardCAN_FD","ExtendedCAN_FD";
BA_DEF_ BO_ "CANFD_BRS" ENUM "0","1";
BA_DEF_ SG_ "GenSigSNA" STRING;
BA_DEF_ SG_ "SystemSignalLongSymbol" STRING;
BA_DEF_ SG_ "Confidence" ENUM "validated","plausible","layout-only","contradicted";
BA_DEF_DEF_ "GenMsgCycleTime" 0;
BA_DEF_DEF_ "GenMsgSendType" "NoMsgSendType";
BA_DEF_DEF_ "VFrameFormat" "StandardCAN";
BA_DEF_DEF_ "CANFD_BRS" "1";
BA_DEF_DEF_ "GenSigSNA" "";
BA_DEF_DEF_ "SystemSignalLongSymbol" "";
BA_DEF_DEF_ "Confidence" "layout-only";
BA_ "GenMsgCycleTime" BO_ 1113 1000;
BA_ "GenMsgSendType" BO_ 1113 0;
BA_ "GenMsgCycleTime" BO_ 848 1000;
BA_ "GenMsgSendType" BO_ 848 0;
BA_ "GenMsgCycleTime" BO_ 784 1000;
BA_ "GenMsgSendType" BO_ 784 0;
BA_ "GenMsgCycleTime" BO_ 943 10;
BA_ "GenMsgSendType" BO_ 943 0;
BA_ "SystemSignalLongSymbol" SG_ 848 APS_w245_eloopRxFromUnexpectedSo "APS_w245_eloopRxFromUnexpectedSourceMAC";
BA_ "SystemSignalLongSymbol" SG_ 848 APS_w246_ethloopSwitchPortLinkDo "APS_w246_ethloopSwitchPortLinkDown";
BA_ "SystemSignalLongSymbol" SG_ 848 APS_w250_ethloopSwitchMemUsageTo "APS_w250_ethloopSwitchMemUsageTooHighPort2";
BA_ "SystemSignalLongSymbol" SG_ 848 APS_w251_ethloopSwitchMemUsageTo "APS_w251_ethloopSwitchMemUsageTooHighPort3";
BA_ "SystemSignalLongSymbol" SG_ 784 APS_w258_qspiFlashSectorChecksum "APS_w258_qspiFlashSectorChecksumMismatch";
BA_ "SystemSignalLongSymbol" SG_ 784 APS_w269_ethSwitchRxPageCountToo "APS_w269_ethSwitchRxPageCountTooHighPort0_3";
BA_ "SystemSignalLongSymbol" SG_ 784 APS_w270_ethSwitchRxPageCountToo "APS_w270_ethSwitchRxPageCountTooHighPort4_7";
BA_ "SystemSignalLongSymbol" SG_ 784 APS_w284_cam12VBuckBoostAPwrIssu "APS_w284_cam12VBuckBoostAPwrIssue";
BA_ "SystemSignalLongSymbol" SG_ 784 APS_w285_cam12VBuckBoostBPwrIssu "APS_w285_cam12VBuckBoostBPwrIssue";
BA_ "SystemSignalLongSymbol" SG_ 784 APS_w286_cam12VEFuseAPrimaryIssu "APS_w286_cam12VEFuseAPrimaryIssue";
BA_ "SystemSignalLongSymbol" SG_ 784 APS_w287_cam12VEFuseASecondaryIs "APS_w287_cam12VEFuseASecondaryIssue";
BA_ "SystemSignalLongSymbol" SG_ 784 APS_w290_cam12VBuckBoostBPwrRing "APS_w290_cam12VBuckBoostBPwrRinging";
BA_ "SystemSignalLongSymbol" SG_ 784 APS_w298_cpuToApCanSharedMemErro "APS_w298_cpuToApCanSharedMemError";
BA_ "SystemSignalLongSymbol" SG_ 784 APS_w299_apToCpuCanSharedMemErro "APS_w299_apToCpuCanSharedMemError";
BA_ "SystemSignalLongSymbol" SG_ 784 APS_w318_ethernetNetworkBufferHi "APS_w318_ethernetNetworkBufferHighWatermark";
BA_ "SystemSignalLongSymbol" SG_ 784 APS_w320_eplannerPreconditionsMe "APS_w320_eplannerPreconditionsMet";
BA_ "Confidence" SG_ 943 BB_statusChecksum 0;
BA_ "Confidence" SG_ 943 BB_statusCounter 0;
BA_ "Confidence" SG_ 943 BB_sOutputRod 0;
BA_ "Confidence" SG_ 943 BB_sOutputRodQF 0;
BA_ "Confidence" SG_ 943 BB_sInputRod 0;
BA_ "Confidence" SG_ 943 BB_sInputRodQF 0;
BA_ "Confidence" SG_ 943 BB_driverBrakeApply 0;
BA_ "Confidence" SG_ 943 BB_driverBrakeApplyQF 0;
BA_ "Confidence" SG_ 943 BB_boosterStatus 0;
BA_ "Confidence" SG_ 943 BB_warningLampRequest 0;
BA_ "Confidence" SG_ 943 BB_brakeFluidLevel 0;
BA_ "Confidence" SG_ 943 BB_internalState 0;
BA_ "Confidence" SG_ 943 BB_unfilteredFluidLevelLow 0;
BA_ "Confidence" SG_ 1343 BMS_alertID 1;
BA_ "GenSigSNA" SG_ 1343 BMS_alertID "127";
BA_ "Confidence" SG_ 1343 BMS_alertSet 1;
BA_ "Confidence" SG_ 1343 BMS_a001_gatewayPackEnergy 1;
BA_ "Confidence" SG_ 1343 BMS_a001_expectedPackEnergy 1;
BA_ "Confidence" SG_ 1343 BMS_a002_gatewayPackPerformanceD 1;
BA_ "SystemSignalLongSymbol" SG_ 1343 BMS_a002_gatewayPackPerformanceD "BMS_a002_gatewayPackPerformanceDeviation";
BA_ "Confidence" SG_ 1343 BMS_a002_expectedPackPerformance 1;
BA_ "SystemSignalLongSymbol" SG_ 1343 BMS_a002_expectedPackPerformance "BMS_a002_expectedPackPerformanceDeviation";
BA_ "Confidence" SG_ 1343 BMS_a002_bmsPackMass 1;
BA_ "Confidence" SG_ 1343 BMS_a017_packCurrent 1;
BA_ "Confidence" SG_ 1343 BMS_a017_ovBrickV 1;
BA_ "Confidence" SG_ 1343 BMS_a018_packCurrent 1;
BA_ "Confidence" SG_ 1343 BMS_a018_uvBrickV 1;
BA_ "Confidence" SG_ 1343 BMS_a019_coolantInletT 1;
BA_ "Confidence" SG_ 1343 BMS_a019_activeCoolingTarget 1;
BA_ "Confidence" SG_ 1343 BMS_a019_maxBrickT 1;
BA_ "Confidence" SG_ 1343 BMS_a021_currentLimit 1;
BA_ "Confidence" SG_ 1343 BMS_a021_packCurrent 1;
BA_ "SystemSignalLongSymbol" SG_ 1343 BMS_a022_chargeAccumulatorViolat "BMS_a022_chargeAccumulatorViolation";
BA_ "Confidence" SG_ 1343 BMS_a022_chargeAccumulatorValue 1;
BA_ "Confidence" SG_ 1343 BMS_a022_chargeAccumulatorLimit 1;
BA_ "Confidence" SG_ 1343 BMS_a023_ovStackDeviceID 1;
BA_ "Confidence" SG_ 1343 BMS_a023_ovStackV 1;
BA_ "Confidence" SG_ 1343 BMS_a024_brickID 1;
BA_ "Confidence" SG_ 1343 BMS_a024_deltaV 1;
BA_ "Confidence" SG_ 1343 BMS_a024_avgDvPrev 1;
BA_ "Confidence" SG_ 1343 BMS_a024_packCurrent 1;
BA_ "Confidence" SG_ 1343 BMS_a030_maxBrickImpedance 1;
BA_ "Confidence" SG_ 1343 BMS_a030_maxNormalizedImpedanceD 1;
BA_ "SystemSignalLongSymbol" SG_ 1343 BMS_a030_maxNormalizedImpedanceD "BMS_a030_maxNormalizedImpedanceDev";
BA_ "Confidence" SG_ 1343 BMS_a030_faultThreshold 1;
BA_ "Confidence" SG_ 1343 BMS_a030_worstBrickSoc 1;
BA_ "Confidence" SG_ 1343 BMS_a035_isoR 1;
BA_ "Confidence" SG_ 1343 BMS_a035_mode 1;
BA_ "Confidence" SG_ 1343 BMS_a035_activeSideVNoR 1;
BA_ "Confidence" SG_ 1343 BMS_a035_activeSideVWithR 1;
BA_ "Confidence" SG_ 1343 BMS_a035_passiveSideVNoR 1;
BA_ "Confidence" SG_ 1343 BMS_a035_passiveSideVWithR 1;
BA_ "Confidence" SG_ 1343 BMS_a039_dcLinkVoltage 1;
BA_ "Confidence" SG_ 1343 BMS_a039_packVoltage 1;
BA_ "Confidence" SG_ 1343 BMS_a039_packContactorState 1;
BA_ "GenSigSNA" SG_ 1343 BMS_a039_packContactorState "0";
BA_ "Confidence" SG_ 1343 BMS_a039_packCurrent 1;
BA_ "Confidence" SG_ 1343 BMS_a039_maxBrickV 1;
BA_ "Confidence" SG_ 1343 BMS_a039_state 1;
BA_ "GenSigSNA" SG_ 1343 BMS_a039_state "9";
BA_ "Confidence" SG_ 1343 BMS_a041_resetType 1;
BA_ "Confidence" SG_ 1343 BMS_a051_hvp1V5Ref 1;
BA_ "Confidence" SG_ 1343 BMS_a051_hvp3V0Ref 1;
BA_ "Confidence" SG_ 1343 BMS_a051_bms3V0Ref 1;
BA_ "Confidence" SG_ 1343 BMS_a059_sumBrickVoltages 1;
BA_ "Confidence" SG_ 1343 BMS_a059_packVoltage 1;
BA_ "Confidence" SG_ 1343 BMS_a062_state 1;
BA_ "GenSigSNA" SG_ 1343 BMS_a062_state "9";
BA_ "Confidence" SG_ 1343 BMS_a062_minBrickVoltage 1;
BA_ "Confidence" SG_ 1343 BMS_a062_maxBrickVoltage 1;
BA_ "Confidence" SG_ 1343 BMS_a063_cpFaultInV 1;
BA_ "Confidence" SG_ 1343 BMS_a064_minBrickSOC 1;
BA_ "Confidence" SG_ 1343 BMS_a064_maxBrickSOC 1;
BA_ "Confidence" SG_ 1343 BMS_a064_avgBrickSOC 1;
BA_ "Confidence" SG_ 1343 BMS_a065_minBrickCac 1;
BA_ "Confidence" SG_ 1343 BMS_a065_avgBrickCac 1;
BA_ "Confidence" SG_ 1343 BMS_a065_modCacImbalancePct 1;
BA_ "Confidence" SG_ 1343 BMS_a066_minBrickSocByOcvMax 1;
BA_ "Confidence" SG_ 1343 BMS_a066_maxBrickSocByOcvMin 1;
BA_ "Confidence" SG_ 1343 BMS_a066_maxBrickSoc 1;
BA_ "Confidence" SG_ 1343 BMS_a066_avgBrickSoc 1;
BA_ "Confidence" SG_ 1343 BMS_a067_minBrickCac 1;
BA_ "Confidence" SG_ 1343 BMS_a067_avgBrickCac 1;
BA_ "Confidence" SG_ 1343 BMS_a067_modCacImbalancePct 1;
BA_ "Confidence" SG_ 1343 BMS_a068_minBrickCac 1;
BA_ "Confidence" SG_ 1343 BMS_a068_avgBrickCac 1;
BA_ "Confidence" SG_ 1343 BMS_a068_modCacImbalancePct 1;
BA_ "Confidence" SG_ 1343 BMS_a069_dischargePowerPackVolta 1;
BA_ "SystemSignalLongSymbol" SG_ 1343 BMS_a069_dischargePowerPackVolta "BMS_a069_dischargePowerPackVoltageFloor";
BA_ "Confidence" SG_ 1343 BMS_a069_dischargePowerBrickVolt 1;
BA_ "SystemSignalLongSymbol" SG_ 1343 BMS_a069_dischargePowerBrickVolt "BMS_a069_dischargePowerBrickVoltageFloor";
BA_ "Confidence" SG_ 1343 BMS_a069_SOC 1;
BA_ "Confidence" SG_ 1343 BMS_a069_minBrickT 1;
BA_ "Confidence" SG_ 1343 BMS_a069_minBrickVLimit 1;
BA_ "Confidence" SG_ 1343 BMS_a069_minBrickV 1;
BA_ "Confidence" SG_ 1343 BMS_a070_state 1;
BA_ "GenSigSNA" SG_ 1343 BMS_a070_state "9";
BA_ "Confidence" SG_ 1343 BMS_a070_minBrickVoltage 1;
BA_ "Confidence" SG_ 1343 BMS_a070_maxBrickVoltage 1;
BA_ "Confidence" SG_ 1343 BMS_a071_stateRequest 1;
BA_ "GenSigSNA" SG_ 1343 BMS_a071_stateRequest "9";
BA_ "Confidence" SG_ 1343 BMS_a071_state 1;
BA_ "GenSigSNA" SG_ 1343 BMS_a071_state "9";
BA_ "Confidence" SG_ 1343 BMS_a074_maxBrickVTarget 1;
BA_ "Confidence" SG_ 1343 BMS_a074_maxBrickV 1;
BA_ "Confidence" SG_ 1343 BMS_a075_chargeType 1;
BA_ "Confidence" SG_ 1343 BMS_a076_netAh 1;
BA_ "Confidence" SG_ 1343 BMS_a077_chargeErrType 1;
BA_ "Confidence" SG_ 1343 BMS_a077_maxBrickVTarget 1;
BA_ "Confidence" SG_ 1343 BMS_a077_maxBrickV 1;
BA_ "Confidence" SG_ 1343 BMS_a077_packTargetCurrent 1;
BA_ "Confidence" SG_ 1343 BMS_a077_packCurrent 1;
BA_ "Confidence" SG_ 1343 BMS_a078_peakDchInChg 1;
BA_ "GenSigSNA" SG_ 1343 BMS_a078_peakDchInChg "32768";
BA_ "Confidence" SG_ 1343 BMS_a079_maxBrickVTarget 1;
BA_ "Confidence" SG_ 1343 BMS_a079_maxBrickV 1;
BA_ "Confidence" SG_ 1343 BMS_a081_stateRequest 1;
BA_ "GenSigSNA" SG_ 1343 BMS_a081_stateRequest "9";
BA_ "Confidence" SG_ 1343 BMS_a081_firstBlockingAlertId 1;
BA_ "GenSigSNA" SG_ 1343 BMS_a081_firstBlockingAlertId "127";
BA_ "Confidence" SG_ 1343 BMS_a081_secondBlockingAlertId 1;
BA_ "GenSigSNA" SG_ 1343 BMS_a081_secondBlockingAlertId "127";
BA_ "Confidence" SG_ 1343 BMS_a081_thirdBlockingAlertId 1;
BA_ "GenSigSNA" SG_ 1343 BMS_a081_thirdBlockingAlertId "127";
BA_ "Confidence" SG_ 1343 BMS_a081_fourthBlockingAlertId 1;
BA_ "GenSigSNA" SG_ 1343 BMS_a081_fourthBlockingAlertId "127";
BA_ "Confidence" SG_ 1343 BMS_a082_stateRequest 1;
BA_ "GenSigSNA" SG_ 1343 BMS_a082_stateRequest "9";
BA_ "Confidence" SG_ 1343 BMS_a082_firstAlertId 1;
BA_ "GenSigSNA" SG_ 1343 BMS_a082_firstAlertId "127";
BA_ "Confidence" SG_ 1343 BMS_a082_secondAlertId 1;
BA_ "GenSigSNA" SG_ 1343 BMS_a082_secondAlertId "127";
BA_ "Confidence" SG_ 1343 BMS_a082_thirdAlertId 1;
BA_ "GenSigSNA" SG_ 1343 BMS_a082_thirdAlertId "127";
BA_ "Confidence" SG_ 1343 BMS_a082_fourthAlertId 1;
BA_ "GenSigSNA" SG_ 1343 BMS_a082_fourthAlertId "127";
BA_ "Confidence" SG_ 1343 BMS_a083_packContactorRequest 1;
BA_ "GenSigSNA" SG_ 1343 BMS_a083_packContactorRequest "0";
BA_ "Confidence" SG_ 1343 BMS_a085_packContactorSetStatePr 1;
BA_ "GenSigSNA" SG_ 1343 BMS_a085_packContactorSetStatePr "0";
BA_ "SystemSignalLongSymbol" SG_ 1343 BMS_a085_packContactorSetStatePr "BMS_a085_packContactorSetStatePrev";
BA_ "Confidence" SG_ 1343 BMS_a085_packContactorSetState 1;
BA_ "GenSigSNA" SG_ 1343 BMS_a085_packContactorSetState "0";
BA_ "Confidence" SG_ 1343 BMS_a085_packContactorSetRe_0001 1;
BA_ "GenSigSNA" SG_ 1343 BMS_a085_packContactorSetRe_0001 "0";
BA_ "SystemSignalLongSymbol" SG_ 1343 BMS_a085_packContactorSetRe_0001 "BMS_a085_packContactorSetRequestPrev";
BA_ "Confidence" SG_ 1343 BMS_a085_packContactorSetRequest 1;
BA_ "GenSigSNA" SG_ 1343 BMS_a085_packContactorSetRequest "0";
BA_ "Confidence" SG_ 1343 BMS_a086_fcContactorSetStatePrev 1;
BA_ "GenSigSNA" SG_ 1343 BMS_a086_fcContactorSetStatePrev "0";
BA_ "Confidence" SG_ 1343 BMS_a086_fcContactorSetState 1;
BA_ "GenSigSNA" SG_ 1343 BMS_a086_fcContactorSetState "0";
BA_ "Confidence" SG_ 1343 BMS_a086_fcContactorSetRequestPr 1;
BA_ "GenSigSNA" SG_ 1343 BMS_a086_fcContactorSetRequestPr "0";
BA_ "SystemSignalLongSymbol" SG_ 1343 BMS_a086_fcContactorSetRequestPr "BMS_a086_fcContactorSetRequestPrev";
BA_ "Confidence" SG_ 1343 BMS_a086_fcContactorSetRequest 1;
BA_ "GenSigSNA" SG_ 1343 BMS_a086_fcContactorSetRequest "0";
BA_ "Confidence" SG_ 1343 BMS_a087_blockingAlert 1;
BA_ "GenSigSNA" SG_ 1343 BMS_a087_blockingAlert "127";
BA_ "Confidence" SG_ 1343 BMS_a090_GTWmessageTout 1;
BA_ "Confidence" SG_ 1343 BMS_a098_bmbCommStatusTypeA 1;
BA_ "Confidence" SG_ 1343 BMS_a098_bmbCommStatusTypeB 1;
BA_ "Confidence" SG_ 1343 BMS_a099_bmbCommStatusTypeA 1;
BA_ "Confidence" SG_ 1343 BMS_a099_bmbCommStatusTypeB 1;
BA_ "Confidence" SG_ 1343 BMS_a099_bmbChainBreakType 1;
BA_ "Confidence" SG_ 1343 BMS_a105_avgBrickTModule1 1;
BA_ "Confidence" SG_ 1343 BMS_a105_avgBrickTModule2 1;
BA_ "Confidence" SG_ 1343 BMS_a105_avgBrickTModule3 1;
BA_ "Confidence" SG_ 1343 BMS_a105_avgBrickTModule4 1;
BA_ "Confidence" SG_ 1343 BMS_a105_inletTemp 1;
BA_ "Confidence" SG_ 1343 BMS_a106_minBrickT 1;
BA_ "Confidence" SG_ 1343 BMS_a106_maxBrickT 1;
BA_ "Confidence" SG_ 1343 BMS_a106_avgBrickT 1;
BA_ "Confidence" SG_ 1343 BMS_a106_inletTemp 1;
BA_ "Confidence" SG_ 1343 BMS_a117_brickSoc2 1;
BA_ "GenSigSNA" SG_ 1343 BMS_a117_brickSoc2 "1023";
BA_ "Confidence" SG_ 1343 BMS_a117_dSocAlertThreshold 1;
BA_ "Confidence" SG_ 1343 BMS_a117_dSocAlpha 1;
BA_ "GenSigSNA" SG_ 1343 BMS_a117_dSocAlpha "4095";
BA_ "Confidence" SG_ 1343 BMS_a118_brickSoc2 1;
BA_ "GenSigSNA" SG_ 1343 BMS_a118_brickSoc2 "1023";
BA_ "Confidence" SG_ 1343 BMS_a118_dSocAlertThreshold 1;
BA_ "Confidence" SG_ 1343 BMS_a118_dSocAlpha 1;
BA_ "GenSigSNA" SG_ 1343 BMS_a118_dSocAlpha "4095";
BA_ "Confidence" SG_ 1343 BMS_a122_irrationalThermistorTem 1;
BA_ "SystemSignalLongSymbol" SG_ 1343 BMS_a122_irrationalThermistorTem "BMS_a122_irrationalThermistorTemp";
BA_ "Confidence" SG_ 1343 BMS_a122_averageRawThermistorTem 1;
BA_ "SystemSignalLongSymbol" SG_ 1343 BMS_a122_averageRawThermistorTem "BMS_a122_averageRawThermistorTemp";
BA_ "Confidence" SG_ 1343 BMS_a122_minRawThermistorTemp 1;
BA_ "Confidence" SG_ 1343 BMS_a122_maxRawThermistorTemp 1;
BA_ "Confidence" SG_ 1343 BMS_a123_packPlus 1;
BA_ "Confidence" SG_ 1343 BMS_a123_isoR 1;
BA_ "Confidence" SG_ 1343 BMS_a123_packMinus 1;
BA_ "Confidence" SG_ 1343 BMS_a129_brickID 1;
BA_ "Confidence" SG_ 1343 BMS_a129_deltaV 1;
BA_ "Confidence" SG_ 1343 BMS_a129_retryCount 1;
BA_ "Confidence" SG_ 1343 BMS_a131_brickID 1;
BA_ "Confidence" SG_ 1343 BMS_a131_deltaV 1;
BA_ "Confidence" SG_ 1343 BMS_a131_retryCount 1;
BA_ "Confidence" SG_ 1343 BMS_a135_bmbDiagnosticsType 1;
BA_ "Confidence" SG_ 1343 BMS_a136_coolantInletT 1;
BA_ "Confidence" SG_ 1343 BMS_a136_activeCoolingTarget 1;
BA_ "Confidence" SG_ 1343 BMS_a136_maxBrickT 1;
BA_ "Confidence" SG_ 1343 BMS_a139_packVoltage 1;
BA_ "Confidence" SG_ 1343 BMS_a139_dcLinkVoltage 1;
BA_ "Confidence" SG_ 1343 BMS_a140_faultType 1;
BA_ "Confidence" SG_ 1343 BMS_a142_isolationResistance 1;
BA_ "Confidence" SG_ 1343 BMS_a142_mode 1;
BA_ "Confidence" SG_ 1343 BMS_a143_initialSoc 1;
BA_ "Confidence" SG_ 1343 BMS_a143_endingSoc 1;
BA_ "Confidence" SG_ 1343 BMS_a143_deltaAh 1;
BA_ "Confidence" SG_ 1343 BMS_a143_cacUpdateError 1;
BA_ "Confidence" SG_ 1343 BMS_a145_maxSocChange 1;
BA_ "Confidence" SG_ 1343 BMS_a145_brickChangeHystRatio 1;
BA_ "GenSigSNA" SG_ 1343 BMS_a145_brickChangeHystRatio "1023";
BA_ "Confidence" SG_ 1343 BMS_a146_maxBrickV 1;
BA_ "Confidence" SG_ 1343 BMS_a146_state 1;
BA_ "GenSigSNA" SG_ 1343 BMS_a146_state "9";
BA_ "Confidence" SG_ 1343 BMS_a146_packCurrent 1;
BA_ "Confidence" SG_ 1343 BMS_a146_uvBrickV 1;
BA_ "Confidence" SG_ 1343 BMS_a151_isoPositiveR 1;
BA_ "Confidence" SG_ 1343 BMS_a151_isoNegativeR 1;
BA_ "Confidence" SG_ 1343 BMS_a152_isoR 1;
BA_ "Confidence" SG_ 1343 BMS_a152_mode 1;
BA_ "Confidence" SG_ 1343 BMS_a152_activeSideVNoR 1;
BA_ "Confidence" SG_ 1343 BMS_a152_activeSideVWithR 1;
BA_ "Confidence" SG_ 1343 BMS_a152_passiveSideVNoR 1;
BA_ "Confidence" SG_ 1343 BMS_a152_passiveSideVWithR 1;
BA_ "Confidence" SG_ 1343 BMS_a154_packCurrent 1;
BA_ "Confidence" SG_ 1343 BMS_a154_ovBrickV 1;
BA_ "Confidence" SG_ 1343 BMS_a156_VrefSample 1;
BA_ "Confidence" SG_ 1343 BMS_a156_VrefStatus 1;
BA_ "Confidence" SG_ 1343 BMS_a162_dischargePower_W 1;
BA_ "Confidence" SG_ 1343 BMS_a162_minSoc 1;
BA_ "Confidence" SG_ 1343 BMS_a162_socThreshold 1;
BA_ "Confidence" SG_ 1343 BMS_a164_regenPower 1;
BA_ "Confidence" SG_ 1343 BMS_a165_packPositiveV 1;
BA_ "Confidence" SG_ 1343 BMS_a165_packNegativeV 1;
BA_ "Confidence" SG_ 1343 BMS_a165_dcLinkPositiveV 1;
BA_ "Confidence" SG_ 1343 BMS_a165_dcLinkNegativeV 1;
BA_ "Confidence" SG_ 1343 BMS_a166_packPositiveV 1;
BA_ "Confidence" SG_ 1343 BMS_a166_packNegativeV 1;
BA_ "Confidence" SG_ 1343 BMS_a166_dcLinkPositiveV 1;
BA_ "Confidence" SG_ 1343 BMS_a166_dcLinkNegativeV 1;
BA_ "Confidence" SG_ 1343 BMS_a167_dcLinkPositiveV 1;
BA_ "Confidence" SG_ 1343 BMS_a167_dcLinkNegativeV 1;
BA_ "Confidence" SG_ 1343 BMS_a167_fcLinkPositiveV 1;
BA_ "Confidence" SG_ 1343 BMS_a167_fcLinkNegativeV 1;
BA_ "Confidence" SG_ 1343 BMS_a168_dcLinkPositiveV 1;
BA_ "Confidence" SG_ 1343 BMS_a168_dcLinkNegativeV 1;
BA_ "Confidence" SG_ 1343 BMS_a168_fcLinkPositiveV 1;
BA_ "Confidence" SG_ 1343 BMS_a168_fcLinkNegativeV 1;
BA_ "Confidence" SG_ 1343 BMS_a171_stackVoltage 1;
BA_ "Confidence" SG_ 1343 BMS_a171_sumBrickVoltage 1;
BA_ "Confidence" SG_ 1343 BMS_a177_energyAlertThreshold 1;
BA_ "Confidence" SG_ 1343 BMS_a177_energyBuffer 1;
BA_ "Confidence" SG_ 1343 BMS_a178_diPower 1;
BA_ "Confidence" SG_ 1343 BMS_a178_energyError 1;
BA_ "Confidence" SG_ 1343 BMS_a178_powerError 1;
BA_ "Confidence" SG_ 1343 BMS_a178_minPowerError 1;
BA_ "Confidence" SG_ 1343 BMS_a178_maxPowerError 1;
BA_ "Confidence" SG_ 1343 BMS_a188_currentTripThreshold 1;
BA_ "Confidence" SG_ 1343 BMS_a188_dcLinkDetectedCurrent 1;
BA_ "Confidence" SG_ 1343 BMS_a189_currentTripThreshold 1;
BA_ "Confidence" SG_ 1343 BMS_a189_dcLinkDetectedCurrent 1;
BA_ "Confidence" SG_ 1343 BMS_a190_voltageTripThreshold 1;
BA_ "Confidence" SG_ 1343 BMS_a190_dcLinkDetectedVoltage 1;
BA_ "Confidence" SG_ 1343 BMS_a191_voltageTripThreshold 1;
BA_ "Confidence" SG_ 1343 BMS_a191_dcLinkDetectedVoltage 1;
BA_ "Confidence" SG_ 1343 BMS_a192_detectedChargeCurrent 1;
BA_ "Confidence" SG_ 1343 BMS_a193_maxBrickVoltageLimit 1;
BA_ "Confidence" SG_ 1343 BMS_a193_detectedMaxBrickVoltage 1;
BA_ "Confidence" SG_ 1343 BMS_a201_maxBrickV 1;
BA_ "Confidence" SG_ 1343 BMS_a227_packCurrent 1;
BA_ "GenSigSNA" SG_ 1343 BMS_a227_packCurrent "32768";
BA_ "Confidence" SG_ 1343 BMS_a227_dcChargeCurrentRequest 1;
BA_ "GenSigSNA" SG_ 1343 BMS_a227_dcChargeCurrentRequest "32768";
BA_ "Confidence" SG_ 1343 BMS_a256_minBrickT 1;
BA_ "Confidence" SG_ 1343 BMS_a256_maxBrickT 1;
BA_ "Confidence" SG_ 1343 BMS_a256_minBrickV 1;
BA_ "Confidence" SG_ 1343 BMS_a256_maxBrickV 1;
BA_ "Confidence" SG_ 1343 BMS_a256_packSoe 1;
BA_ "Confidence" SG_ 1343 BMS_a256_SOC 1;
VAL_ 943 BB_sOutputRodQF 2 "Faulty" 1 "Normal" 0 "NotInit_orOff" ;
VAL_ 943 BB_sInputRodQF 2 "Faulty" 1 "Normal" 0 "NotInit_orOff" ;
VAL_ 943 BB_driverBrakeApply 1 "DRIVER_APPLYING_BRAKES" 0 "BRAKES_NOT_APPLIED" ;
VAL_ 943 BB_driverBrakeApplyQF 2 "Faulty" 1 "Normal" 0 "NotInit_orOff" ;
VAL_ 943 BB_boosterStatus 6 "ACTUATION" 5 "READY" 4 "ACTIVE_GOOD_CHECK" 3 "DIAGNOSTIC" 2 "FAILURE" 1 "INIT" 0 "OFF" ;
VAL_ 943 BB_warningLampRequest 2 "RED_BRAKE_LAMP_REQUEST" 1 "YELLOW_BRAKE_LAMP_REQUEST" 0 "NO_LAMP_REQUEST" ;
VAL_ 943 BB_brakeFluidLevel 3 "BRAKE_FLUID_LEVEL_INVALID" 2 "BRAKE_FLUID_LEVEL_NORMAL" 1 "BRAKE_FLUID_LEVEL_LOW" 0 "BRAKE_FLUID_LEVEL_UNKNOWN" ;
VAL_ 943 BB_internalState 7 "READY_TO_SHUTDOWN" 6 "POST_DRIVE_CHECK" 5 "TRANSITION_TO_IDLE" 4 "DIAGNOSTIC" 3 "EXTERNAL_BRAKE_REQUEST" 2 "LOCAL_BRAKE_REQUEST" 1 "PRE_DRIVE_CHECK" 0 "NO_MODE_ACTIVE" ;
VAL_ 943 BB_unfilteredFluidLevelLow 1 "LEVEL_LOW" 0 "LEVEL_NORMAL_OR_UNKNOWN_OR_INVALID" ;
VAL_ 1343 BMS_alertID 299 "a299_PowershareFailure" 291 "a291_SOC_Imbalance_By_Delta_Voltage_Over_Delta_SOC" 290 "d290_batteryPackTempSensorACircuitFailure" 289 "d289_batteryPackAOverTemperature" 288 "d288_batteryPackCellVoltageLow" 287 "d287_systemIsolationWarning" 286 "d286_dcLinkVoltageHigh" 285 "d285_packVoltageSensorACircuitFailure" 284 "d284_fastChargeNegContactorAStuckOpen" 283 "d283_fastChargeNegContactorAStuckClosed" 282 "d282_fastChargeNegContactorACircuitFailure" 281 "d281_fastChargePosContactorAStuckOpen" 280 "d280_fastChargePosContactorAStuckClosed" 279 "d279_fastChargePosContactorACircuitFailure" 278 "d278_packNegContactorAStuckClosed" 277 "d277_packNegContactorACircuitFailure" 276 "d276_packPosContactorAStuckClosed" 275 "d275_packPosContactorACircuitFailure" 274 "d274_packCurrentSensorACircuitFailure" 273 "d273_vcFrontCommsLost" 272 "d272_batteryPackSensorCommsLost" 271 "d271_batteryPackSensorFailure" 270 "d270_hvpCommsLost" 269 "d269_highVoltageFuseABlown" 268 "d268_hvpInvalidFirmwareConfig" 267 "d267_batteryPackCellVoltageSenseHarnessFailure" 266 "d266_energyReserveVoltageLow" 265 "d265_replaceBatteryPack" 264 "d264_invalidFirmwareConfig" 263 "d263_batterySystemCurrentHigh" 262 "d262_batteryPackLowStateOfCharge" 261 "d261_batteryPackCellVoltageHigh" 260 "d260_chargePortInterlockFailure" 259 "d259_highVoltageInterlockFailure" 258 "d258_externalIsolationFault" 257 "d257_internalIsolationFault" 256 "a256_SW_Low_Power_Warning" 255 "a255_EstimatedRangeReduced" 254 "a254_LdcsCacImbalance" 227 "a227_ExcessChargeCurrentInCharge" 221 "a221_PcsEmergencyShutdownRequested" 214 "a214_AcChargeAborted" 204 "a204_AcCpEmergencyShutdownRequested" 202 "a202_AcChargeFaulted" 201 "a201_SW_Brick_OV_During_Charge" 200 "a200_GridFollowFaulted" 199 "a199_GridFollowAborted" 198 "a198_SW_SOC_Abrupt_Change" 197 "a197_SW_High_SOC_OV" 196 "a196_SW_PackVoltageUnderThreshold" 195 "a195_SW_DeltaTempOverThreshold" 194 "a194_PowershareLimitViolation" 193 "a193_PowershareMaxBrickVoltageViolation" 192 "a192_PowershareExternalChargeRegulation" 191 "a191_PowershareMinVoltageViolation" 190 "a190_PowershareMaxVoltageViolation" 189 "a189_PowershareDischargeCurrentViolation" 188 "a188_PowershareChargeCurrentViolation" 187 "a187_RippleHeatingEmergencyShutdown" 186 "a186_RippleHeatingChargeFault" 185 "a185_LifeModel_CyclingDcrGrowth_Change" 184 "a184_LifeModel_CyclingLoss_Change" 183 "a183_LifeModel_StoDcrGrowth_Change" 182 "a182_LifeModel_NoCurrentLoss_Change" 181 "a181_SW_Shunt_Over_Temperature" 180 "a180_SW_ECU_reset_blocked" 179 "a179_HvpGpoRequestActive" 178 "a178_SW_Uncontrolled_Regen_PwrB" 177 "a177_SW_Energy_Buffer_Size" 176 "a176_SW_GracefulPowerOff" 175 "a175_Charge_Failure_External" 174 "a174_SW_Charge_Failure" 173 "a173_FullPackEnergyDegraded" 172 "a172_SW_Isolation_Failure_In_Drive_Warning" 171 "a171_SW_Stack_Voltage_Sense" 170 "a170_SW_Limp_Mode" 169 "a169_SW_FC_Pack_Weld" 168 "a168_SW_FC_Full_Weld" 167 "a167_SW_FC_Partial_Weld" 166 "a166_SW_Pack_Full_Weld" 165 "a165_SW_Pack_Partial_Weld" 164 "a164_SW_Uncontrolled_Regen" 163 "a163_GridFormAborted" 162 "a162_SW_No_Power_For_Support" 161 "a161_SW_BMB_Vref_warning" 160 "a160_SW_FC_Ctr_Clean_Failed" 159 "a159_SW_HVP_ECU_Error" 158 "a158_SW_HVP_HVI_Comms" 157 "a157_SW_Hist_Update_Missed" 156 "a156_SW_BMB_Vref_bad" 155 "a155_SW_Weak_short_impedence" 154 "a154_SW_Brick_OV_Warning_Stop_Charge" 153 "a153_GridFormFaulted" 152 "a152_Isolation_In_Dc_Charge" 151 "a151_SW_external_isolation" 150 "a150_SW_Missing_Part_Number" 149 "a149_SW_Missing_Config_Block" 148 "a148_SW_Unsupported_BMB_ASIC_Type" 147 "a147_SW_SOC_High_Ah_Error" 146 "a146_SW_Brick_Overdischarged" 145 "a145_SW_SOC_Change" 144 "a144_Hvp_Config_Mismatch" 143 "a143_SW_CAC_Change" 142 "a142_SW_Isolation_Degradation" 141 "a141_SW_BMB_Status_Warning" 140 "a140_HW_BMB_Status_Fault" 139 "a139_SW_DC_Link_V_Irrational" 138 "a138_SW_Brick_OV_Warning" 137 "a137_SW_Brick_UV_Warning" 136 "a136_SW_Module_OT_Warning" 135 "a135_HW_BMB_Diagnostics_Failure" 134 "a134_SW_Delayed_Ctr_Off" 133 "a133_IO_CAN_Bus_Off" 132 "a132_HW_BMB_OTP_Uncorrctbl" 131 "a131_Bleed_FET_Failure" 130 "a130_IO_CAN_Error" 129 "a129_SW_VSH_Failure" 128 "a128_SW_shunt_MIA" 127 "a127_SW_shunt_SNA" 126 "a126_SW_Thermistor_Failure" 124 "a124_Battery_Coolant_Flood" 123 "a123_SW_Internal_Isolation" 122 "a122_SW_BMS_Therm_Irrational" 121 "a121_SW_NVRAM_Config_Error" 120 "a120_SW_Delta_SOC_User_Warning" 119 "a119_Fast_Open_Vsh_Detected" 118 "a118_SW_Delta_SOC_Weak_Short_Warning" 117 "a117_SW_Delta_SOC_Weak_Short" 115 "a115_Energy_Rubberbanding_Reset" 112 "a112_LifeModel_Discontinuity" 111 "a111_LifeModel_Spread_Change" 110 "a110_LifeModel_AvgOffset_Change" 109 "a109_HW_BMB_Mute_Status_Mismatch" 108 "a108_SW_BMB_Device_OT" 107 "a107_SW_Stack_Voltage_MIA" 106 "a106_SW_All_Module_Tsense" 105 "a105_SW_One_Module_Tsense" 100 "a100_ThermalEventSuspected" 99 "a099_SW_BMB_Communication" 98 "a098_SW_BMB_Data_Integrity_Loss" 97 "a097_SW_BMB_Over_CAN_Communication" 95 "a095_SW_UI_MIA" 94 "a094_SW_Drive_Inverter_MIA" 92 "a092_SW_ChargePort_Mia_On_Hvs" 91 "a091_SW_ChargePort_MIA" 90 "a090_SW_Gateway_MIA" 89 "a089_SW_VcFront_MIA" 88 "a088_SW_VcFront_MIA_InDrive" 87 "a087_SW_Feim_Test_Blocked" 86 "a086_SW_FC_Contactor_Mismatch" 85 "a085_SW_Pack_Contactor_Mismatch" 84 "a084_SW_Sleep_Wake_Aborted" 83 "a083_SW_Ctr_Close_Failure" 82 "a082_SW_Ctr_Force_Open" 81 "a081_SW_Ctr_Close_Blocked" 80 "a080_SW_Pack_Ctr_Impedance" 79 "a079_Max_Charge_Level_Exceeded" 78 "a078_Rapid_Dch_While_Charging" 77 "a077_SW_Charger_Regulation" 76 "a076_SW_Dch_While_Charging" 75 "a075_SW_Chg_Disable_Failure" 74 "a074_Max_Charge_Level_Reduced" 73 "a073_Unexpected_Loss_Of_Lv" 72 "a072_Module_Brick_Split" 71 "a071_SW_SM_TransCon_Not_Met" 70 "a070_BrickV_Imbalance_Limiting" 69 "a069_SW_Low_Power" 68 "a068_CAC_Imbalance_Limp" 67 "a067_CAC_Imbalance_Limiting" 66 "a066_SOC_Imbalance_Warning" 65 "a065_SW_CAC_Imbalance" 64 "a064_SW_SOC_Imbalance" 63 "a063_SW_ChargePort_Fault" 62 "a062_SW_BrickV_Imbalance" 61 "a061_SW_BrickV_Change" 60 "a060_SW_Leakage_Test_Failure" 59 "a059_SW_Pack_Voltage_Sensing" 58 "a058_SW_Bandolier_Model_Reset" 57 "a057_SW_Bandolier_Model_Warning" 56 "a056_SW_Standby_Supply_Fault" 55 "a055_SW_HvChain_Model_Fault" 54 "a054_SW_Ver_Supply_Fault" 52 "a052_SW_PCS_MIA" 51 "a051_SW_HVC_Vref_Bad" 50 "a050_SW_Brick_Voltage_MIA" 49 "a049_SW_Thermal_Event" 48 "a048_SW_Watch_Dog_Warning" 47 "a047_SW_Task_Stack_Overflow" 46 "a046_SW_Task_Stack_Usage" 45 "a045_SW_Exception" 44 "a044_SW_Assertion" 43 "a043_SW_Watch_Dog_Reset" 42 "a042_SW_MPU_Error" 41 "a041_SW_Destructive_Reset_Source" 40 "a040_SW_Watch_Dog_HW_Triggered" 39 "a039_SW_DC_Link_Over_Voltage" 37 "a037_SW_Flood_Port_Open" 36 "a036_SW_HvpHvilFault" 35 "a035_SW_Isolation" 34 "a034_SW_Passive_Isolation" 33 "a033_VoltageDeviation" 32 "a032_VoltageLoss" 31 "a031_AlertsSetDuringSleep" 30 "a030_Impedance_Deviation" 29 "a029_dSoc_Limiting" 28 "a028_ShuntAsicCurrentOffsetDeviation" 27 "a027_SW_Repeated_Isolation_Failure_In_Drive" 26 "a026_SW_HFCurrent_Anomaly" 25 "a025_SW_PwrBalance_Anomaly" 24 "a024_SW_Islanded_Brick" 23 "a023_SW_Stack_OV" 22 "a022_SW_Over_Current" 21 "a021_SW_Dr_Limits_Regulation" 20 "a020_SW_Brick_Instability" 19 "a019_SW_Module_OT" 18 "a018_SW_Brick_UV" 17 "a017_SW_Brick_OV" 16 "a016_Pack_Module_Id_Mismatch" 4 "a004_Cal_Vs_Serial_Birth_Date_Mismatch" 3 "a003_SW_Pack_Birth_Date_Missing" 2 "a002_Pack_Performance_Config_Mismatch" 1 "a001_Pack_Config_Mismatch" 0 "ALERT_DO_NOT_USE_ZERO" ;
VAL_ 1343 BMS_alertSet 1 "SET" 0 "CLEARED" ;
VAL_ 1343 BMS_a001_gatewayPackEnergy 2 "MR" 1 "LR" 0 "SR" ;
VAL_ 1343 BMS_a001_expectedPackEnergy 2 "MR" 1 "LR" 0 "SR" ;
VAL_ 1343 BMS_a002_gatewayPackPerformanceD 5 "PACK_POWER_DEVIATION_2" 4 "PACK_MASS_DEVIATION_2" 3 "PACK_STRUCTURAL_DEVIATION_1" 2 "PACK_POWER_DEVIATION_1" 1 "PACK_MASS_DEVIATION_1" 0 "NO_DEVIATION" ;
VAL_ 1343 BMS_a002_expectedPackPerformance 5 "PACK_POWER_DEVIATION_2" 4 "PACK_MASS_DEVIATION_2" 3 "PACK_STRUCTURAL_DEVIATION_1" 2 "PACK_POWER_DEVIATION_1" 1 "PACK_MASS_DEVIATION_1" 0 "NO_DEVIATION" ;
VAL_ 1343 BMS_a035_mode 4 "VOLTAGE_SETTLING_MODE" 3 "FEIM_POSITIVE_MODE" 2 "FEIM_NEGATIVE_MODE" 1 "VEHICLE_ISOLATION_MODE" 0 "MODE_RESET" ;
VAL_ 1343 BMS_a039_packContactorState 9 "NEGATIVE_CLOSED" 8 "POSITIVE_CLOSED" 7 "WELDED" 6 "PARTIAL_WELD" 5 "CLOSED" 4 "OPENING" 3 "BLOCKED" 2 "CLOSING" 1 "OPEN" 0 "SNA" ;
VAL_ 1343 BMS_a039_state 10 "DIAG" 9 "SNA" 8 "TEST" 7 "WELD" 6 "FAULT" 5 "CLEAR_FAULT" 4 "FEIM" 3 "CHARGE" 2 "SUPPORT" 1 "DRIVE" 0 "STANDBY" ;
VAL_ 1343 BMS_a041_resetType 8 "SWT1_RES" 7 "SWT0_RES" 6 "SUF" 5 "FUNC_ESC" 4 "SSCM_SEC" 3 "SOFT_DEST" 2 "HSM_DEST" 1 "POR" 0 "NONE" ;
VAL_ 1343 BMS_a062_state 10 "DIAG" 9 "SNA" 8 "TEST" 7 "WELD" 6 "FAULT" 5 "CLEAR_FAULT" 4 "FEIM" 3 "CHARGE" 2 "SUPPORT" 1 "DRIVE" 0 "STANDBY" ;
VAL_ 1343 BMS_a070_state 10 "DIAG" 9 "SNA" 8 "TEST" 7 "WELD" 6 "FAULT" 5 "CLEAR_FAULT" 4 "FEIM" 3 "CHARGE" 2 "SUPPORT" 1 "DRIVE" 0 "STANDBY" ;
VAL_ 1343 BMS_a071_stateRequest 10 "DIAG" 9 "SNA" 8 "TEST" 7 "WELD" 6 "FAULT" 5 "CLEAR_FAULT" 4 "FEIM" 3 "CHARGE" 2 "SUPPORT" 1 "DRIVE" 0 "STANDBY" ;
VAL_ 1343 BMS_a071_state 10 "DIAG" 9 "SNA" 8 "TEST" 7 "WELD" 6 "FAULT" 5 "CLEAR_FAULT" 4 "FEIM" 3 "CHARGE" 2 "SUPPORT" 1 "DRIVE" 0 "STANDBY" ;
VAL_ 1343 BMS_a075_chargeType 1 "AC_CHARGE_SESSION" 0 "DC_CHARGE_SESSION" ;
VAL_ 1343 BMS_a077_chargeErrType 1 "OVERCHARGE" 0 "CURRENT_HIGH" ;
VAL_ 1343 BMS_a078_peakDchInChg -32768 "SNA" ;
VAL_ 1343 BMS_a081_stateRequest 10 "DIAG" 9 "SNA" 8 "TEST" 7 "WELD" 6 "FAULT" 5 "CLEAR_FAULT" 4 "FEIM" 3 "CHARGE" 2 "SUPPORT" 1 "DRIVE" 0 "STANDBY" ;
VAL_ 1343 BMS_a081_firstBlockingAlertId 299 "a299_PowershareFailure" 291 "a291_SOC_Imbalance_By_Delta_Voltage_Over_Delta_SOC" 290 "d290_batteryPackTempSensorACircuitFailure" 289 "d289_batteryPackAOverTemperature" 288 "d288_batteryPackCellVoltageLow" 287 "d287_systemIsolationWarning" 286 "d286_dcLinkVoltageHigh" 285 "d285_packVoltageSensorACircuitFailure" 284 "d284_fastChargeNegContactorAStuckOpen" 283 "d283_fastChargeNegContactorAStuckClosed" 282 "d282_fastChargeNegContactorACircuitFailure" 281 "d281_fastChargePosContactorAStuckOpen" 280 "d280_fastChargePosContactorAStuckClosed" 279 "d279_fastChargePosContactorACircuitFailure" 278 "d278_packNegContactorAStuckClosed" 277 "d277_packNegContactorACircuitFailure" 276 "d276_packPosContactorAStuckClosed" 275 "d275_packPosContactorACircuitFailure" 274 "d274_packCurrentSensorACircuitFailure" 273 "d273_vcFrontCommsLost" 272 "d272_batteryPackSensorCommsLost" 271 "d271_batteryPackSensorFailure" 270 "d270_hvpCommsLost" 269 "d269_highVoltageFuseABlown" 268 "d268_hvpInvalidFirmwareConfig" 267 "d267_batteryPackCellVoltageSenseHarnessFailure" 266 "d266_energyReserveVoltageLow" 265 "d265_replaceBatteryPack" 264 "d264_invalidFirmwareConfig" 263 "d263_batterySystemCurrentHigh" 262 "d262_batteryPackLowStateOfCharge" 261 "d261_batteryPackCellVoltageHigh" 260 "d260_chargePortInterlockFailure" 259 "d259_highVoltageInterlockFailure" 258 "d258_externalIsolationFault" 257 "d257_internalIsolationFault" 256 "a256_SW_Low_Power_Warning" 255 "a255_EstimatedRangeReduced" 254 "a254_LdcsCacImbalance" 227 "a227_ExcessChargeCurrentInCharge" 221 "a221_PcsEmergencyShutdownRequested" 214 "a214_AcChargeAborted" 204 "a204_AcCpEmergencyShutdownRequested" 202 "a202_AcChargeFaulted" 201 "a201_SW_Brick_OV_During_Charge" 200 "a200_GridFollowFaulted" 199 "a199_GridFollowAborted" 198 "a198_SW_SOC_Abrupt_Change" 197 "a197_SW_High_SOC_OV" 196 "a196_SW_PackVoltageUnderThreshold" 195 "a195_SW_DeltaTempOverThreshold" 194 "a194_PowershareLimitViolation" 193 "a193_PowershareMaxBrickVoltageViolation" 192 "a192_PowershareExternalChargeRegulation" 191 "a191_PowershareMinVoltageViolation" 190 "a190_PowershareMaxVoltageViolation" 189 "a189_PowershareDischargeCurrentViolation" 188 "a188_PowershareChargeCurrentViolation" 187 "a187_RippleHeatingEmergencyShutdown" 186 "a186_RippleHeatingChargeFault" 185 "a185_LifeModel_CyclingDcrGrowth_Change" 184 "a184_LifeModel_CyclingLoss_Change" 183 "a183_LifeModel_StoDcrGrowth_Change" 182 "a182_LifeModel_NoCurrentLoss_Change" 181 "a181_SW_Shunt_Over_Temperature" 180 "a180_SW_ECU_reset_blocked" 179 "a179_HvpGpoRequestActive" 178 "a178_SW_Uncontrolled_Regen_PwrB" 177 "a177_SW_Energy_Buffer_Size" 176 "a176_SW_GracefulPowerOff" 175 "a175_Charge_Failure_External" 174 "a174_SW_Charge_Failure" 173 "a173_FullPackEnergyDegraded" 172 "a172_SW_Isolation_Failure_In_Drive_Warning" 171 "a171_SW_Stack_Voltage_Sense" 170 "a170_SW_Limp_Mode" 169 "a169_SW_FC_Pack_Weld" 168 "a168_SW_FC_Full_Weld" 167 "a167_SW_FC_Partial_Weld" 166 "a166_SW_Pack_Full_Weld" 165 "a165_SW_Pack_Partial_Weld" 164 "a164_SW_Uncontrolled_Regen" 163 "a163_GridFormAborted" 162 "a162_SW_No_Power_For_Support" 161 "a161_SW_BMB_Vref_warning" 160 "a160_SW_FC_Ctr_Clean_Failed" 159 "a159_SW_HVP_ECU_Error" 158 "a158_SW_HVP_HVI_Comms" 157 "a157_SW_Hist_Update_Missed" 156 "a156_SW_BMB_Vref_bad" 155 "a155_SW_Weak_short_impedence" 154 "a154_SW_Brick_OV_Warning_Stop_Charge" 153 "a153_GridFormFaulted" 152 "a152_Isolation_In_Dc_Charge" 151 "a151_SW_external_isolation" 150 "a150_SW_Missing_Part_Number" 149 "a149_SW_Missing_Config_Block" 148 "a148_SW_Unsupported_BMB_ASIC_Type" 147 "a147_SW_SOC_High_Ah_Error" 146 "a146_SW_Brick_Overdischarged" 145 "a145_SW_SOC_Change" 144 "a144_Hvp_Config_Mismatch" 143 "a143_SW_CAC_Change" 142 "a142_SW_Isolation_Degradation" 141 "a141_SW_BMB_Status_Warning" 140 "a140_HW_BMB_Status_Fault" 139 "a139_SW_DC_Link_V_Irrational" 138 "a138_SW_Brick_OV_Warning" 137 "a137_SW_Brick_UV_Warning" 136 "a136_SW_Module_OT_Warning" 135 "a135_HW_BMB_Diagnostics_Failure" 134 "a134_SW_Delayed_Ctr_Off" 133 "a133_IO_CAN_Bus_Off" 132 "a132_HW_BMB_OTP_Uncorrctbl" 131 "a131_Bleed_FET_Failure" 130 "a130_IO_CAN_Error" 129 "a129_SW_VSH_Failure" 128 "a128_SW_shunt_MIA" 127 "a127_SW_shunt_SNA" 126 "a126_SW_Thermistor_Failure" 124 "a124_Battery_Coolant_Flood" 123 "a123_SW_Internal_Isolation" 122 "a122_SW_BMS_Therm_Irrational" 121 "a121_SW_NVRAM_Config_Error" 120 "a120_SW_Delta_SOC_User_Warning" 119 "a119_Fast_Open_Vsh_Detected" 118 "a118_SW_Delta_SOC_Weak_Short_Warning" 117 "a117_SW_Delta_SOC_Weak_Short" 115 "a115_Energy_Rubberbanding_Reset" 112 "a112_LifeModel_Discontinuity" 111 "a111_LifeModel_Spread_Change" 110 "a110_LifeModel_AvgOffset_Change" 109 "a109_HW_BMB_Mute_Status_Mismatch" 108 "a108_SW_BMB_Device_OT" 107 "a107_SW_Stack_Voltage_MIA" 106 "a106_SW_All_Module_Tsense" 105 "a105_SW_One_Module_Tsense" 100 "a100_ThermalEventSuspected" 99 "a099_SW_BMB_Communication" 98 "a098_SW_BMB_Data_Integrity_Loss" 97 "a097_SW_BMB_Over_CAN_Communication" 95 "a095_SW_UI_MIA" 94 "a094_SW_Drive_Inverter_MIA" 92 "a092_SW_ChargePort_Mia_On_Hvs" 91 "a091_SW_ChargePort_MIA" 90 "a090_SW_Gateway_MIA" 89 "a089_SW_VcFront_MIA" 88 "a088_SW_VcFront_MIA_InDrive" 87 "a087_SW_Feim_Test_Blocked" 86 "a086_SW_FC_Contactor_Mismatch" 85 "a085_SW_Pack_Contactor_Mismatch" 84 "a084_SW_Sleep_Wake_Aborted" 83 "a083_SW_Ctr_Close_Failure" 82 "a082_SW_Ctr_Force_Open" 81 "a081_SW_Ctr_Close_Blocked" 80 "a080_SW_Pack_Ctr_Impedance" 79 "a079_Max_Charge_Level_Exceeded" 78 "a078_Rapid_Dch_While_Charging" 77 "a077_SW_Charger_Regulation" 76 "a076_SW_Dch_While_Charging" 75 "a075_SW_Chg_Disable_Failure" 74 "a074_Max_Charge_Level_Reduced" 73 "a073_Unexpected_Loss_Of_Lv" 72 "a072_Module_Brick_Split" 71 "a071_SW_SM_TransCon_Not_Met" 70 "a070_BrickV_Imbalance_Limiting" 69 "a069_SW_Low_Power" 68 "a068_CAC_Imbalance_Limp" 67 "a067_CAC_Imbalance_Limiting" 66 "a066_SOC_Imbalance_Warning" 65 "a065_SW_CAC_Imbalance" 64 "a064_SW_SOC_Imbalance" 63 "a063_SW_ChargePort_Fault" 62 "a062_SW_BrickV_Imbalance" 61 "a061_SW_BrickV_Change" 60 "a060_SW_Leakage_Test_Failure" 59 "a059_SW_Pack_Voltage_Sensing" 58 "a058_SW_Bandolier_Model_Reset" 57 "a057_SW_Bandolier_Model_Warning" 56 "a056_SW_Standby_Supply_Fault" 55 "a055_SW_HvChain_Model_Fault" 54 "a054_SW_Ver_Supply_Fault" 52 "a052_SW_PCS_MIA" 51 "a051_SW_HVC_Vref_Bad" 50 "a050_SW_Brick_Voltage_MIA" 49 "a049_SW_Thermal_Event" 48 "a048_SW_Watch_Dog_Warning" 47 "a047_SW_Task_Stack_Overflow" 46 "a046_SW_Task_Stack_Usage" 45 "a045_SW_Exception" 44 "a044_SW_Assertion" 43 "a043_SW_Watch_Dog_Reset" 42 "a042_SW_MPU_Error" 41 "a041_SW_Destructive_Reset_Source" 40 "a040_SW_Watch_Dog_HW_Triggered" 39 "a039_SW_DC_Link_Over_Voltage" 37 "a037_SW_Flood_Port_Open" 36 "a036_SW_HvpHvilFault" 35 "a035_SW_Isolation" 34 "a034_SW_Passive_Isolation" 33 "a033_VoltageDeviation" 32 "a032_VoltageLoss" 31 "a031_AlertsSetDuringSleep" 30 "a030_Impedance_Deviation" 29 "a029_dSoc_Limiting" 28 "a028_ShuntAsicCurrentOffsetDeviation" 27 "a027_SW_Repeated_Isolation_Failure_In_Drive" 26 "a026_SW_HFCurrent_Anomaly" 25 "a025_SW_PwrBalance_Anomaly" 24 "a024_SW_Islanded_Brick" 23 "a023_SW_Stack_OV" 22 "a022_SW_Over_Current" 21 "a021_SW_Dr_Limits_Regulation" 20 "a020_SW_Brick_Instability" 19 "a019_SW_Module_OT" 18 "a018_SW_Brick_UV" 17 "a017_SW_Brick_OV" 16 "a016_Pack_Module_Id_Mismatch" 4 "a004_Cal_Vs_Serial_Birth_Date_Mismatch" 3 "a003_SW_Pack_Birth_Date_Missing" 2 "a002_Pack_Performance_Config_Mismatch" 1 "a001_Pack_Config_Mismatch" 0 "ALERT_DO_NOT_USE_ZERO" ;
VAL_ 1343 BMS_a081_secondBlockingAlertId 299 "a299_PowershareFailure" 291 "a291_SOC_Imbalance_By_Delta_Voltage_Over_Delta_SOC" 290 "d290_batteryPackTempSensorACircuitFailure" 289 "d289_batteryPackAOverTemperature" 288 "d288_batteryPackCellVoltageLow" 287 "d287_systemIsolationWarning" 286 "d286_dcLinkVoltageHigh" 285 "d285_packVoltageSensorACircuitFailure" 284 "d284_fastChargeNegContactorAStuckOpen" 283 "d283_fastChargeNegContactorAStuckClosed" 282 "d282_fastChargeNegContactorACircuitFailure" 281 "d281_fastChargePosContactorAStuckOpen" 280 "d280_fastChargePosContactorAStuckClosed" 279 "d279_fastChargePosContactorACircuitFailure" 278 "d278_packNegContactorAStuckClosed" 277 "d277_packNegContactorACircuitFailure" 276 "d276_packPosContactorAStuckClosed" 275 "d275_packPosContactorACircuitFailure" 274 "d274_packCurrentSensorACircuitFailure" 273 "d273_vcFrontCommsLost" 272 "d272_batteryPackSensorCommsLost" 271 "d271_batteryPackSensorFailure" 270 "d270_hvpCommsLost" 269 "d269_highVoltageFuseABlown" 268 "d268_hvpInvalidFirmwareConfig" 267 "d267_batteryPackCellVoltageSenseHarnessFailure" 266 "d266_energyReserveVoltageLow" 265 "d265_replaceBatteryPack" 264 "d264_invalidFirmwareConfig" 263 "d263_batterySystemCurrentHigh" 262 "d262_batteryPackLowStateOfCharge" 261 "d261_batteryPackCellVoltageHigh" 260 "d260_chargePortInterlockFailure" 259 "d259_highVoltageInterlockFailure" 258 "d258_externalIsolationFault" 257 "d257_internalIsolationFault" 256 "a256_SW_Low_Power_Warning" 255 "a255_EstimatedRangeReduced" 254 "a254_LdcsCacImbalance" 227 "a227_ExcessChargeCurrentInCharge" 221 "a221_PcsEmergencyShutdownRequested" 214 "a214_AcChargeAborted" 204 "a204_AcCpEmergencyShutdownRequested" 202 "a202_AcChargeFaulted" 201 "a201_SW_Brick_OV_During_Charge" 200 "a200_GridFollowFaulted" 199 "a199_GridFollowAborted" 198 "a198_SW_SOC_Abrupt_Change" 197 "a197_SW_High_SOC_OV" 196 "a196_SW_PackVoltageUnderThreshold" 195 "a195_SW_DeltaTempOverThreshold" 194 "a194_PowershareLimitViolation" 193 "a193_PowershareMaxBrickVoltageViolation" 192 "a192_PowershareExternalChargeRegulation" 191 "a191_PowershareMinVoltageViolation" 190 "a190_PowershareMaxVoltageViolation" 189 "a189_PowershareDischargeCurrentViolation" 188 "a188_PowershareChargeCurrentViolation" 187 "a187_RippleHeatingEmergencyShutdown" 186 "a186_RippleHeatingChargeFault" 185 "a185_LifeModel_CyclingDcrGrowth_Change" 184 "a184_LifeModel_CyclingLoss_Change" 183 "a183_LifeModel_StoDcrGrowth_Change" 182 "a182_LifeModel_NoCurrentLoss_Change" 181 "a181_SW_Shunt_Over_Temperature" 180 "a180_SW_ECU_reset_blocked" 179 "a179_HvpGpoRequestActive" 178 "a178_SW_Uncontrolled_Regen_PwrB" 177 "a177_SW_Energy_Buffer_Size" 176 "a176_SW_GracefulPowerOff" 175 "a175_Charge_Failure_External" 174 "a174_SW_Charge_Failure" 173 "a173_FullPackEnergyDegraded" 172 "a172_SW_Isolation_Failure_In_Drive_Warning" 171 "a171_SW_Stack_Voltage_Sense" 170 "a170_SW_Limp_Mode" 169 "a169_SW_FC_Pack_Weld" 168 "a168_SW_FC_Full_Weld" 167 "a167_SW_FC_Partial_Weld" 166 "a166_SW_Pack_Full_Weld" 165 "a165_SW_Pack_Partial_Weld" 164 "a164_SW_Uncontrolled_Regen" 163 "a163_GridFormAborted" 162 "a162_SW_No_Power_For_Support" 161 "a161_SW_BMB_Vref_warning" 160 "a160_SW_FC_Ctr_Clean_Failed" 159 "a159_SW_HVP_ECU_Error" 158 "a158_SW_HVP_HVI_Comms" 157 "a157_SW_Hist_Update_Missed" 156 "a156_SW_BMB_Vref_bad" 155 "a155_SW_Weak_short_impedence" 154 "a154_SW_Brick_OV_Warning_Stop_Charge" 153 "a153_GridFormFaulted" 152 "a152_Isolation_In_Dc_Charge" 151 "a151_SW_external_isolation" 150 "a150_SW_Missing_Part_Number" 149 "a149_SW_Missing_Config_Block" 148 "a148_SW_Unsupported_BMB_ASIC_Type" 147 "a147_SW_SOC_High_Ah_Error" 146 "a146_SW_Brick_Overdischarged" 145 "a145_SW_SOC_Change" 144 "a144_Hvp_Config_Mismatch" 143 "a143_SW_CAC_Change" 142 "a142_SW_Isolation_Degradation" 141 "a141_SW_BMB_Status_Warning" 140 "a140_HW_BMB_Status_Fault" 139 "a139_SW_DC_Link_V_Irrational" 138 "a138_SW_Brick_OV_Warning" 137 "a137_SW_Brick_UV_Warning" 136 "a136_SW_Module_OT_Warning" 135 "a135_HW_BMB_Diagnostics_Failure" 134 "a134_SW_Delayed_Ctr_Off" 133 "a133_IO_CAN_Bus_Off" 132 "a132_HW_BMB_OTP_Uncorrctbl" 131 "a131_Bleed_FET_Failure" 130 "a130_IO_CAN_Error" 129 "a129_SW_VSH_Failure" 128 "a128_SW_shunt_MIA" 127 "a127_SW_shunt_SNA" 126 "a126_SW_Thermistor_Failure" 124 "a124_Battery_Coolant_Flood" 123 "a123_SW_Internal_Isolation" 122 "a122_SW_BMS_Therm_Irrational" 121 "a121_SW_NVRAM_Config_Error" 120 "a120_SW_Delta_SOC_User_Warning" 119 "a119_Fast_Open_Vsh_Detected" 118 "a118_SW_Delta_SOC_Weak_Short_Warning" 117 "a117_SW_Delta_SOC_Weak_Short" 115 "a115_Energy_Rubberbanding_Reset" 112 "a112_LifeModel_Discontinuity" 111 "a111_LifeModel_Spread_Change" 110 "a110_LifeModel_AvgOffset_Change" 109 "a109_HW_BMB_Mute_Status_Mismatch" 108 "a108_SW_BMB_Device_OT" 107 "a107_SW_Stack_Voltage_MIA" 106 "a106_SW_All_Module_Tsense" 105 "a105_SW_One_Module_Tsense" 100 "a100_ThermalEventSuspected" 99 "a099_SW_BMB_Communication" 98 "a098_SW_BMB_Data_Integrity_Loss" 97 "a097_SW_BMB_Over_CAN_Communication" 95 "a095_SW_UI_MIA" 94 "a094_SW_Drive_Inverter_MIA" 92 "a092_SW_ChargePort_Mia_On_Hvs" 91 "a091_SW_ChargePort_MIA" 90 "a090_SW_Gateway_MIA" 89 "a089_SW_VcFront_MIA" 88 "a088_SW_VcFront_MIA_InDrive" 87 "a087_SW_Feim_Test_Blocked" 86 "a086_SW_FC_Contactor_Mismatch" 85 "a085_SW_Pack_Contactor_Mismatch" 84 "a084_SW_Sleep_Wake_Aborted" 83 "a083_SW_Ctr_Close_Failure" 82 "a082_SW_Ctr_Force_Open" 81 "a081_SW_Ctr_Close_Blocked" 80 "a080_SW_Pack_Ctr_Impedance" 79 "a079_Max_Charge_Level_Exceeded" 78 "a078_Rapid_Dch_While_Charging" 77 "a077_SW_Charger_Regulation" 76 "a076_SW_Dch_While_Charging" 75 "a075_SW_Chg_Disable_Failure" 74 "a074_Max_Charge_Level_Reduced" 73 "a073_Unexpected_Loss_Of_Lv" 72 "a072_Module_Brick_Split" 71 "a071_SW_SM_TransCon_Not_Met" 70 "a070_BrickV_Imbalance_Limiting" 69 "a069_SW_Low_Power" 68 "a068_CAC_Imbalance_Limp" 67 "a067_CAC_Imbalance_Limiting" 66 "a066_SOC_Imbalance_Warning" 65 "a065_SW_CAC_Imbalance" 64 "a064_SW_SOC_Imbalance" 63 "a063_SW_ChargePort_Fault" 62 "a062_SW_BrickV_Imbalance" 61 "a061_SW_BrickV_Change" 60 "a060_SW_Leakage_Test_Failure" 59 "a059_SW_Pack_Voltage_Sensing" 58 "a058_SW_Bandolier_Model_Reset" 57 "a057_SW_Bandolier_Model_Warning" 56 "a056_SW_Standby_Supply_Fault" 55 "a055_SW_HvChain_Model_Fault" 54 "a054_SW_Ver_Supply_Fault" 52 "a052_SW_PCS_MIA" 51 "a051_SW_HVC_Vref_Bad" 50 "a050_SW_Brick_Voltage_MIA" 49 "a049_SW_Thermal_Event" 48 "a048_SW_Watch_Dog_Warning" 47 "a047_SW_Task_Stack_Overflow" 46 "a046_SW_Task_Stack_Usage" 45 "a045_SW_Exception" 44 "a044_SW_Assertion" 43 "a043_SW_Watch_Dog_Reset" 42 "a042_SW_MPU_Error" 41 "a041_SW_Destructive_Reset_Source" 40 "a040_SW_Watch_Dog_HW_Triggered" 39 "a039_SW_DC_Link_Over_Voltage" 37 "a037_SW_Flood_Port_Open" 36 "a036_SW_HvpHvilFault" 35 "a035_SW_Isolation" 34 "a034_SW_Passive_Isolation" 33 "a033_VoltageDeviation" 32 "a032_VoltageLoss" 31 "a031_AlertsSetDuringSleep" 30 "a030_Impedance_Deviation" 29 "a029_dSoc_Limiting" 28 "a028_ShuntAsicCurrentOffsetDeviation" 27 "a027_SW_Repeated_Isolation_Failure_In_Drive" 26 "a026_SW_HFCurrent_Anomaly" 25 "a025_SW_PwrBalance_Anomaly" 24 "a024_SW_Islanded_Brick" 23 "a023_SW_Stack_OV" 22 "a022_SW_Over_Current" 21 "a021_SW_Dr_Limits_Regulation" 20 "a020_SW_Brick_Instability" 19 "a019_SW_Module_OT" 18 "a018_SW_Brick_UV" 17 "a017_SW_Brick_OV" 16 "a016_Pack_Module_Id_Mismatch" 4 "a004_Cal_Vs_Serial_Birth_Date_Mismatch" 3 "a003_SW_Pack_Birth_Date_Missing" 2 "a002_Pack_Performance_Config_Mismatch" 1 "a001_Pack_Config_Mismatch" 0 "ALERT_DO_NOT_USE_ZERO" ;
VAL_ 1343 BMS_a081_thirdBlockingAlertId 299 "a299_PowershareFailure" 291 "a291_SOC_Imbalance_By_Delta_Voltage_Over_Delta_SOC" 290 "d290_batteryPackTempSensorACircuitFailure" 289 "d289_batteryPackAOverTemperature" 288 "d288_batteryPackCellVoltageLow" 287 "d287_systemIsolationWarning" 286 "d286_dcLinkVoltageHigh" 285 "d285_packVoltageSensorACircuitFailure" 284 "d284_fastChargeNegContactorAStuckOpen" 283 "d283_fastChargeNegContactorAStuckClosed" 282 "d282_fastChargeNegContactorACircuitFailure" 281 "d281_fastChargePosContactorAStuckOpen" 280 "d280_fastChargePosContactorAStuckClosed" 279 "d279_fastChargePosContactorACircuitFailure" 278 "d278_packNegContactorAStuckClosed" 277 "d277_packNegContactorACircuitFailure" 276 "d276_packPosContactorAStuckClosed" 275 "d275_packPosContactorACircuitFailure" 274 "d274_packCurrentSensorACircuitFailure" 273 "d273_vcFrontCommsLost" 272 "d272_batteryPackSensorCommsLost" 271 "d271_batteryPackSensorFailure" 270 "d270_hvpCommsLost" 269 "d269_highVoltageFuseABlown" 268 "d268_hvpInvalidFirmwareConfig" 267 "d267_batteryPackCellVoltageSenseHarnessFailure" 266 "d266_energyReserveVoltageLow" 265 "d265_replaceBatteryPack" 264 "d264_invalidFirmwareConfig" 263 "d263_batterySystemCurrentHigh" 262 "d262_batteryPackLowStateOfCharge" 261 "d261_batteryPackCellVoltageHigh" 260 "d260_chargePortInterlockFailure" 259 "d259_highVoltageInterlockFailure" 258 "d258_externalIsolationFault" 257 "d257_internalIsolationFault" 256 "a256_SW_Low_Power_Warning" 255 "a255_EstimatedRangeReduced" 254 "a254_LdcsCacImbalance" 227 "a227_ExcessChargeCurrentInCharge" 221 "a221_PcsEmergencyShutdownRequested" 214 "a214_AcChargeAborted" 204 "a204_AcCpEmergencyShutdownRequested" 202 "a202_AcChargeFaulted" 201 "a201_SW_Brick_OV_During_Charge" 200 "a200_GridFollowFaulted" 199 "a199_GridFollowAborted" 198 "a198_SW_SOC_Abrupt_Change" 197 "a197_SW_High_SOC_OV" 196 "a196_SW_PackVoltageUnderThreshold" 195 "a195_SW_DeltaTempOverThreshold" 194 "a194_PowershareLimitViolation" 193 "a193_PowershareMaxBrickVoltageViolation" 192 "a192_PowershareExternalChargeRegulation" 191 "a191_PowershareMinVoltageViolation" 190 "a190_PowershareMaxVoltageViolation" 189 "a189_PowershareDischargeCurrentViolation" 188 "a188_PowershareChargeCurrentViolation" 187 "a187_RippleHeatingEmergencyShutdown" 186 "a186_RippleHeatingChargeFault" 185 "a185_LifeModel_CyclingDcrGrowth_Change" 184 "a184_LifeModel_CyclingLoss_Change" 183 "a183_LifeModel_StoDcrGrowth_Change" 182 "a182_LifeModel_NoCurrentLoss_Change" 181 "a181_SW_Shunt_Over_Temperature" 180 "a180_SW_ECU_reset_blocked" 179 "a179_HvpGpoRequestActive" 178 "a178_SW_Uncontrolled_Regen_PwrB" 177 "a177_SW_Energy_Buffer_Size" 176 "a176_SW_GracefulPowerOff" 175 "a175_Charge_Failure_External" 174 "a174_SW_Charge_Failure" 173 "a173_FullPackEnergyDegraded" 172 "a172_SW_Isolation_Failure_In_Drive_Warning" 171 "a171_SW_Stack_Voltage_Sense" 170 "a170_SW_Limp_Mode" 169 "a169_SW_FC_Pack_Weld" 168 "a168_SW_FC_Full_Weld" 167 "a167_SW_FC_Partial_Weld" 166 "a166_SW_Pack_Full_Weld" 165 "a165_SW_Pack_Partial_Weld" 164 "a164_SW_Uncontrolled_Regen" 163 "a163_GridFormAborted" 162 "a162_SW_No_Power_For_Support" 161 "a161_SW_BMB_Vref_warning" 160 "a160_SW_FC_Ctr_Clean_Failed" 159 "a159_SW_HVP_ECU_Error" 158 "a158_SW_HVP_HVI_Comms" 157 "a157_SW_Hist_Update_Missed" 156 "a156_SW_BMB_Vref_bad" 155 "a155_SW_Weak_short_impedence" 154 "a154_SW_Brick_OV_Warning_Stop_Charge" 153 "a153_GridFormFaulted" 152 "a152_Isolation_In_Dc_Charge" 151 "a151_SW_external_isolation" 150 "a150_SW_Missing_Part_Number" 149 "a149_SW_Missing_Config_Block" 148 "a148_SW_Unsupported_BMB_ASIC_Type" 147 "a147_SW_SOC_High_Ah_Error" 146 "a146_SW_Brick_Overdischarged" 145 "a145_SW_SOC_Change" 144 "a144_Hvp_Config_Mismatch" 143 "a143_SW_CAC_Change" 142 "a142_SW_Isolation_Degradation" 141 "a141_SW_BMB_Status_Warning" 140 "a140_HW_BMB_Status_Fault" 139 "a139_SW_DC_Link_V_Irrational" 138 "a138_SW_Brick_OV_Warning" 137 "a137_SW_Brick_UV_Warning" 136 "a136_SW_Module_OT_Warning" 135 "a135_HW_BMB_Diagnostics_Failure" 134 "a134_SW_Delayed_Ctr_Off" 133 "a133_IO_CAN_Bus_Off" 132 "a132_HW_BMB_OTP_Uncorrctbl" 131 "a131_Bleed_FET_Failure" 130 "a130_IO_CAN_Error" 129 "a129_SW_VSH_Failure" 128 "a128_SW_shunt_MIA" 127 "a127_SW_shunt_SNA" 126 "a126_SW_Thermistor_Failure" 124 "a124_Battery_Coolant_Flood" 123 "a123_SW_Internal_Isolation" 122 "a122_SW_BMS_Therm_Irrational" 121 "a121_SW_NVRAM_Config_Error" 120 "a120_SW_Delta_SOC_User_Warning" 119 "a119_Fast_Open_Vsh_Detected" 118 "a118_SW_Delta_SOC_Weak_Short_Warning" 117 "a117_SW_Delta_SOC_Weak_Short" 115 "a115_Energy_Rubberbanding_Reset" 112 "a112_LifeModel_Discontinuity" 111 "a111_LifeModel_Spread_Change" 110 "a110_LifeModel_AvgOffset_Change" 109 "a109_HW_BMB_Mute_Status_Mismatch" 108 "a108_SW_BMB_Device_OT" 107 "a107_SW_Stack_Voltage_MIA" 106 "a106_SW_All_Module_Tsense" 105 "a105_SW_One_Module_Tsense" 100 "a100_ThermalEventSuspected" 99 "a099_SW_BMB_Communication" 98 "a098_SW_BMB_Data_Integrity_Loss" 97 "a097_SW_BMB_Over_CAN_Communication" 95 "a095_SW_UI_MIA" 94 "a094_SW_Drive_Inverter_MIA" 92 "a092_SW_ChargePort_Mia_On_Hvs" 91 "a091_SW_ChargePort_MIA" 90 "a090_SW_Gateway_MIA" 89 "a089_SW_VcFront_MIA" 88 "a088_SW_VcFront_MIA_InDrive" 87 "a087_SW_Feim_Test_Blocked" 86 "a086_SW_FC_Contactor_Mismatch" 85 "a085_SW_Pack_Contactor_Mismatch" 84 "a084_SW_Sleep_Wake_Aborted" 83 "a083_SW_Ctr_Close_Failure" 82 "a082_SW_Ctr_Force_Open" 81 "a081_SW_Ctr_Close_Blocked" 80 "a080_SW_Pack_Ctr_Impedance" 79 "a079_Max_Charge_Level_Exceeded" 78 "a078_Rapid_Dch_While_Charging" 77 "a077_SW_Charger_Regulation" 76 "a076_SW_Dch_While_Charging" 75 "a075_SW_Chg_Disable_Failure" 74 "a074_Max_Charge_Level_Reduced" 73 "a073_Unexpected_Loss_Of_Lv" 72 "a072_Module_Brick_Split" 71 "a071_SW_SM_TransCon_Not_Met" 70 "a070_BrickV_Imbalance_Limiting" 69 "a069_SW_Low_Power" 68 "a068_CAC_Imbalance_Limp" 67 "a067_CAC_Imbalance_Limiting" 66 "a066_SOC_Imbalance_Warning" 65 "a065_SW_CAC_Imbalance" 64 "a064_SW_SOC_Imbalance" 63 "a063_SW_ChargePort_Fault" 62 "a062_SW_BrickV_Imbalance" 61 "a061_SW_BrickV_Change" 60 "a060_SW_Leakage_Test_Failure" 59 "a059_SW_Pack_Voltage_Sensing" 58 "a058_SW_Bandolier_Model_Reset" 57 "a057_SW_Bandolier_Model_Warning" 56 "a056_SW_Standby_Supply_Fault" 55 "a055_SW_HvChain_Model_Fault" 54 "a054_SW_Ver_Supply_Fault" 52 "a052_SW_PCS_MIA" 51 "a051_SW_HVC_Vref_Bad" 50 "a050_SW_Brick_Voltage_MIA" 49 "a049_SW_Thermal_Event" 48 "a048_SW_Watch_Dog_Warning" 47 "a047_SW_Task_Stack_Overflow" 46 "a046_SW_Task_Stack_Usage" 45 "a045_SW_Exception" 44 "a044_SW_Assertion" 43 "a043_SW_Watch_Dog_Reset" 42 "a042_SW_MPU_Error" 41 "a041_SW_Destructive_Reset_Source" 40 "a040_SW_Watch_Dog_HW_Triggered" 39 "a039_SW_DC_Link_Over_Voltage" 37 "a037_SW_Flood_Port_Open" 36 "a036_SW_HvpHvilFault" 35 "a035_SW_Isolation" 34 "a034_SW_Passive_Isolation" 33 "a033_VoltageDeviation" 32 "a032_VoltageLoss" 31 "a031_AlertsSetDuringSleep" 30 "a030_Impedance_Deviation" 29 "a029_dSoc_Limiting" 28 "a028_ShuntAsicCurrentOffsetDeviation" 27 "a027_SW_Repeated_Isolation_Failure_In_Drive" 26 "a026_SW_HFCurrent_Anomaly" 25 "a025_SW_PwrBalance_Anomaly" 24 "a024_SW_Islanded_Brick" 23 "a023_SW_Stack_OV" 22 "a022_SW_Over_Current" 21 "a021_SW_Dr_Limits_Regulation" 20 "a020_SW_Brick_Instability" 19 "a019_SW_Module_OT" 18 "a018_SW_Brick_UV" 17 "a017_SW_Brick_OV" 16 "a016_Pack_Module_Id_Mismatch" 4 "a004_Cal_Vs_Serial_Birth_Date_Mismatch" 3 "a003_SW_Pack_Birth_Date_Missing" 2 "a002_Pack_Performance_Config_Mismatch" 1 "a001_Pack_Config_Mismatch" 0 "ALERT_DO_NOT_USE_ZERO" ;
VAL_ 1343 BMS_a081_fourthBlockingAlertId 299 "a299_PowershareFailure" 291 "a291_SOC_Imbalance_By_Delta_Voltage_Over_Delta_SOC" 290 "d290_batteryPackTempSensorACircuitFailure" 289 "d289_batteryPackAOverTemperature" 288 "d288_batteryPackCellVoltageLow" 287 "d287_systemIsolationWarning" 286 "d286_dcLinkVoltageHigh" 285 "d285_packVoltageSensorACircuitFailure" 284 "d284_fastChargeNegContactorAStuckOpen" 283 "d283_fastChargeNegContactorAStuckClosed" 282 "d282_fastChargeNegContactorACircuitFailure" 281 "d281_fastChargePosContactorAStuckOpen" 280 "d280_fastChargePosContactorAStuckClosed" 279 "d279_fastChargePosContactorACircuitFailure" 278 "d278_packNegContactorAStuckClosed" 277 "d277_packNegContactorACircuitFailure" 276 "d276_packPosContactorAStuckClosed" 275 "d275_packPosContactorACircuitFailure" 274 "d274_packCurrentSensorACircuitFailure" 273 "d273_vcFrontCommsLost" 272 "d272_batteryPackSensorCommsLost" 271 "d271_batteryPackSensorFailure" 270 "d270_hvpCommsLost" 269 "d269_highVoltageFuseABlown" 268 "d268_hvpInvalidFirmwareConfig" 267 "d267_batteryPackCellVoltageSenseHarnessFailure" 266 "d266_energyReserveVoltageLow" 265 "d265_replaceBatteryPack" 264 "d264_invalidFirmwareConfig" 263 "d263_batterySystemCurrentHigh" 262 "d262_batteryPackLowStateOfCharge" 261 "d261_batteryPackCellVoltageHigh" 260 "d260_chargePortInterlockFailure" 259 "d259_highVoltageInterlockFailure" 258 "d258_externalIsolationFault" 257 "d257_internalIsolationFault" 256 "a256_SW_Low_Power_Warning" 255 "a255_EstimatedRangeReduced" 254 "a254_LdcsCacImbalance" 227 "a227_ExcessChargeCurrentInCharge" 221 "a221_PcsEmergencyShutdownRequested" 214 "a214_AcChargeAborted" 204 "a204_AcCpEmergencyShutdownRequested" 202 "a202_AcChargeFaulted" 201 "a201_SW_Brick_OV_During_Charge" 200 "a200_GridFollowFaulted" 199 "a199_GridFollowAborted" 198 "a198_SW_SOC_Abrupt_Change" 197 "a197_SW_High_SOC_OV" 196 "a196_SW_PackVoltageUnderThreshold" 195 "a195_SW_DeltaTempOverThreshold" 194 "a194_PowershareLimitViolation" 193 "a193_PowershareMaxBrickVoltageViolation" 192 "a192_PowershareExternalChargeRegulation" 191 "a191_PowershareMinVoltageViolation" 190 "a190_PowershareMaxVoltageViolation" 189 "a189_PowershareDischargeCurrentViolation" 188 "a188_PowershareChargeCurrentViolation" 187 "a187_RippleHeatingEmergencyShutdown" 186 "a186_RippleHeatingChargeFault" 185 "a185_LifeModel_CyclingDcrGrowth_Change" 184 "a184_LifeModel_CyclingLoss_Change" 183 "a183_LifeModel_StoDcrGrowth_Change" 182 "a182_LifeModel_NoCurrentLoss_Change" 181 "a181_SW_Shunt_Over_Temperature" 180 "a180_SW_ECU_reset_blocked" 179 "a179_HvpGpoRequestActive" 178 "a178_SW_Uncontrolled_Regen_PwrB" 177 "a177_SW_Energy_Buffer_Size" 176 "a176_SW_GracefulPowerOff" 175 "a175_Charge_Failure_External" 174 "a174_SW_Charge_Failure" 173 "a173_FullPackEnergyDegraded" 172 "a172_SW_Isolation_Failure_In_Drive_Warning" 171 "a171_SW_Stack_Voltage_Sense" 170 "a170_SW_Limp_Mode" 169 "a169_SW_FC_Pack_Weld" 168 "a168_SW_FC_Full_Weld" 167 "a167_SW_FC_Partial_Weld" 166 "a166_SW_Pack_Full_Weld" 165 "a165_SW_Pack_Partial_Weld" 164 "a164_SW_Uncontrolled_Regen" 163 "a163_GridFormAborted" 162 "a162_SW_No_Power_For_Support" 161 "a161_SW_BMB_Vref_warning" 160 "a160_SW_FC_Ctr_Clean_Failed" 159 "a159_SW_HVP_ECU_Error" 158 "a158_SW_HVP_HVI_Comms" 157 "a157_SW_Hist_Update_Missed" 156 "a156_SW_BMB_Vref_bad" 155 "a155_SW_Weak_short_impedence" 154 "a154_SW_Brick_OV_Warning_Stop_Charge" 153 "a153_GridFormFaulted" 152 "a152_Isolation_In_Dc_Charge" 151 "a151_SW_external_isolation" 150 "a150_SW_Missing_Part_Number" 149 "a149_SW_Missing_Config_Block" 148 "a148_SW_Unsupported_BMB_ASIC_Type" 147 "a147_SW_SOC_High_Ah_Error" 146 "a146_SW_Brick_Overdischarged" 145 "a145_SW_SOC_Change" 144 "a144_Hvp_Config_Mismatch" 143 "a143_SW_CAC_Change" 142 "a142_SW_Isolation_Degradation" 141 "a141_SW_BMB_Status_Warning" 140 "a140_HW_BMB_Status_Fault" 139 "a139_SW_DC_Link_V_Irrational" 138 "a138_SW_Brick_OV_Warning" 137 "a137_SW_Brick_UV_Warning" 136 "a136_SW_Module_OT_Warning" 135 "a135_HW_BMB_Diagnostics_Failure" 134 "a134_SW_Delayed_Ctr_Off" 133 "a133_IO_CAN_Bus_Off" 132 "a132_HW_BMB_OTP_Uncorrctbl" 131 "a131_Bleed_FET_Failure" 130 "a130_IO_CAN_Error" 129 "a129_SW_VSH_Failure" 128 "a128_SW_shunt_MIA" 127 "a127_SW_shunt_SNA" 126 "a126_SW_Thermistor_Failure" 124 "a124_Battery_Coolant_Flood" 123 "a123_SW_Internal_Isolation" 122 "a122_SW_BMS_Therm_Irrational" 121 "a121_SW_NVRAM_Config_Error" 120 "a120_SW_Delta_SOC_User_Warning" 119 "a119_Fast_Open_Vsh_Detected" 118 "a118_SW_Delta_SOC_Weak_Short_Warning" 117 "a117_SW_Delta_SOC_Weak_Short" 115 "a115_Energy_Rubberbanding_Reset" 112 "a112_LifeModel_Discontinuity" 111 "a111_LifeModel_Spread_Change" 110 "a110_LifeModel_AvgOffset_Change" 109 "a109_HW_BMB_Mute_Status_Mismatch" 108 "a108_SW_BMB_Device_OT" 107 "a107_SW_Stack_Voltage_MIA" 106 "a106_SW_All_Module_Tsense" 105 "a105_SW_One_Module_Tsense" 100 "a100_ThermalEventSuspected" 99 "a099_SW_BMB_Communication" 98 "a098_SW_BMB_Data_Integrity_Loss" 97 "a097_SW_BMB_Over_CAN_Communication" 95 "a095_SW_UI_MIA" 94 "a094_SW_Drive_Inverter_MIA" 92 "a092_SW_ChargePort_Mia_On_Hvs" 91 "a091_SW_ChargePort_MIA" 90 "a090_SW_Gateway_MIA" 89 "a089_SW_VcFront_MIA" 88 "a088_SW_VcFront_MIA_InDrive" 87 "a087_SW_Feim_Test_Blocked" 86 "a086_SW_FC_Contactor_Mismatch" 85 "a085_SW_Pack_Contactor_Mismatch" 84 "a084_SW_Sleep_Wake_Aborted" 83 "a083_SW_Ctr_Close_Failure" 82 "a082_SW_Ctr_Force_Open" 81 "a081_SW_Ctr_Close_Blocked" 80 "a080_SW_Pack_Ctr_Impedance" 79 "a079_Max_Charge_Level_Exceeded" 78 "a078_Rapid_Dch_While_Charging" 77 "a077_SW_Charger_Regulation" 76 "a076_SW_Dch_While_Charging" 75 "a075_SW_Chg_Disable_Failure" 74 "a074_Max_Charge_Level_Reduced" 73 "a073_Unexpected_Loss_Of_Lv" 72 "a072_Module_Brick_Split" 71 "a071_SW_SM_TransCon_Not_Met" 70 "a070_BrickV_Imbalance_Limiting" 69 "a069_SW_Low_Power" 68 "a068_CAC_Imbalance_Limp" 67 "a067_CAC_Imbalance_Limiting" 66 "a066_SOC_Imbalance_Warning" 65 "a065_SW_CAC_Imbalance" 64 "a064_SW_SOC_Imbalance" 63 "a063_SW_ChargePort_Fault" 62 "a062_SW_BrickV_Imbalance" 61 "a061_SW_BrickV_Change" 60 "a060_SW_Leakage_Test_Failure" 59 "a059_SW_Pack_Voltage_Sensing" 58 "a058_SW_Bandolier_Model_Reset" 57 "a057_SW_Bandolier_Model_Warning" 56 "a056_SW_Standby_Supply_Fault" 55 "a055_SW_HvChain_Model_Fault" 54 "a054_SW_Ver_Supply_Fault" 52 "a052_SW_PCS_MIA" 51 "a051_SW_HVC_Vref_Bad" 50 "a050_SW_Brick_Voltage_MIA" 49 "a049_SW_Thermal_Event" 48 "a048_SW_Watch_Dog_Warning" 47 "a047_SW_Task_Stack_Overflow" 46 "a046_SW_Task_Stack_Usage" 45 "a045_SW_Exception" 44 "a044_SW_Assertion" 43 "a043_SW_Watch_Dog_Reset" 42 "a042_SW_MPU_Error" 41 "a041_SW_Destructive_Reset_Source" 40 "a040_SW_Watch_Dog_HW_Triggered" 39 "a039_SW_DC_Link_Over_Voltage" 37 "a037_SW_Flood_Port_Open" 36 "a036_SW_HvpHvilFault" 35 "a035_SW_Isolation" 34 "a034_SW_Passive_Isolation" 33 "a033_VoltageDeviation" 32 "a032_VoltageLoss" 31 "a031_AlertsSetDuringSleep" 30 "a030_Impedance_Deviation" 29 "a029_dSoc_Limiting" 28 "a028_ShuntAsicCurrentOffsetDeviation" 27 "a027_SW_Repeated_Isolation_Failure_In_Drive" 26 "a026_SW_HFCurrent_Anomaly" 25 "a025_SW_PwrBalance_Anomaly" 24 "a024_SW_Islanded_Brick" 23 "a023_SW_Stack_OV" 22 "a022_SW_Over_Current" 21 "a021_SW_Dr_Limits_Regulation" 20 "a020_SW_Brick_Instability" 19 "a019_SW_Module_OT" 18 "a018_SW_Brick_UV" 17 "a017_SW_Brick_OV" 16 "a016_Pack_Module_Id_Mismatch" 4 "a004_Cal_Vs_Serial_Birth_Date_Mismatch" 3 "a003_SW_Pack_Birth_Date_Missing" 2 "a002_Pack_Performance_Config_Mismatch" 1 "a001_Pack_Config_Mismatch" 0 "ALERT_DO_NOT_USE_ZERO" ;
VAL_ 1343 BMS_a082_stateRequest 10 "DIAG" 9 "SNA" 8 "TEST" 7 "WELD" 6 "FAULT" 5 "CLEAR_FAULT" 4 "FEIM" 3 "CHARGE" 2 "SUPPORT" 1 "DRIVE" 0 "STANDBY" ;
VAL_ 1343 BMS_a082_firstAlertId 299 "a299_PowershareFailure" 291 "a291_SOC_Imbalance_By_Delta_Voltage_Over_Delta_SOC" 290 "d290_batteryPackTempSensorACircuitFailure" 289 "d289_batteryPackAOverTemperature" 288 "d288_batteryPackCellVoltageLow" 287 "d287_systemIsolationWarning" 286 "d286_dcLinkVoltageHigh" 285 "d285_packVoltageSensorACircuitFailure" 284 "d284_fastChargeNegContactorAStuckOpen" 283 "d283_fastChargeNegContactorAStuckClosed" 282 "d282_fastChargeNegContactorACircuitFailure" 281 "d281_fastChargePosContactorAStuckOpen" 280 "d280_fastChargePosContactorAStuckClosed" 279 "d279_fastChargePosContactorACircuitFailure" 278 "d278_packNegContactorAStuckClosed" 277 "d277_packNegContactorACircuitFailure" 276 "d276_packPosContactorAStuckClosed" 275 "d275_packPosContactorACircuitFailure" 274 "d274_packCurrentSensorACircuitFailure" 273 "d273_vcFrontCommsLost" 272 "d272_batteryPackSensorCommsLost" 271 "d271_batteryPackSensorFailure" 270 "d270_hvpCommsLost" 269 "d269_highVoltageFuseABlown" 268 "d268_hvpInvalidFirmwareConfig" 267 "d267_batteryPackCellVoltageSenseHarnessFailure" 266 "d266_energyReserveVoltageLow" 265 "d265_replaceBatteryPack" 264 "d264_invalidFirmwareConfig" 263 "d263_batterySystemCurrentHigh" 262 "d262_batteryPackLowStateOfCharge" 261 "d261_batteryPackCellVoltageHigh" 260 "d260_chargePortInterlockFailure" 259 "d259_highVoltageInterlockFailure" 258 "d258_externalIsolationFault" 257 "d257_internalIsolationFault" 256 "a256_SW_Low_Power_Warning" 255 "a255_EstimatedRangeReduced" 254 "a254_LdcsCacImbalance" 227 "a227_ExcessChargeCurrentInCharge" 221 "a221_PcsEmergencyShutdownRequested" 214 "a214_AcChargeAborted" 204 "a204_AcCpEmergencyShutdownRequested" 202 "a202_AcChargeFaulted" 201 "a201_SW_Brick_OV_During_Charge" 200 "a200_GridFollowFaulted" 199 "a199_GridFollowAborted" 198 "a198_SW_SOC_Abrupt_Change" 197 "a197_SW_High_SOC_OV" 196 "a196_SW_PackVoltageUnderThreshold" 195 "a195_SW_DeltaTempOverThreshold" 194 "a194_PowershareLimitViolation" 193 "a193_PowershareMaxBrickVoltageViolation" 192 "a192_PowershareExternalChargeRegulation" 191 "a191_PowershareMinVoltageViolation" 190 "a190_PowershareMaxVoltageViolation" 189 "a189_PowershareDischargeCurrentViolation" 188 "a188_PowershareChargeCurrentViolation" 187 "a187_RippleHeatingEmergencyShutdown" 186 "a186_RippleHeatingChargeFault" 185 "a185_LifeModel_CyclingDcrGrowth_Change" 184 "a184_LifeModel_CyclingLoss_Change" 183 "a183_LifeModel_StoDcrGrowth_Change" 182 "a182_LifeModel_NoCurrentLoss_Change" 181 "a181_SW_Shunt_Over_Temperature" 180 "a180_SW_ECU_reset_blocked" 179 "a179_HvpGpoRequestActive" 178 "a178_SW_Uncontrolled_Regen_PwrB" 177 "a177_SW_Energy_Buffer_Size" 176 "a176_SW_GracefulPowerOff" 175 "a175_Charge_Failure_External" 174 "a174_SW_Charge_Failure" 173 "a173_FullPackEnergyDegraded" 172 "a172_SW_Isolation_Failure_In_Drive_Warning" 171 "a171_SW_Stack_Voltage_Sense" 170 "a170_SW_Limp_Mode" 169 "a169_SW_FC_Pack_Weld" 168 "a168_SW_FC_Full_Weld" 167 "a167_SW_FC_Partial_Weld" 166 "a166_SW_Pack_Full_Weld" 165 "a165_SW_Pack_Partial_Weld" 164 "a164_SW_Uncontrolled_Regen" 163 "a163_GridFormAborted" 162 "a162_SW_No_Power_For_Support" 161 "a161_SW_BMB_Vref_warning" 160 "a160_SW_FC_Ctr_Clean_Failed" 159 "a159_SW_HVP_ECU_Error" 158 "a158_SW_HVP_HVI_Comms" 157 "a157_SW_Hist_Update_Missed" 156 "a156_SW_BMB_Vref_bad" 155 "a155_SW_Weak_short_impedence" 154 "a154_SW_Brick_OV_Warning_Stop_Charge" 153 "a153_GridFormFaulted" 152 "a152_Isolation_In_Dc_Charge" 151 "a151_SW_external_isolation" 150 "a150_SW_Missing_Part_Number" 149 "a149_SW_Missing_Config_Block" 148 "a148_SW_Unsupported_BMB_ASIC_Type" 147 "a147_SW_SOC_High_Ah_Error" 146 "a146_SW_Brick_Overdischarged" 145 "a145_SW_SOC_Change" 144 "a144_Hvp_Config_Mismatch" 143 "a143_SW_CAC_Change" 142 "a142_SW_Isolation_Degradation" 141 "a141_SW_BMB_Status_Warning" 140 "a140_HW_BMB_Status_Fault" 139 "a139_SW_DC_Link_V_Irrational" 138 "a138_SW_Brick_OV_Warning" 137 "a137_SW_Brick_UV_Warning" 136 "a136_SW_Module_OT_Warning" 135 "a135_HW_BMB_Diagnostics_Failure" 134 "a134_SW_Delayed_Ctr_Off" 133 "a133_IO_CAN_Bus_Off" 132 "a132_HW_BMB_OTP_Uncorrctbl" 131 "a131_Bleed_FET_Failure" 130 "a130_IO_CAN_Error" 129 "a129_SW_VSH_Failure" 128 "a128_SW_shunt_MIA" 127 "a127_SW_shunt_SNA" 126 "a126_SW_Thermistor_Failure" 124 "a124_Battery_Coolant_Flood" 123 "a123_SW_Internal_Isolation" 122 "a122_SW_BMS_Therm_Irrational" 121 "a121_SW_NVRAM_Config_Error" 120 "a120_SW_Delta_SOC_User_Warning" 119 "a119_Fast_Open_Vsh_Detected" 118 "a118_SW_Delta_SOC_Weak_Short_Warning" 117 "a117_SW_Delta_SOC_Weak_Short" 115 "a115_Energy_Rubberbanding_Reset" 112 "a112_LifeModel_Discontinuity" 111 "a111_LifeModel_Spread_Change" 110 "a110_LifeModel_AvgOffset_Change" 109 "a109_HW_BMB_Mute_Status_Mismatch" 108 "a108_SW_BMB_Device_OT" 107 "a107_SW_Stack_Voltage_MIA" 106 "a106_SW_All_Module_Tsense" 105 "a105_SW_One_Module_Tsense" 100 "a100_ThermalEventSuspected" 99 "a099_SW_BMB_Communication" 98 "a098_SW_BMB_Data_Integrity_Loss" 97 "a097_SW_BMB_Over_CAN_Communication" 95 "a095_SW_UI_MIA" 94 "a094_SW_Drive_Inverter_MIA" 92 "a092_SW_ChargePort_Mia_On_Hvs" 91 "a091_SW_ChargePort_MIA" 90 "a090_SW_Gateway_MIA" 89 "a089_SW_VcFront_MIA" 88 "a088_SW_VcFront_MIA_InDrive" 87 "a087_SW_Feim_Test_Blocked" 86 "a086_SW_FC_Contactor_Mismatch" 85 "a085_SW_Pack_Contactor_Mismatch" 84 "a084_SW_Sleep_Wake_Aborted" 83 "a083_SW_Ctr_Close_Failure" 82 "a082_SW_Ctr_Force_Open" 81 "a081_SW_Ctr_Close_Blocked" 80 "a080_SW_Pack_Ctr_Impedance" 79 "a079_Max_Charge_Level_Exceeded" 78 "a078_Rapid_Dch_While_Charging" 77 "a077_SW_Charger_Regulation" 76 "a076_SW_Dch_While_Charging" 75 "a075_SW_Chg_Disable_Failure" 74 "a074_Max_Charge_Level_Reduced" 73 "a073_Unexpected_Loss_Of_Lv" 72 "a072_Module_Brick_Split" 71 "a071_SW_SM_TransCon_Not_Met" 70 "a070_BrickV_Imbalance_Limiting" 69 "a069_SW_Low_Power" 68 "a068_CAC_Imbalance_Limp" 67 "a067_CAC_Imbalance_Limiting" 66 "a066_SOC_Imbalance_Warning" 65 "a065_SW_CAC_Imbalance" 64 "a064_SW_SOC_Imbalance" 63 "a063_SW_ChargePort_Fault" 62 "a062_SW_BrickV_Imbalance" 61 "a061_SW_BrickV_Change" 60 "a060_SW_Leakage_Test_Failure" 59 "a059_SW_Pack_Voltage_Sensing" 58 "a058_SW_Bandolier_Model_Reset" 57 "a057_SW_Bandolier_Model_Warning" 56 "a056_SW_Standby_Supply_Fault" 55 "a055_SW_HvChain_Model_Fault" 54 "a054_SW_Ver_Supply_Fault" 52 "a052_SW_PCS_MIA" 51 "a051_SW_HVC_Vref_Bad" 50 "a050_SW_Brick_Voltage_MIA" 49 "a049_SW_Thermal_Event" 48 "a048_SW_Watch_Dog_Warning" 47 "a047_SW_Task_Stack_Overflow" 46 "a046_SW_Task_Stack_Usage" 45 "a045_SW_Exception" 44 "a044_SW_Assertion" 43 "a043_SW_Watch_Dog_Reset" 42 "a042_SW_MPU_Error" 41 "a041_SW_Destructive_Reset_Source" 40 "a040_SW_Watch_Dog_HW_Triggered" 39 "a039_SW_DC_Link_Over_Voltage" 37 "a037_SW_Flood_Port_Open" 36 "a036_SW_HvpHvilFault" 35 "a035_SW_Isolation" 34 "a034_SW_Passive_Isolation" 33 "a033_VoltageDeviation" 32 "a032_VoltageLoss" 31 "a031_AlertsSetDuringSleep" 30 "a030_Impedance_Deviation" 29 "a029_dSoc_Limiting" 28 "a028_ShuntAsicCurrentOffsetDeviation" 27 "a027_SW_Repeated_Isolation_Failure_In_Drive" 26 "a026_SW_HFCurrent_Anomaly" 25 "a025_SW_PwrBalance_Anomaly" 24 "a024_SW_Islanded_Brick" 23 "a023_SW_Stack_OV" 22 "a022_SW_Over_Current" 21 "a021_SW_Dr_Limits_Regulation" 20 "a020_SW_Brick_Instability" 19 "a019_SW_Module_OT" 18 "a018_SW_Brick_UV" 17 "a017_SW_Brick_OV" 16 "a016_Pack_Module_Id_Mismatch" 4 "a004_Cal_Vs_Serial_Birth_Date_Mismatch" 3 "a003_SW_Pack_Birth_Date_Missing" 2 "a002_Pack_Performance_Config_Mismatch" 1 "a001_Pack_Config_Mismatch" 0 "ALERT_DO_NOT_USE_ZERO" ;
VAL_ 1343 BMS_a082_secondAlertId 299 "a299_PowershareFailure" 291 "a291_SOC_Imbalance_By_Delta_Voltage_Over_Delta_SOC" 290 "d290_batteryPackTempSensorACircuitFailure" 289 "d289_batteryPackAOverTemperature" 288 "d288_batteryPackCellVoltageLow" 287 "d287_systemIsolationWarning" 286 "d286_dcLinkVoltageHigh" 285 "d285_packVoltageSensorACircuitFailure" 284 "d284_fastChargeNegContactorAStuckOpen" 283 "d283_fastChargeNegContactorAStuckClosed" 282 "d282_fastChargeNegContactorACircuitFailure" 281 "d281_fastChargePosContactorAStuckOpen" 280 "d280_fastChargePosContactorAStuckClosed" 279 "d279_fastChargePosContactorACircuitFailure" 278 "d278_packNegContactorAStuckClosed" 277 "d277_packNegContactorACircuitFailure" 276 "d276_packPosContactorAStuckClosed" 275 "d275_packPosContactorACircuitFailure" 274 "d274_packCurrentSensorACircuitFailure" 273 "d273_vcFrontCommsLost" 272 "d272_batteryPackSensorCommsLost" 271 "d271_batteryPackSensorFailure" 270 "d270_hvpCommsLost" 269 "d269_highVoltageFuseABlown" 268 "d268_hvpInvalidFirmwareConfig" 267 "d267_batteryPackCellVoltageSenseHarnessFailure" 266 "d266_energyReserveVoltageLow" 265 "d265_replaceBatteryPack" 264 "d264_invalidFirmwareConfig" 263 "d263_batterySystemCurrentHigh" 262 "d262_batteryPackLowStateOfCharge" 261 "d261_batteryPackCellVoltageHigh" 260 "d260_chargePortInterlockFailure" 259 "d259_highVoltageInterlockFailure" 258 "d258_externalIsolationFault" 257 "d257_internalIsolationFault" 256 "a256_SW_Low_Power_Warning" 255 "a255_EstimatedRangeReduced" 254 "a254_LdcsCacImbalance" 227 "a227_ExcessChargeCurrentInCharge" 221 "a221_PcsEmergencyShutdownRequested" 214 "a214_AcChargeAborted" 204 "a204_AcCpEmergencyShutdownRequested" 202 "a202_AcChargeFaulted" 201 "a201_SW_Brick_OV_During_Charge" 200 "a200_GridFollowFaulted" 199 "a199_GridFollowAborted" 198 "a198_SW_SOC_Abrupt_Change" 197 "a197_SW_High_SOC_OV" 196 "a196_SW_PackVoltageUnderThreshold" 195 "a195_SW_DeltaTempOverThreshold" 194 "a194_PowershareLimitViolation" 193 "a193_PowershareMaxBrickVoltageViolation" 192 "a192_PowershareExternalChargeRegulation" 191 "a191_PowershareMinVoltageViolation" 190 "a190_PowershareMaxVoltageViolation" 189 "a189_PowershareDischargeCurrentViolation" 188 "a188_PowershareChargeCurrentViolation" 187 "a187_RippleHeatingEmergencyShutdown" 186 "a186_RippleHeatingChargeFault" 185 "a185_LifeModel_CyclingDcrGrowth_Change" 184 "a184_LifeModel_CyclingLoss_Change" 183 "a183_LifeModel_StoDcrGrowth_Change" 182 "a182_LifeModel_NoCurrentLoss_Change" 181 "a181_SW_Shunt_Over_Temperature" 180 "a180_SW_ECU_reset_blocked" 179 "a179_HvpGpoRequestActive" 178 "a178_SW_Uncontrolled_Regen_PwrB" 177 "a177_SW_Energy_Buffer_Size" 176 "a176_SW_GracefulPowerOff" 175 "a175_Charge_Failure_External" 174 "a174_SW_Charge_Failure" 173 "a173_FullPackEnergyDegraded" 172 "a172_SW_Isolation_Failure_In_Drive_Warning" 171 "a171_SW_Stack_Voltage_Sense" 170 "a170_SW_Limp_Mode" 169 "a169_SW_FC_Pack_Weld" 168 "a168_SW_FC_Full_Weld" 167 "a167_SW_FC_Partial_Weld" 166 "a166_SW_Pack_Full_Weld" 165 "a165_SW_Pack_Partial_Weld" 164 "a164_SW_Uncontrolled_Regen" 163 "a163_GridFormAborted" 162 "a162_SW_No_Power_For_Support" 161 "a161_SW_BMB_Vref_warning" 160 "a160_SW_FC_Ctr_Clean_Failed" 159 "a159_SW_HVP_ECU_Error" 158 "a158_SW_HVP_HVI_Comms" 157 "a157_SW_Hist_Update_Missed" 156 "a156_SW_BMB_Vref_bad" 155 "a155_SW_Weak_short_impedence" 154 "a154_SW_Brick_OV_Warning_Stop_Charge" 153 "a153_GridFormFaulted" 152 "a152_Isolation_In_Dc_Charge" 151 "a151_SW_external_isolation" 150 "a150_SW_Missing_Part_Number" 149 "a149_SW_Missing_Config_Block" 148 "a148_SW_Unsupported_BMB_ASIC_Type" 147 "a147_SW_SOC_High_Ah_Error" 146 "a146_SW_Brick_Overdischarged" 145 "a145_SW_SOC_Change" 144 "a144_Hvp_Config_Mismatch" 143 "a143_SW_CAC_Change" 142 "a142_SW_Isolation_Degradation" 141 "a141_SW_BMB_Status_Warning" 140 "a140_HW_BMB_Status_Fault" 139 "a139_SW_DC_Link_V_Irrational" 138 "a138_SW_Brick_OV_Warning" 137 "a137_SW_Brick_UV_Warning" 136 "a136_SW_Module_OT_Warning" 135 "a135_HW_BMB_Diagnostics_Failure" 134 "a134_SW_Delayed_Ctr_Off" 133 "a133_IO_CAN_Bus_Off" 132 "a132_HW_BMB_OTP_Uncorrctbl" 131 "a131_Bleed_FET_Failure" 130 "a130_IO_CAN_Error" 129 "a129_SW_VSH_Failure" 128 "a128_SW_shunt_MIA" 127 "a127_SW_shunt_SNA" 126 "a126_SW_Thermistor_Failure" 124 "a124_Battery_Coolant_Flood" 123 "a123_SW_Internal_Isolation" 122 "a122_SW_BMS_Therm_Irrational" 121 "a121_SW_NVRAM_Config_Error" 120 "a120_SW_Delta_SOC_User_Warning" 119 "a119_Fast_Open_Vsh_Detected" 118 "a118_SW_Delta_SOC_Weak_Short_Warning" 117 "a117_SW_Delta_SOC_Weak_Short" 115 "a115_Energy_Rubberbanding_Reset" 112 "a112_LifeModel_Discontinuity" 111 "a111_LifeModel_Spread_Change" 110 "a110_LifeModel_AvgOffset_Change" 109 "a109_HW_BMB_Mute_Status_Mismatch" 108 "a108_SW_BMB_Device_OT" 107 "a107_SW_Stack_Voltage_MIA" 106 "a106_SW_All_Module_Tsense" 105 "a105_SW_One_Module_Tsense" 100 "a100_ThermalEventSuspected" 99 "a099_SW_BMB_Communication" 98 "a098_SW_BMB_Data_Integrity_Loss" 97 "a097_SW_BMB_Over_CAN_Communication" 95 "a095_SW_UI_MIA" 94 "a094_SW_Drive_Inverter_MIA" 92 "a092_SW_ChargePort_Mia_On_Hvs" 91 "a091_SW_ChargePort_MIA" 90 "a090_SW_Gateway_MIA" 89 "a089_SW_VcFront_MIA" 88 "a088_SW_VcFront_MIA_InDrive" 87 "a087_SW_Feim_Test_Blocked" 86 "a086_SW_FC_Contactor_Mismatch" 85 "a085_SW_Pack_Contactor_Mismatch" 84 "a084_SW_Sleep_Wake_Aborted" 83 "a083_SW_Ctr_Close_Failure" 82 "a082_SW_Ctr_Force_Open" 81 "a081_SW_Ctr_Close_Blocked" 80 "a080_SW_Pack_Ctr_Impedance" 79 "a079_Max_Charge_Level_Exceeded" 78 "a078_Rapid_Dch_While_Charging" 77 "a077_SW_Charger_Regulation" 76 "a076_SW_Dch_While_Charging" 75 "a075_SW_Chg_Disable_Failure" 74 "a074_Max_Charge_Level_Reduced" 73 "a073_Unexpected_Loss_Of_Lv" 72 "a072_Module_Brick_Split" 71 "a071_SW_SM_TransCon_Not_Met" 70 "a070_BrickV_Imbalance_Limiting" 69 "a069_SW_Low_Power" 68 "a068_CAC_Imbalance_Limp" 67 "a067_CAC_Imbalance_Limiting" 66 "a066_SOC_Imbalance_Warning" 65 "a065_SW_CAC_Imbalance" 64 "a064_SW_SOC_Imbalance" 63 "a063_SW_ChargePort_Fault" 62 "a062_SW_BrickV_Imbalance" 61 "a061_SW_BrickV_Change" 60 "a060_SW_Leakage_Test_Failure" 59 "a059_SW_Pack_Voltage_Sensing" 58 "a058_SW_Bandolier_Model_Reset" 57 "a057_SW_Bandolier_Model_Warning" 56 "a056_SW_Standby_Supply_Fault" 55 "a055_SW_HvChain_Model_Fault" 54 "a054_SW_Ver_Supply_Fault" 52 "a052_SW_PCS_MIA" 51 "a051_SW_HVC_Vref_Bad" 50 "a050_SW_Brick_Voltage_MIA" 49 "a049_SW_Thermal_Event" 48 "a048_SW_Watch_Dog_Warning" 47 "a047_SW_Task_Stack_Overflow" 46 "a046_SW_Task_Stack_Usage" 45 "a045_SW_Exception" 44 "a044_SW_Assertion" 43 "a043_SW_Watch_Dog_Reset" 42 "a042_SW_MPU_Error" 41 "a041_SW_Destructive_Reset_Source" 40 "a040_SW_Watch_Dog_HW_Triggered" 39 "a039_SW_DC_Link_Over_Voltage" 37 "a037_SW_Flood_Port_Open" 36 "a036_SW_HvpHvilFault" 35 "a035_SW_Isolation" 34 "a034_SW_Passive_Isolation" 33 "a033_VoltageDeviation" 32 "a032_VoltageLoss" 31 "a031_AlertsSetDuringSleep" 30 "a030_Impedance_Deviation" 29 "a029_dSoc_Limiting" 28 "a028_ShuntAsicCurrentOffsetDeviation" 27 "a027_SW_Repeated_Isolation_Failure_In_Drive" 26 "a026_SW_HFCurrent_Anomaly" 25 "a025_SW_PwrBalance_Anomaly" 24 "a024_SW_Islanded_Brick" 23 "a023_SW_Stack_OV" 22 "a022_SW_Over_Current" 21 "a021_SW_Dr_Limits_Regulation" 20 "a020_SW_Brick_Instability" 19 "a019_SW_Module_OT" 18 "a018_SW_Brick_UV" 17 "a017_SW_Brick_OV" 16 "a016_Pack_Module_Id_Mismatch" 4 "a004_Cal_Vs_Serial_Birth_Date_Mismatch" 3 "a003_SW_Pack_Birth_Date_Missing" 2 "a002_Pack_Performance_Config_Mismatch" 1 "a001_Pack_Config_Mismatch" 0 "ALERT_DO_NOT_USE_ZERO" ;
VAL_ 1343 BMS_a082_thirdAlertId 299 "a299_PowershareFailure" 291 "a291_SOC_Imbalance_By_Delta_Voltage_Over_Delta_SOC" 290 "d290_batteryPackTempSensorACircuitFailure" 289 "d289_batteryPackAOverTemperature" 288 "d288_batteryPackCellVoltageLow" 287 "d287_systemIsolationWarning" 286 "d286_dcLinkVoltageHigh" 285 "d285_packVoltageSensorACircuitFailure" 284 "d284_fastChargeNegContactorAStuckOpen" 283 "d283_fastChargeNegContactorAStuckClosed" 282 "d282_fastChargeNegContactorACircuitFailure" 281 "d281_fastChargePosContactorAStuckOpen" 280 "d280_fastChargePosContactorAStuckClosed" 279 "d279_fastChargePosContactorACircuitFailure" 278 "d278_packNegContactorAStuckClosed" 277 "d277_packNegContactorACircuitFailure" 276 "d276_packPosContactorAStuckClosed" 275 "d275_packPosContactorACircuitFailure" 274 "d274_packCurrentSensorACircuitFailure" 273 "d273_vcFrontCommsLost" 272 "d272_batteryPackSensorCommsLost" 271 "d271_batteryPackSensorFailure" 270 "d270_hvpCommsLost" 269 "d269_highVoltageFuseABlown" 268 "d268_hvpInvalidFirmwareConfig" 267 "d267_batteryPackCellVoltageSenseHarnessFailure" 266 "d266_energyReserveVoltageLow" 265 "d265_replaceBatteryPack" 264 "d264_invalidFirmwareConfig" 263 "d263_batterySystemCurrentHigh" 262 "d262_batteryPackLowStateOfCharge" 261 "d261_batteryPackCellVoltageHigh" 260 "d260_chargePortInterlockFailure" 259 "d259_highVoltageInterlockFailure" 258 "d258_externalIsolationFault" 257 "d257_internalIsolationFault" 256 "a256_SW_Low_Power_Warning" 255 "a255_EstimatedRangeReduced" 254 "a254_LdcsCacImbalance" 227 "a227_ExcessChargeCurrentInCharge" 221 "a221_PcsEmergencyShutdownRequested" 214 "a214_AcChargeAborted" 204 "a204_AcCpEmergencyShutdownRequested" 202 "a202_AcChargeFaulted" 201 "a201_SW_Brick_OV_During_Charge" 200 "a200_GridFollowFaulted" 199 "a199_GridFollowAborted" 198 "a198_SW_SOC_Abrupt_Change" 197 "a197_SW_High_SOC_OV" 196 "a196_SW_PackVoltageUnderThreshold" 195 "a195_SW_DeltaTempOverThreshold" 194 "a194_PowershareLimitViolation" 193 "a193_PowershareMaxBrickVoltageViolation" 192 "a192_PowershareExternalChargeRegulation" 191 "a191_PowershareMinVoltageViolation" 190 "a190_PowershareMaxVoltageViolation" 189 "a189_PowershareDischargeCurrentViolation" 188 "a188_PowershareChargeCurrentViolation" 187 "a187_RippleHeatingEmergencyShutdown" 186 "a186_RippleHeatingChargeFault" 185 "a185_LifeModel_CyclingDcrGrowth_Change" 184 "a184_LifeModel_CyclingLoss_Change" 183 "a183_LifeModel_StoDcrGrowth_Change" 182 "a182_LifeModel_NoCurrentLoss_Change" 181 "a181_SW_Shunt_Over_Temperature" 180 "a180_SW_ECU_reset_blocked" 179 "a179_HvpGpoRequestActive" 178 "a178_SW_Uncontrolled_Regen_PwrB" 177 "a177_SW_Energy_Buffer_Size" 176 "a176_SW_GracefulPowerOff" 175 "a175_Charge_Failure_External" 174 "a174_SW_Charge_Failure" 173 "a173_FullPackEnergyDegraded" 172 "a172_SW_Isolation_Failure_In_Drive_Warning" 171 "a171_SW_Stack_Voltage_Sense" 170 "a170_SW_Limp_Mode" 169 "a169_SW_FC_Pack_Weld" 168 "a168_SW_FC_Full_Weld" 167 "a167_SW_FC_Partial_Weld" 166 "a166_SW_Pack_Full_Weld" 165 "a165_SW_Pack_Partial_Weld" 164 "a164_SW_Uncontrolled_Regen" 163 "a163_GridFormAborted" 162 "a162_SW_No_Power_For_Support" 161 "a161_SW_BMB_Vref_warning" 160 "a160_SW_FC_Ctr_Clean_Failed" 159 "a159_SW_HVP_ECU_Error" 158 "a158_SW_HVP_HVI_Comms" 157 "a157_SW_Hist_Update_Missed" 156 "a156_SW_BMB_Vref_bad" 155 "a155_SW_Weak_short_impedence" 154 "a154_SW_Brick_OV_Warning_Stop_Charge" 153 "a153_GridFormFaulted" 152 "a152_Isolation_In_Dc_Charge" 151 "a151_SW_external_isolation" 150 "a150_SW_Missing_Part_Number" 149 "a149_SW_Missing_Config_Block" 148 "a148_SW_Unsupported_BMB_ASIC_Type" 147 "a147_SW_SOC_High_Ah_Error" 146 "a146_SW_Brick_Overdischarged" 145 "a145_SW_SOC_Change" 144 "a144_Hvp_Config_Mismatch" 143 "a143_SW_CAC_Change" 142 "a142_SW_Isolation_Degradation" 141 "a141_SW_BMB_Status_Warning" 140 "a140_HW_BMB_Status_Fault" 139 "a139_SW_DC_Link_V_Irrational" 138 "a138_SW_Brick_OV_Warning" 137 "a137_SW_Brick_UV_Warning" 136 "a136_SW_Module_OT_Warning" 135 "a135_HW_BMB_Diagnostics_Failure" 134 "a134_SW_Delayed_Ctr_Off" 133 "a133_IO_CAN_Bus_Off" 132 "a132_HW_BMB_OTP_Uncorrctbl" 131 "a131_Bleed_FET_Failure" 130 "a130_IO_CAN_Error" 129 "a129_SW_VSH_Failure" 128 "a128_SW_shunt_MIA" 127 "a127_SW_shunt_SNA" 126 "a126_SW_Thermistor_Failure" 124 "a124_Battery_Coolant_Flood" 123 "a123_SW_Internal_Isolation" 122 "a122_SW_BMS_Therm_Irrational" 121 "a121_SW_NVRAM_Config_Error" 120 "a120_SW_Delta_SOC_User_Warning" 119 "a119_Fast_Open_Vsh_Detected" 118 "a118_SW_Delta_SOC_Weak_Short_Warning" 117 "a117_SW_Delta_SOC_Weak_Short" 115 "a115_Energy_Rubberbanding_Reset" 112 "a112_LifeModel_Discontinuity" 111 "a111_LifeModel_Spread_Change" 110 "a110_LifeModel_AvgOffset_Change" 109 "a109_HW_BMB_Mute_Status_Mismatch" 108 "a108_SW_BMB_Device_OT" 107 "a107_SW_Stack_Voltage_MIA" 106 "a106_SW_All_Module_Tsense" 105 "a105_SW_One_Module_Tsense" 100 "a100_ThermalEventSuspected" 99 "a099_SW_BMB_Communication" 98 "a098_SW_BMB_Data_Integrity_Loss" 97 "a097_SW_BMB_Over_CAN_Communication" 95 "a095_SW_UI_MIA" 94 "a094_SW_Drive_Inverter_MIA" 92 "a092_SW_ChargePort_Mia_On_Hvs" 91 "a091_SW_ChargePort_MIA" 90 "a090_SW_Gateway_MIA" 89 "a089_SW_VcFront_MIA" 88 "a088_SW_VcFront_MIA_InDrive" 87 "a087_SW_Feim_Test_Blocked" 86 "a086_SW_FC_Contactor_Mismatch" 85 "a085_SW_Pack_Contactor_Mismatch" 84 "a084_SW_Sleep_Wake_Aborted" 83 "a083_SW_Ctr_Close_Failure" 82 "a082_SW_Ctr_Force_Open" 81 "a081_SW_Ctr_Close_Blocked" 80 "a080_SW_Pack_Ctr_Impedance" 79 "a079_Max_Charge_Level_Exceeded" 78 "a078_Rapid_Dch_While_Charging" 77 "a077_SW_Charger_Regulation" 76 "a076_SW_Dch_While_Charging" 75 "a075_SW_Chg_Disable_Failure" 74 "a074_Max_Charge_Level_Reduced" 73 "a073_Unexpected_Loss_Of_Lv" 72 "a072_Module_Brick_Split" 71 "a071_SW_SM_TransCon_Not_Met" 70 "a070_BrickV_Imbalance_Limiting" 69 "a069_SW_Low_Power" 68 "a068_CAC_Imbalance_Limp" 67 "a067_CAC_Imbalance_Limiting" 66 "a066_SOC_Imbalance_Warning" 65 "a065_SW_CAC_Imbalance" 64 "a064_SW_SOC_Imbalance" 63 "a063_SW_ChargePort_Fault" 62 "a062_SW_BrickV_Imbalance" 61 "a061_SW_BrickV_Change" 60 "a060_SW_Leakage_Test_Failure" 59 "a059_SW_Pack_Voltage_Sensing" 58 "a058_SW_Bandolier_Model_Reset" 57 "a057_SW_Bandolier_Model_Warning" 56 "a056_SW_Standby_Supply_Fault" 55 "a055_SW_HvChain_Model_Fault" 54 "a054_SW_Ver_Supply_Fault" 52 "a052_SW_PCS_MIA" 51 "a051_SW_HVC_Vref_Bad" 50 "a050_SW_Brick_Voltage_MIA" 49 "a049_SW_Thermal_Event" 48 "a048_SW_Watch_Dog_Warning" 47 "a047_SW_Task_Stack_Overflow" 46 "a046_SW_Task_Stack_Usage" 45 "a045_SW_Exception" 44 "a044_SW_Assertion" 43 "a043_SW_Watch_Dog_Reset" 42 "a042_SW_MPU_Error" 41 "a041_SW_Destructive_Reset_Source" 40 "a040_SW_Watch_Dog_HW_Triggered" 39 "a039_SW_DC_Link_Over_Voltage" 37 "a037_SW_Flood_Port_Open" 36 "a036_SW_HvpHvilFault" 35 "a035_SW_Isolation" 34 "a034_SW_Passive_Isolation" 33 "a033_VoltageDeviation" 32 "a032_VoltageLoss" 31 "a031_AlertsSetDuringSleep" 30 "a030_Impedance_Deviation" 29 "a029_dSoc_Limiting" 28 "a028_ShuntAsicCurrentOffsetDeviation" 27 "a027_SW_Repeated_Isolation_Failure_In_Drive" 26 "a026_SW_HFCurrent_Anomaly" 25 "a025_SW_PwrBalance_Anomaly" 24 "a024_SW_Islanded_Brick" 23 "a023_SW_Stack_OV" 22 "a022_SW_Over_Current" 21 "a021_SW_Dr_Limits_Regulation" 20 "a020_SW_Brick_Instability" 19 "a019_SW_Module_OT" 18 "a018_SW_Brick_UV" 17 "a017_SW_Brick_OV" 16 "a016_Pack_Module_Id_Mismatch" 4 "a004_Cal_Vs_Serial_Birth_Date_Mismatch" 3 "a003_SW_Pack_Birth_Date_Missing" 2 "a002_Pack_Performance_Config_Mismatch" 1 "a001_Pack_Config_Mismatch" 0 "ALERT_DO_NOT_USE_ZERO" ;
VAL_ 1343 BMS_a082_fourthAlertId 299 "a299_PowershareFailure" 291 "a291_SOC_Imbalance_By_Delta_Voltage_Over_Delta_SOC" 290 "d290_batteryPackTempSensorACircuitFailure" 289 "d289_batteryPackAOverTemperature" 288 "d288_batteryPackCellVoltageLow" 287 "d287_systemIsolationWarning" 286 "d286_dcLinkVoltageHigh" 285 "d285_packVoltageSensorACircuitFailure" 284 "d284_fastChargeNegContactorAStuckOpen" 283 "d283_fastChargeNegContactorAStuckClosed" 282 "d282_fastChargeNegContactorACircuitFailure" 281 "d281_fastChargePosContactorAStuckOpen" 280 "d280_fastChargePosContactorAStuckClosed" 279 "d279_fastChargePosContactorACircuitFailure" 278 "d278_packNegContactorAStuckClosed" 277 "d277_packNegContactorACircuitFailure" 276 "d276_packPosContactorAStuckClosed" 275 "d275_packPosContactorACircuitFailure" 274 "d274_packCurrentSensorACircuitFailure" 273 "d273_vcFrontCommsLost" 272 "d272_batteryPackSensorCommsLost" 271 "d271_batteryPackSensorFailure" 270 "d270_hvpCommsLost" 269 "d269_highVoltageFuseABlown" 268 "d268_hvpInvalidFirmwareConfig" 267 "d267_batteryPackCellVoltageSenseHarnessFailure" 266 "d266_energyReserveVoltageLow" 265 "d265_replaceBatteryPack" 264 "d264_invalidFirmwareConfig" 263 "d263_batterySystemCurrentHigh" 262 "d262_batteryPackLowStateOfCharge" 261 "d261_batteryPackCellVoltageHigh" 260 "d260_chargePortInterlockFailure" 259 "d259_highVoltageInterlockFailure" 258 "d258_externalIsolationFault" 257 "d257_internalIsolationFault" 256 "a256_SW_Low_Power_Warning" 255 "a255_EstimatedRangeReduced" 254 "a254_LdcsCacImbalance" 227 "a227_ExcessChargeCurrentInCharge" 221 "a221_PcsEmergencyShutdownRequested" 214 "a214_AcChargeAborted" 204 "a204_AcCpEmergencyShutdownRequested" 202 "a202_AcChargeFaulted" 201 "a201_SW_Brick_OV_During_Charge" 200 "a200_GridFollowFaulted" 199 "a199_GridFollowAborted" 198 "a198_SW_SOC_Abrupt_Change" 197 "a197_SW_High_SOC_OV" 196 "a196_SW_PackVoltageUnderThreshold" 195 "a195_SW_DeltaTempOverThreshold" 194 "a194_PowershareLimitViolation" 193 "a193_PowershareMaxBrickVoltageViolation" 192 "a192_PowershareExternalChargeRegulation" 191 "a191_PowershareMinVoltageViolation" 190 "a190_PowershareMaxVoltageViolation" 189 "a189_PowershareDischargeCurrentViolation" 188 "a188_PowershareChargeCurrentViolation" 187 "a187_RippleHeatingEmergencyShutdown" 186 "a186_RippleHeatingChargeFault" 185 "a185_LifeModel_CyclingDcrGrowth_Change" 184 "a184_LifeModel_CyclingLoss_Change" 183 "a183_LifeModel_StoDcrGrowth_Change" 182 "a182_LifeModel_NoCurrentLoss_Change" 181 "a181_SW_Shunt_Over_Temperature" 180 "a180_SW_ECU_reset_blocked" 179 "a179_HvpGpoRequestActive" 178 "a178_SW_Uncontrolled_Regen_PwrB" 177 "a177_SW_Energy_Buffer_Size" 176 "a176_SW_GracefulPowerOff" 175 "a175_Charge_Failure_External" 174 "a174_SW_Charge_Failure" 173 "a173_FullPackEnergyDegraded" 172 "a172_SW_Isolation_Failure_In_Drive_Warning" 171 "a171_SW_Stack_Voltage_Sense" 170 "a170_SW_Limp_Mode" 169 "a169_SW_FC_Pack_Weld" 168 "a168_SW_FC_Full_Weld" 167 "a167_SW_FC_Partial_Weld" 166 "a166_SW_Pack_Full_Weld" 165 "a165_SW_Pack_Partial_Weld" 164 "a164_SW_Uncontrolled_Regen" 163 "a163_GridFormAborted" 162 "a162_SW_No_Power_For_Support" 161 "a161_SW_BMB_Vref_warning" 160 "a160_SW_FC_Ctr_Clean_Failed" 159 "a159_SW_HVP_ECU_Error" 158 "a158_SW_HVP_HVI_Comms" 157 "a157_SW_Hist_Update_Missed" 156 "a156_SW_BMB_Vref_bad" 155 "a155_SW_Weak_short_impedence" 154 "a154_SW_Brick_OV_Warning_Stop_Charge" 153 "a153_GridFormFaulted" 152 "a152_Isolation_In_Dc_Charge" 151 "a151_SW_external_isolation" 150 "a150_SW_Missing_Part_Number" 149 "a149_SW_Missing_Config_Block" 148 "a148_SW_Unsupported_BMB_ASIC_Type" 147 "a147_SW_SOC_High_Ah_Error" 146 "a146_SW_Brick_Overdischarged" 145 "a145_SW_SOC_Change" 144 "a144_Hvp_Config_Mismatch" 143 "a143_SW_CAC_Change" 142 "a142_SW_Isolation_Degradation" 141 "a141_SW_BMB_Status_Warning" 140 "a140_HW_BMB_Status_Fault" 139 "a139_SW_DC_Link_V_Irrational" 138 "a138_SW_Brick_OV_Warning" 137 "a137_SW_Brick_UV_Warning" 136 "a136_SW_Module_OT_Warning" 135 "a135_HW_BMB_Diagnostics_Failure" 134 "a134_SW_Delayed_Ctr_Off" 133 "a133_IO_CAN_Bus_Off" 132 "a132_HW_BMB_OTP_Uncorrctbl" 131 "a131_Bleed_FET_Failure" 130 "a130_IO_CAN_Error" 129 "a129_SW_VSH_Failure" 128 "a128_SW_shunt_MIA" 127 "a127_SW_shunt_SNA" 126 "a126_SW_Thermistor_Failure" 124 "a124_Battery_Coolant_Flood" 123 "a123_SW_Internal_Isolation" 122 "a122_SW_BMS_Therm_Irrational" 121 "a121_SW_NVRAM_Config_Error" 120 "a120_SW_Delta_SOC_User_Warning" 119 "a119_Fast_Open_Vsh_Detected" 118 "a118_SW_Delta_SOC_Weak_Short_Warning" 117 "a117_SW_Delta_SOC_Weak_Short" 115 "a115_Energy_Rubberbanding_Reset" 112 "a112_LifeModel_Discontinuity" 111 "a111_LifeModel_Spread_Change" 110 "a110_LifeModel_AvgOffset_Change" 109 "a109_HW_BMB_Mute_Status_Mismatch" 108 "a108_SW_BMB_Device_OT" 107 "a107_SW_Stack_Voltage_MIA" 106 "a106_SW_All_Module_Tsense" 105 "a105_SW_One_Module_Tsense" 100 "a100_ThermalEventSuspected" 99 "a099_SW_BMB_Communication" 98 "a098_SW_BMB_Data_Integrity_Loss" 97 "a097_SW_BMB_Over_CAN_Communication" 95 "a095_SW_UI_MIA" 94 "a094_SW_Drive_Inverter_MIA" 92 "a092_SW_ChargePort_Mia_On_Hvs" 91 "a091_SW_ChargePort_MIA" 90 "a090_SW_Gateway_MIA" 89 "a089_SW_VcFront_MIA" 88 "a088_SW_VcFront_MIA_InDrive" 87 "a087_SW_Feim_Test_Blocked" 86 "a086_SW_FC_Contactor_Mismatch" 85 "a085_SW_Pack_Contactor_Mismatch" 84 "a084_SW_Sleep_Wake_Aborted" 83 "a083_SW_Ctr_Close_Failure" 82 "a082_SW_Ctr_Force_Open" 81 "a081_SW_Ctr_Close_Blocked" 80 "a080_SW_Pack_Ctr_Impedance" 79 "a079_Max_Charge_Level_Exceeded" 78 "a078_Rapid_Dch_While_Charging" 77 "a077_SW_Charger_Regulation" 76 "a076_SW_Dch_While_Charging" 75 "a075_SW_Chg_Disable_Failure" 74 "a074_Max_Charge_Level_Reduced" 73 "a073_Unexpected_Loss_Of_Lv" 72 "a072_Module_Brick_Split" 71 "a071_SW_SM_TransCon_Not_Met" 70 "a070_BrickV_Imbalance_Limiting" 69 "a069_SW_Low_Power" 68 "a068_CAC_Imbalance_Limp" 67 "a067_CAC_Imbalance_Limiting" 66 "a066_SOC_Imbalance_Warning" 65 "a065_SW_CAC_Imbalance" 64 "a064_SW_SOC_Imbalance" 63 "a063_SW_ChargePort_Fault" 62 "a062_SW_BrickV_Imbalance" 61 "a061_SW_BrickV_Change" 60 "a060_SW_Leakage_Test_Failure" 59 "a059_SW_Pack_Voltage_Sensing" 58 "a058_SW_Bandolier_Model_Reset" 57 "a057_SW_Bandolier_Model_Warning" 56 "a056_SW_Standby_Supply_Fault" 55 "a055_SW_HvChain_Model_Fault" 54 "a054_SW_Ver_Supply_Fault" 52 "a052_SW_PCS_MIA" 51 "a051_SW_HVC_Vref_Bad" 50 "a050_SW_Brick_Voltage_MIA" 49 "a049_SW_Thermal_Event" 48 "a048_SW_Watch_Dog_Warning" 47 "a047_SW_Task_Stack_Overflow" 46 "a046_SW_Task_Stack_Usage" 45 "a045_SW_Exception" 44 "a044_SW_Assertion" 43 "a043_SW_Watch_Dog_Reset" 42 "a042_SW_MPU_Error" 41 "a041_SW_Destructive_Reset_Source" 40 "a040_SW_Watch_Dog_HW_Triggered" 39 "a039_SW_DC_Link_Over_Voltage" 37 "a037_SW_Flood_Port_Open" 36 "a036_SW_HvpHvilFault" 35 "a035_SW_Isolation" 34 "a034_SW_Passive_Isolation" 33 "a033_VoltageDeviation" 32 "a032_VoltageLoss" 31 "a031_AlertsSetDuringSleep" 30 "a030_Impedance_Deviation" 29 "a029_dSoc_Limiting" 28 "a028_ShuntAsicCurrentOffsetDeviation" 27 "a027_SW_Repeated_Isolation_Failure_In_Drive" 26 "a026_SW_HFCurrent_Anomaly" 25 "a025_SW_PwrBalance_Anomaly" 24 "a024_SW_Islanded_Brick" 23 "a023_SW_Stack_OV" 22 "a022_SW_Over_Current" 21 "a021_SW_Dr_Limits_Regulation" 20 "a020_SW_Brick_Instability" 19 "a019_SW_Module_OT" 18 "a018_SW_Brick_UV" 17 "a017_SW_Brick_OV" 16 "a016_Pack_Module_Id_Mismatch" 4 "a004_Cal_Vs_Serial_Birth_Date_Mismatch" 3 "a003_SW_Pack_Birth_Date_Missing" 2 "a002_Pack_Performance_Config_Mismatch" 1 "a001_Pack_Config_Mismatch" 0 "ALERT_DO_NOT_USE_ZERO" ;
VAL_ 1343 BMS_a083_packContactorRequest 5 "FAULT_OPEN" 4 "OPEN" 3 "CLOSED" 2 "POS_CLOSED_NEG_OPEN" 1 "NEG_CLOSED_POS_OPEN" 0 "SNA" ;
VAL_ 1343 BMS_a085_packContactorSetStatePr 9 "NEGATIVE_CLOSED" 8 "POSITIVE_CLOSED" 7 "WELDED" 6 "PARTIAL_WELD" 5 "CLOSED" 4 "OPENING" 3 "BLOCKED" 2 "CLOSING" 1 "OPEN" 0 "SNA" ;
VAL_ 1343 BMS_a085_packContactorSetState 9 "NEGATIVE_CLOSED" 8 "POSITIVE_CLOSED" 7 "WELDED" 6 "PARTIAL_WELD" 5 "CLOSED" 4 "OPENING" 3 "BLOCKED" 2 "CLOSING" 1 "OPEN" 0 "SNA" ;
VAL_ 1343 BMS_a085_packContactorSetRe_0001 5 "CLOSE_POSITIVE_ONLY" 4 "CLOSE_NEGATIVE_ONLY" 3 "OPEN_IMMEDIATELY" 2 "OPEN" 1 "CLOSE" 0 "SNA" ;
VAL_ 1343 BMS_a085_packContactorSetRequest 5 "CLOSE_POSITIVE_ONLY" 4 "CLOSE_NEGATIVE_ONLY" 3 "OPEN_IMMEDIATELY" 2 "OPEN" 1 "CLOSE" 0 "SNA" ;
VAL_ 1343 BMS_a086_fcContactorSetStatePrev 9 "NEGATIVE_CLOSED" 8 "POSITIVE_CLOSED" 7 "WELDED" 6 "PARTIAL_WELD" 5 "CLOSED" 4 "OPENING" 3 "BLOCKED" 2 "CLOSING" 1 "OPEN" 0 "SNA" ;
VAL_ 1343 BMS_a086_fcContactorSetState 9 "NEGATIVE_CLOSED" 8 "POSITIVE_CLOSED" 7 "WELDED" 6 "PARTIAL_WELD" 5 "CLOSED" 4 "OPENING" 3 "BLOCKED" 2 "CLOSING" 1 "OPEN" 0 "SNA" ;
VAL_ 1343 BMS_a086_fcContactorSetRequestPr 5 "CLOSE_POSITIVE_ONLY" 4 "CLOSE_NEGATIVE_ONLY" 3 "OPEN_IMMEDIATELY" 2 "OPEN" 1 "CLOSE" 0 "SNA" ;
VAL_ 1343 BMS_a086_fcContactorSetRequest 5 "CLOSE_POSITIVE_ONLY" 4 "CLOSE_NEGATIVE_ONLY" 3 "OPEN_IMMEDIATELY" 2 "OPEN" 1 "CLOSE" 0 "SNA" ;
VAL_ 1343 BMS_a087_blockingAlert 299 "a299_PowershareFailure" 291 "a291_SOC_Imbalance_By_Delta_Voltage_Over_Delta_SOC" 290 "d290_batteryPackTempSensorACircuitFailure" 289 "d289_batteryPackAOverTemperature" 288 "d288_batteryPackCellVoltageLow" 287 "d287_systemIsolationWarning" 286 "d286_dcLinkVoltageHigh" 285 "d285_packVoltageSensorACircuitFailure" 284 "d284_fastChargeNegContactorAStuckOpen" 283 "d283_fastChargeNegContactorAStuckClosed" 282 "d282_fastChargeNegContactorACircuitFailure" 281 "d281_fastChargePosContactorAStuckOpen" 280 "d280_fastChargePosContactorAStuckClosed" 279 "d279_fastChargePosContactorACircuitFailure" 278 "d278_packNegContactorAStuckClosed" 277 "d277_packNegContactorACircuitFailure" 276 "d276_packPosContactorAStuckClosed" 275 "d275_packPosContactorACircuitFailure" 274 "d274_packCurrentSensorACircuitFailure" 273 "d273_vcFrontCommsLost" 272 "d272_batteryPackSensorCommsLost" 271 "d271_batteryPackSensorFailure" 270 "d270_hvpCommsLost" 269 "d269_highVoltageFuseABlown" 268 "d268_hvpInvalidFirmwareConfig" 267 "d267_batteryPackCellVoltageSenseHarnessFailure" 266 "d266_energyReserveVoltageLow" 265 "d265_replaceBatteryPack" 264 "d264_invalidFirmwareConfig" 263 "d263_batterySystemCurrentHigh" 262 "d262_batteryPackLowStateOfCharge" 261 "d261_batteryPackCellVoltageHigh" 260 "d260_chargePortInterlockFailure" 259 "d259_highVoltageInterlockFailure" 258 "d258_externalIsolationFault" 257 "d257_internalIsolationFault" 256 "a256_SW_Low_Power_Warning" 255 "a255_EstimatedRangeReduced" 254 "a254_LdcsCacImbalance" 227 "a227_ExcessChargeCurrentInCharge" 221 "a221_PcsEmergencyShutdownRequested" 214 "a214_AcChargeAborted" 204 "a204_AcCpEmergencyShutdownRequested" 202 "a202_AcChargeFaulted" 201 "a201_SW_Brick_OV_During_Charge" 200 "a200_GridFollowFaulted" 199 "a199_GridFollowAborted" 198 "a198_SW_SOC_Abrupt_Change" 197 "a197_SW_High_SOC_OV" 196 "a196_SW_PackVoltageUnderThreshold" 195 "a195_SW_DeltaTempOverThreshold" 194 "a194_PowershareLimitViolation" 193 "a193_PowershareMaxBrickVoltageViolation" 192 "a192_PowershareExternalChargeRegulation" 191 "a191_PowershareMinVoltageViolation" 190 "a190_PowershareMaxVoltageViolation" 189 "a189_PowershareDischargeCurrentViolation" 188 "a188_PowershareChargeCurrentViolation" 187 "a187_RippleHeatingEmergencyShutdown" 186 "a186_RippleHeatingChargeFault" 185 "a185_LifeModel_CyclingDcrGrowth_Change" 184 "a184_LifeModel_CyclingLoss_Change" 183 "a183_LifeModel_StoDcrGrowth_Change" 182 "a182_LifeModel_NoCurrentLoss_Change" 181 "a181_SW_Shunt_Over_Temperature" 180 "a180_SW_ECU_reset_blocked" 179 "a179_HvpGpoRequestActive" 178 "a178_SW_Uncontrolled_Regen_PwrB" 177 "a177_SW_Energy_Buffer_Size" 176 "a176_SW_GracefulPowerOff" 175 "a175_Charge_Failure_External" 174 "a174_SW_Charge_Failure" 173 "a173_FullPackEnergyDegraded" 172 "a172_SW_Isolation_Failure_In_Drive_Warning" 171 "a171_SW_Stack_Voltage_Sense" 170 "a170_SW_Limp_Mode" 169 "a169_SW_FC_Pack_Weld" 168 "a168_SW_FC_Full_Weld" 167 "a167_SW_FC_Partial_Weld" 166 "a166_SW_Pack_Full_Weld" 165 "a165_SW_Pack_Partial_Weld" 164 "a164_SW_Uncontrolled_Regen" 163 "a163_GridFormAborted" 162 "a162_SW_No_Power_For_Support" 161 "a161_SW_BMB_Vref_warning" 160 "a160_SW_FC_Ctr_Clean_Failed" 159 "a159_SW_HVP_ECU_Error" 158 "a158_SW_HVP_HVI_Comms" 157 "a157_SW_Hist_Update_Missed" 156 "a156_SW_BMB_Vref_bad" 155 "a155_SW_Weak_short_impedence" 154 "a154_SW_Brick_OV_Warning_Stop_Charge" 153 "a153_GridFormFaulted" 152 "a152_Isolation_In_Dc_Charge" 151 "a151_SW_external_isolation" 150 "a150_SW_Missing_Part_Number" 149 "a149_SW_Missing_Config_Block" 148 "a148_SW_Unsupported_BMB_ASIC_Type" 147 "a147_SW_SOC_High_Ah_Error" 146 "a146_SW_Brick_Overdischarged" 145 "a145_SW_SOC_Change" 144 "a144_Hvp_Config_Mismatch" 143 "a143_SW_CAC_Change" 142 "a142_SW_Isolation_Degradation" 141 "a141_SW_BMB_Status_Warning" 140 "a140_HW_BMB_Status_Fault" 139 "a139_SW_DC_Link_V_Irrational" 138 "a138_SW_Brick_OV_Warning" 137 "a137_SW_Brick_UV_Warning" 136 "a136_SW_Module_OT_Warning" 135 "a135_HW_BMB_Diagnostics_Failure" 134 "a134_SW_Delayed_Ctr_Off" 133 "a133_IO_CAN_Bus_Off" 132 "a132_HW_BMB_OTP_Uncorrctbl" 131 "a131_Bleed_FET_Failure" 130 "a130_IO_CAN_Error" 129 "a129_SW_VSH_Failure" 128 "a128_SW_shunt_MIA" 127 "a127_SW_shunt_SNA" 126 "a126_SW_Thermistor_Failure" 124 "a124_Battery_Coolant_Flood" 123 "a123_SW_Internal_Isolation" 122 "a122_SW_BMS_Therm_Irrational" 121 "a121_SW_NVRAM_Config_Error" 120 "a120_SW_Delta_SOC_User_Warning" 119 "a119_Fast_Open_Vsh_Detected" 118 "a118_SW_Delta_SOC_Weak_Short_Warning" 117 "a117_SW_Delta_SOC_Weak_Short" 115 "a115_Energy_Rubberbanding_Reset" 112 "a112_LifeModel_Discontinuity" 111 "a111_LifeModel_Spread_Change" 110 "a110_LifeModel_AvgOffset_Change" 109 "a109_HW_BMB_Mute_Status_Mismatch" 108 "a108_SW_BMB_Device_OT" 107 "a107_SW_Stack_Voltage_MIA" 106 "a106_SW_All_Module_Tsense" 105 "a105_SW_One_Module_Tsense" 100 "a100_ThermalEventSuspected" 99 "a099_SW_BMB_Communication" 98 "a098_SW_BMB_Data_Integrity_Loss" 97 "a097_SW_BMB_Over_CAN_Communication" 95 "a095_SW_UI_MIA" 94 "a094_SW_Drive_Inverter_MIA" 92 "a092_SW_ChargePort_Mia_On_Hvs" 91 "a091_SW_ChargePort_MIA" 90 "a090_SW_Gateway_MIA" 89 "a089_SW_VcFront_MIA" 88 "a088_SW_VcFront_MIA_InDrive" 87 "a087_SW_Feim_Test_Blocked" 86 "a086_SW_FC_Contactor_Mismatch" 85 "a085_SW_Pack_Contactor_Mismatch" 84 "a084_SW_Sleep_Wake_Aborted" 83 "a083_SW_Ctr_Close_Failure" 82 "a082_SW_Ctr_Force_Open" 81 "a081_SW_Ctr_Close_Blocked" 80 "a080_SW_Pack_Ctr_Impedance" 79 "a079_Max_Charge_Level_Exceeded" 78 "a078_Rapid_Dch_While_Charging" 77 "a077_SW_Charger_Regulation" 76 "a076_SW_Dch_While_Charging" 75 "a075_SW_Chg_Disable_Failure" 74 "a074_Max_Charge_Level_Reduced" 73 "a073_Unexpected_Loss_Of_Lv" 72 "a072_Module_Brick_Split" 71 "a071_SW_SM_TransCon_Not_Met" 70 "a070_BrickV_Imbalance_Limiting" 69 "a069_SW_Low_Power" 68 "a068_CAC_Imbalance_Limp" 67 "a067_CAC_Imbalance_Limiting" 66 "a066_SOC_Imbalance_Warning" 65 "a065_SW_CAC_Imbalance" 64 "a064_SW_SOC_Imbalance" 63 "a063_SW_ChargePort_Fault" 62 "a062_SW_BrickV_Imbalance" 61 "a061_SW_BrickV_Change" 60 "a060_SW_Leakage_Test_Failure" 59 "a059_SW_Pack_Voltage_Sensing" 58 "a058_SW_Bandolier_Model_Reset" 57 "a057_SW_Bandolier_Model_Warning" 56 "a056_SW_Standby_Supply_Fault" 55 "a055_SW_HvChain_Model_Fault" 54 "a054_SW_Ver_Supply_Fault" 52 "a052_SW_PCS_MIA" 51 "a051_SW_HVC_Vref_Bad" 50 "a050_SW_Brick_Voltage_MIA" 49 "a049_SW_Thermal_Event" 48 "a048_SW_Watch_Dog_Warning" 47 "a047_SW_Task_Stack_Overflow" 46 "a046_SW_Task_Stack_Usage" 45 "a045_SW_Exception" 44 "a044_SW_Assertion" 43 "a043_SW_Watch_Dog_Reset" 42 "a042_SW_MPU_Error" 41 "a041_SW_Destructive_Reset_Source" 40 "a040_SW_Watch_Dog_HW_Triggered" 39 "a039_SW_DC_Link_Over_Voltage" 37 "a037_SW_Flood_Port_Open" 36 "a036_SW_HvpHvilFault" 35 "a035_SW_Isolation" 34 "a034_SW_Passive_Isolation" 33 "a033_VoltageDeviation" 32 "a032_VoltageLoss" 31 "a031_AlertsSetDuringSleep" 30 "a030_Impedance_Deviation" 29 "a029_dSoc_Limiting" 28 "a028_ShuntAsicCurrentOffsetDeviation" 27 "a027_SW_Repeated_Isolation_Failure_In_Drive" 26 "a026_SW_HFCurrent_Anomaly" 25 "a025_SW_PwrBalance_Anomaly" 24 "a024_SW_Islanded_Brick" 23 "a023_SW_Stack_OV" 22 "a022_SW_Over_Current" 21 "a021_SW_Dr_Limits_Regulation" 20 "a020_SW_Brick_Instability" 19 "a019_SW_Module_OT" 18 "a018_SW_Brick_UV" 17 "a017_SW_Brick_OV" 16 "a016_Pack_Module_Id_Mismatch" 4 "a004_Cal_Vs_Serial_Birth_Date_Mismatch" 3 "a003_SW_Pack_Birth_Date_Missing" 2 "a002_Pack_Performance_Config_Mismatch" 1 "a001_Pack_Config_Mismatch" 0 "ALERT_DO_NOT_USE_ZERO" ;
VAL_ 1343 BMS_a090_GTWmessageTout 9 "UI_TRIPPLANNING" 8 "MCU_DRIVERLIMITS" 7 "GTW_CARCONFIG2" 6 "GTW_12VSTATUS" 5 "MCU_ODOMETER" 4 "GTW_CARCONFIG" 3 "GTW_PTNM" 2 "GTW_BODYSTATUS" 1 "MCU_POWER" 0 "GTW_COMMANDS" ;
VAL_ 1343 BMS_a098_bmbCommStatusTypeA 3 "BYPASSED" 2 "NOMINAL" 1 "BAD" 0 "MISSING" ;
VAL_ 1343 BMS_a098_bmbCommStatusTypeB 3 "BYPASSED" 2 "NOMINAL" 1 "BAD" 0 "MISSING" ;
VAL_ 1343 BMS_a099_bmbCommStatusTypeA 3 "BYPASSED" 2 "NOMINAL" 1 "BAD" 0 "MISSING" ;
VAL_ 1343 BMS_a099_bmbCommStatusTypeB 3 "BYPASSED" 2 "NOMINAL" 1 "BAD" 0 "MISSING" ;
VAL_ 1343 BMS_a099_bmbChainBreakType 5 "TAIL_BREAK" 4 "HEAD_BREAK" 3 "INVALID_BREAK" 2 "DOUBLE_BREAK" 1 "SINGLE_BREAK" 0 "NONE" ;
VAL_ 1343 BMS_a117_brickSoc2 1023 "SNA" ;
VAL_ 1343 BMS_a117_dSocAlpha 4095 "SNA" ;
VAL_ 1343 BMS_a118_brickSoc2 1023 "SNA" ;
VAL_ 1343 BMS_a118_dSocAlpha 4095 "SNA" ;
VAL_ 1343 BMS_a135_bmbDiagnosticsType 3 "UNUSED" 2 "BMB_DIAG_TEST5" 1 "BMB_DIAG_TESTA" 0 "BMB_DIAG_NONE" ;
VAL_ 1343 BMS_a140_faultType 162 "FAULT_COMM1_BY_UART_TR" 161 "FAULT_COMM1_BY_UART_RR" 160 "FAULT_COMM1_BY_COMMCLR_DET" 159 "FAULT_COMM1_BY_STOP_DET" 158 "FAULT_COMM2_BY_COML_TR" 157 "FAULT_COMM2_BY_COML_RR" 156 "FAULT_COMM2_BY_COML_RC" 155 "FAULT_COMM2_BY_COML_BIT" 154 "FAULT_COMM2_BY_COMH_TR" 153 "FAULT_COMM2_BY_COMH_RR" 152 "FAULT_COMM2_BY_COMH_RC" 151 "FAULT_COMM2_BY_COMH_BIT" 150 "FAULT_COMM3_BY_FCOMM_DET" 149 "FAULT_COMM3_BY_FTONE_DET" 148 "FAULT_COMM3_BY_HB_FAIL" 147 "FAULT_COMM3_BY_HB_FAST" 146 "FAULT_OTP_BY_DED_DET" 145 "FAULT_OTP_BY_SEC_DET" 144 "FAULT_OTP_BY_CUST_CRC" 143 "FAULT_OTP_BY_FACT_CRC" 142 "FAULT_OTP_BY_CUSTLDERR" 141 "FAULT_OTP_BY_FACTLDERR" 140 "FAULT_OTP_BY_GBLOVERR" 139 "FAULT_SYS_BY_LFO" 138 "FAULT_SYS_BY_SHUTDOWN_REC" 137 "FAULT_SYS_BY_GPIO" 136 "FAULT_SYS_BY_DRST" 135 "FAULT_SYS_BY_CTL" 134 "FAULT_SYS_BY_CTS" 133 "FAULT_SYS_BY_TSHUT" 132 "FAULT_SYS_BY_TWARN" 131 "FAULT_COMP_GPIO_BY_GPIO8_FAIL" 130 "FAULT_COMP_GPIO_BY_GPIO7_FAIL" 129 "FAULT_COMP_GPIO_BY_GPIO6_FAIL" 128 "FAULT_COMP_GPIO_BY_GPIO5_FAIL" 127 "FAULT_COMP_GPIO_BY_GPIO4_FAIL" 126 "FAULT_COMP_GPIO_BY_GPIO3_FAIL" 125 "FAULT_COMP_GPIO_BY_GPIO2_FAIL" 124 "FAULT_COMP_GPIO_BY_GPIO1_FAIL" 123 "FAULT_COMP_VCCB1_BY_CELL16_FAIL" 122 "FAULT_COMP_VCCB1_BY_CELL15_FAIL" 121 "FAULT_COMP_VCCB1_BY_CELL14_FAIL" 120 "FAULT_COMP_VCCB1_BY_CELL13_FAIL" 119 "FAULT_COMP_VCCB1_BY_CELL12_FAIL" 118 "FAULT_COMP_VCCB1_BY_CELL11_FAIL" 117 "FAULT_COMP_VCCB1_BY_CELL10_FAIL" 116 "FAULT_COMP_VCCB1_BY_CELL9_FAIL" 115 "FAULT_COMP_VCCB2_BY_CELL8_FAIL" 114 "FAULT_COMP_VCCB2_BY_CELL7_FAIL" 113 "FAULT_COMP_VCCB2_BY_CELL6_FAIL" 112 "FAULT_COMP_VCCB2_BY_CELL5_FAIL" 111 "FAULT_COMP_VCCB2_BY_CELL4_FAIL" 110 "FAULT_COMP_VCCB2_BY_CELL3_FAIL" 109 "FAULT_COMP_VCCB2_BY_CELL2_FAIL" 108 "FAULT_COMP_VCCB2_BY_CELL1_FAIL" 107 "FAULT_COMP_VCOW1_BY_VCOW16_FAIL" 106 "FAULT_COMP_VCOW1_BY_VCOW15_FAIL" 105 "FAULT_COMP_VCOW1_BY_VCOW14_FAIL" 104 "FAULT_COMP_VCOW1_BY_VCOW13_FAIL" 103 "FAULT_COMP_VCOW1_BY_VCOW12_FAIL" 102 "FAULT_COMP_VCOW1_BY_VCOW11_FAIL" 101 "FAULT_COMP_VCOW1_BY_VCOW10_FAIL" 100 "FAULT_COMP_VCOW1_BY_VCOW9_FAIL" 99 "FAULT_COMP_VCOW2_BY_VCOW8_FAIL" 98 "FAULT_COMP_VCOW2_BY_VCOW7_FAIL" 97 "FAULT_COMP_VCOW2_BY_VCOW6_FAIL" 96 "FAULT_COMP_VCOW2_BY_VCOW5_FAIL" 95 "FAULT_COMP_VCOW2_BY_VCOW4_FAIL" 94 "FAULT_COMP_VCOW2_BY_VCOW3_FAIL" 93 "FAULT_COMP_VCOW2_BY_VCOW2_FAIL" 92 "FAULT_COMP_VCOW2_BY_VCOW1_FAIL" 91 "FAULT_COMP_CBOW1_BY_CBOW16_FAIL" 90 "FAULT_COMP_CBOW1_BY_CBOW15_FAIL" 89 "FAULT_COMP_CBOW1_BY_CBOW14_FAIL" 88 "FAULT_COMP_CBOW1_BY_CBOW13_FAIL" 87 "FAULT_COMP_CBOW1_BY_CBOW12_FAIL" 86 "FAULT_COMP_CBOW1_BY_CBOW11_FAIL" 85 "FAULT_COMP_CBOW1_BY_CBOW10_FAIL" 84 "FAULT_COMP_CBOW1_BY_CBOW9_FAIL" 83 "FAULT_COMP_CBOW2_BY_CBOW8_FAIL" 82 "FAULT_COMP_CBOW2_BY_CBOW7_FAIL" 81 "FAULT_COMP_CBOW2_BY_CBOW6_FAIL" 80 "FAULT_COMP_CBOW2_BY_CBOW5_FAIL" 79 "FAULT_COMP_CBOW2_BY_CBOW4_FAIL" 78 "FAULT_COMP_CBOW2_BY_CBOW3_FAIL" 77 "FAULT_COMP_CBOW2_BY_CBOW2_FAIL" 76 "FAULT_COMP_CBOW2_BY_CBOW1_FAIL" 75 "FAULT_COMP_CBFET1_BY_CBFET16_FAIL" 74 "FAULT_COMP_CBFET1_BY_CBFET15_FAIL" 73 "FAULT_COMP_CBFET1_BY_CBFET14_FAIL" 72 "FAULT_COMP_CBFET1_BY_CBFET13_FAIL" 71 "FAULT_COMP_CBFET1_BY_CBFET12_FAIL" 70 "FAULT_COMP_CBFET1_BY_CBFET11_FAIL" 69 "FAULT_COMP_CBFET1_BY_CBFET10_FAIL" 68 "FAULT_COMP_CBFET1_BY_CBFET9_FAIL" 67 "FAULT_COMP_CBFET2_BY_CBFET8_FAIL" 66 "FAULT_COMP_CBFET2_BY_CBFET7_FAIL" 65 "FAULT_COMP_CBFET2_BY_CBFET6_FAIL" 64 "FAULT_COMP_CBFET2_BY_CBFET5_FAIL" 63 "FAULT_COMP_CBFET2_BY_CBFET4_FAIL" 62 "FAULT_COMP_CBFET2_BY_CBFET3_FAIL" 61 "FAULT_COMP_CBFET2_BY_CBFET2_FAIL" 60 "FAULT_COMP_CBFET2_BY_CBFET1_FAIL" 59 "FAULT_COMP_MISC_BY_COMP_ADC_ABORT" 58 "FAULT_COMP_MISC_BY_LPF_FAIL" 57 "FAULT_PWR1_BY_CVSS_OPEN" 56 "FAULT_PWR1_BY_DVSS_OPEN" 55 "FAULT_PWR1_BY_REFHM_OPEN" 54 "FAULT_PWR1_BY_CVDD_UV" 53 "FAULT_PWR1_BY_CVDD_OV" 52 "FAULT_PWR1_BY_DVDD_OV" 51 "FAULT_PWR1_BY_AVDD_OSC" 50 "FAULT_PWR1_BY_AVDD_OV" 49 "FAULT_PWR2_BY_PWRBIST_FAIL" 48 "FAULT_PWR2_BY_REFH_OSC" 47 "FAULT_PWR2_BY_NEG5V_UV" 46 "FAULT_PWR2_BY_TSREF_OSC" 45 "FAULT_PWR2_BY_TSREF_UV" 44 "FAULT_PWR2_BY_TSREF_OV" 43 "FAULT_PWR3_BY_AVDDUV_DRST" 42 "SEQ_ERROR_FAULT_CLEAR" 41 "SEQ_ERROR_FAULT_INJECT" 40 "SEQ_ERROR_CELL_RESUME" 39 "SEQ_ERROR_CELL_FREEZE" 38 "SEQ_ERROR_AUX_RESET" 37 "SEQ_ERROR_AUX_CLEAR" 36 "TEST_MODE" 35 "SUPPLY_RAIL" 34 "CLK_CHECK" 33 "DIGITAL_REF_OV" 32 "DIGITAL_REF_UV" 31 "ANALOG_REF_OV" 30 "ANALOG_REF_UV" 29 "POWER_BIST" 28 "GPIO_COMP" 27 "CBOW_COMP" 26 "VCOW_COMP" 25 "VCCB_COMP" 24 "VBG2_PLAUS" 23 "REFL_PLAUS" 22 "TSREF_PLAUS" 21 "VCM1_PLAUS" 20 "THERM_PLAUS" 19 "DIETEMP_PLAUS" 18 "STACKV_PLAUS" 17 "BRICKV_PLAUS" 16 "ADC_COMP_ABORT" 15 "LPF_FAULT_DET" 14 "AUX_MISC_DRDY" 13 "AUX_GPIO_DRDY" 12 "AUX_VCELL_DRDY" 11 "MAIN_ADC_DRDY" 10 "MAIN_ADC_LPF" 9 "POWER_FAULT" 8 "SYSTEM_FAULT" 7 "COMM_FAULT" 6 "OTP_FAULT" 5 "ADC_COMP_FAULT" 4 "ERROR_OTP_FAULT" 3 "ERROR_OTP_WARNING" 2 "ERROR_ADC_SEQUENCE" 1 "ERROR_POWER_RESET" 0 "ERROR_NONE" ;
VAL_ 1343 BMS_a142_mode 4 "VOLTAGE_SETTLING_MODE" 3 "FEIM_POSITIVE_MODE" 2 "FEIM_NEGATIVE_MODE" 1 "VEHICLE_ISOLATION_MODE" 0 "MODE_RESET" ;
VAL_ 1343 BMS_a145_brickChangeHystRatio 1023 "SNA" ;
VAL_ 1343 BMS_a146_state 10 "DIAG" 9 "SNA" 8 "TEST" 7 "WELD" 6 "FAULT" 5 "CLEAR_FAULT" 4 "FEIM" 3 "CHARGE" 2 "SUPPORT" 1 "DRIVE" 0 "STANDBY" ;
VAL_ 1343 BMS_a152_mode 4 "VOLTAGE_SETTLING_MODE" 3 "FEIM_POSITIVE_MODE" 2 "FEIM_NEGATIVE_MODE" 1 "VEHICLE_ISOLATION_MODE" 0 "MODE_RESET" ;
VAL_ 1343 BMS_a156_VrefStatus 3 "BYPASSED" 2 "NOMINAL" 1 "BAD" 0 "MISSING" ;
VAL_ 1343 BMS_a227_packCurrent -32768 "SNA" ;
VAL_ 1343 BMS_a227_dcChargeCurrentRequest -32768 "SNA" ;
